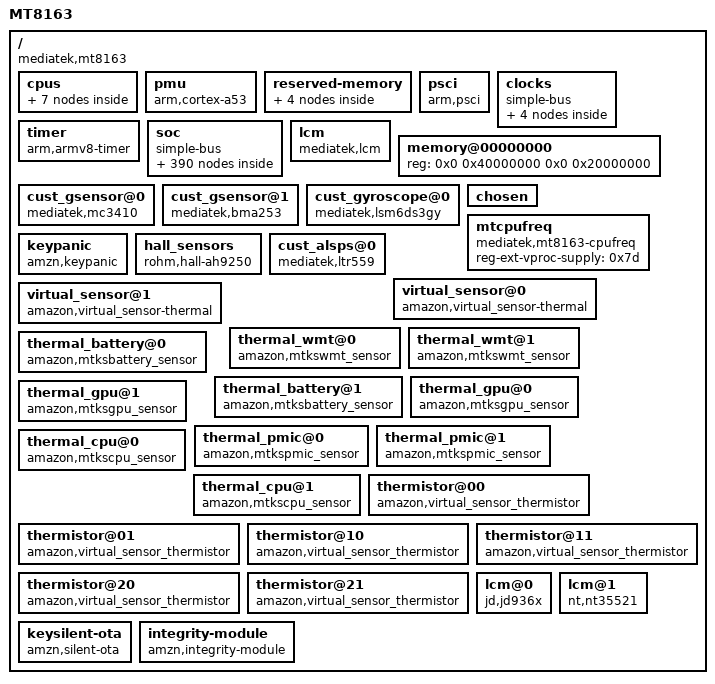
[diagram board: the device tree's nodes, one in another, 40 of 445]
/dts-v1/;

/ {
	model = "MT8163";
	compatible = "mediatek,mt8163";
	interrupt-parent = <0x1>;
	#address-cells = <0x2>;
	#size-cells = <0x2>;
	version = "evt";

	cpus {
		#address-cells = <0x1>;
		#size-cells = <0x0>;

		cpu@0 {
			device_type = "cpu";
			compatible = "arm,cortex-a53";
			reg = <0x0>;
			enable-method = "mt-boot";
			cpu-idle-states = <0x2 0x2 0x3 0x3 0x3>;
			cpu-release-addr = <0x0 0x40000200>;
			clock-frequency = "M|m";
			linux,phandle = <0x4>;
			phandle = <0x4>;
		};

		cpu@1 {
			device_type = "cpu";
			compatible = "arm,cortex-a53";
			reg = <0x1>;
			enable-method = "mt-boot";
			cpu-idle-states = <0x2 0x2 0x3 0x3 0x3>;
			cpu-release-addr = <0x0 0x40000200>;
			clock-frequency = "M|m";
			linux,phandle = <0x5>;
			phandle = <0x5>;
		};

		cpu@2 {
			device_type = "cpu";
			compatible = "arm,cortex-a53";
			reg = <0x2>;
			enable-method = "mt-boot";
			cpu-idle-states = <0x2 0x2 0x3 0x3 0x3>;
			cpu-release-addr = <0x0 0x40000200>;
			clock-frequency = "M|m";
			linux,phandle = <0x6>;
			phandle = <0x6>;
		};

		cpu@3 {
			device_type = "cpu";
			compatible = "arm,cortex-a53";
			reg = <0x3>;
			enable-method = "mt-boot";
			cpu-idle-states = <0x2 0x2 0x3 0x3 0x3>;
			cpu-release-addr = <0x0 0x40000200>;
			clock-frequency = "M|m";
			linux,phandle = <0x7>;
			phandle = <0x7>;
		};

		idle-states {
			entry-method = "arm,psci";

			cpu-sleep-0-0 {
				compatible = "arm,idle-state";
				arm,psci-suspend-param = <0x10000>;
				entry-latency-us = <0x258>;
				exit-latency-us = <0x258>;
				min-residency-us = <0x4b0>;
				linux,phandle = <0x3>;
				phandle = <0x3>;
			};

			cluster-sleep-0 {
				compatible = "arm,idle-state";
				arm,psci-suspend-param = <0x2010000>;
				entry-latency-us = <0x320>;
				exit-latency-us = <0x3e8>;
				min-residency-us = <0x7d0>;
				linux,phandle = <0x2>;
				phandle = <0x2>;
			};
		};
	};

	pmu {
		compatible = "arm,cortex-a53";
		interrupts = <0x0 0x8 0x8 0x0 0x9 0x8 0x0 0xa 0x8 0x0 0xb 0x8>;
		interrupt-affinity = <0x4 0x5 0x6 0x7>;
	};

	reserved-memory {
		#address-cells = <0x2>;
		#size-cells = <0x2>;
		ranges;

		mdump-reserved-memory@4bd00000 {
			compatible = "amazon,mdump-reserve-memory";
			reg = <0x0 0x4bd00000 0x0 0x300000>;
		};

		atf-reserved-memory@43000000 {
			compatible = "mediatek,mt8163-atf-reserved-memory";
			no-map;
			reg = <0x0 0x43000000 0x0 0x30000>;
		};

		ram_console-reserved-memory@44400000 {
			compatible = "mediatek,ram_console";
			reg = <0x0 0x44400000 0x0 0x200000>;
		};

		consys-reserve-memory {
			compatible = "mediatek,consys-reserve-memory";
			no-map;
			size = <0x0 0x200000>;
			alignment = <0x0 0x200000>;
		};
	};

	psci {
		compatible = "arm,psci";
		method = "smc";
		cpu_suspend = <0x84000001>;
		cpu_off = <0x84000002>;
		cpu_on = <0x84000003>;
		affinity_info = <0x84000004>;
	};

	clocks {
		#address-cells = <0x2>;
		#size-cells = <0x2>;
		compatible = "simple-bus";
		ranges;

		clk_null {
			compatible = "fixed-clock";
			#clock-cells = <0x0>;
			clock-frequency = <0x0>;
			linux,phandle = <0x40>;
			phandle = <0x40>;
		};

		clk26m {
			compatible = "fixed-clock";
			#clock-cells = <0x0>;
			clock-frequency = <0x18cba80>;
			linux,phandle = <0x34>;
			phandle = <0x34>;
		};

		clk32k {
			compatible = "fixed-clock";
			#clock-cells = <0x0>;
			clock-frequency = <0x7d00>;
		};

		dummy26m {
			compatible = "fixed-clock";
			clock-frequency = <0x18cba80>;
			#clock-cells = <0x0>;
		};
	};

	timer {
		compatible = "arm,armv8-timer";
		interrupt-parent = <0x8>;
		interrupts = <0x1 0xd 0xf08 0x1 0xe 0xf08 0x1 0xb 0xf08 0x1 0xa 0xf08>;
		clock-frequency = <0xc65d40>;
	};

	soc {
		#address-cells = <0x2>;
		#size-cells = <0x2>;
		compatible = "simple-bus";
		ranges;

		chipid@08000000 {
			compatible = "mediatek,mt8163-chipid";
			reg = <0x0 0x8000000 0x0 0x10>;
		};

		topckgen@10000000 {
			compatible = "mediatek,mt8163-topckgen";
			reg = <0x0 0x10000000 0x0 0x1000>;
			#clock-cells = <0x1>;
			linux,phandle = <0xa>;
			phandle = <0xa>;
		};

		infracfg@10001000 {
			compatible = "mediatek,mt8163-infracfg", "syscon";
			reg = <0x0 0x10001000 0x0 0x1000>;
			#clock-cells = <0x1>;
			#reset-cells = <0x1>;
			linux,phandle = <0x9>;
			phandle = <0x9>;
		};

		syscfg_pctl_a@10005000 {
			compatible = "mediatek,mt8163-pctl-a-syscfg", "syscon";
			reg = <0x0 0x10005000 0x0 0x1000>;
			linux,phandle = <0xb>;
			phandle = <0xb>;
		};

		toprgu@10007000 {
			compatible = "mediatek,mt8163-rgu";
			reg = <0x0 0x10007000 0x0 0x1000>;
			interrupts = <0x0 0x80 0x2>;
			#reset-cells = <0x1>;
		};

		apxgpt@10008000 {
			compatible = "mediatek,mt8163-apxgpt";
			reg = <0x0 0x10008000 0x0 0x1000>;
			interrupts = <0x0 0x98 0x8>;
			clocks = <0x9 0x6 0x9 0x46 0xa 0x60>;
			clock-names = "bus", "clk13m", "rtc_sel";
		};

		pmu {
			compatible = "arm,armv8-pmuv3";
			interrupts = <0x0 0x8 0x8 0x0 0x9 0x8 0x0 0xa 0x8 0x0 0xb 0x8>;
			interrupt-affinity = <0x4 0x5 0x6 0x7>;
		};

		pinctrl@10005000 {
			compatible = "mediatek,mt8163-pinctrl";
			reg = <0x0 0x1000b000 0x0 0x1000>;
			mediatek,pctl-regmap = <0xb>;
			pins-are-numbered;
			gpio-controller;
			#gpio-cells = <0x2>;
			interrupt-controller;
			#interrupt-cells = <0x2>;
			interrupts = <0x0 0x99 0x4 0x0 0x9a 0x4 0x0 0x9b 0x4>;
			pinctrl-names = "default";
			pinctrl-0 = <0xc>;
			linux,phandle = <0xd>;
			phandle = <0xd>;

			spi1 {
				linux,phandle = <0x2d>;
				phandle = <0x2d>;

				pins_spi {
					pinmux = <0x3501 0x3601 0x3701 0x3801>;
					bias-disable;
					drive-strength = <0x2>;
				};
			};

			uart0gpiodefault {
				linux,phandle = <0xf>;
				phandle = <0xf>;
			};

			uart0_rx_set {
				linux,phandle = <0x10>;
				phandle = <0x10>;

				pins_cmd_dat {
					pinmux = <0x4f01>;
				};
			};

			uart0_rx_clear {
				linux,phandle = <0x11>;
				phandle = <0x11>;

				pins_cmd_dat {
					pinmux = <0x4f00>;
					slew-rate = <0x1>;
					output-high;
				};
			};

			uart0_tx_set {
				linux,phandle = <0x12>;
				phandle = <0x12>;

				pins_cmd_dat {
					pinmux = <0x5001>;
				};
			};

			uart0_tx_clear {
				linux,phandle = <0x13>;
				phandle = <0x13>;

				pins_cmd_dat {
					pinmux = <0x5000>;
					slew-rate = <0x1>;
					output-high;
				};
			};

			uart1gpiodefault {
				linux,phandle = <0x14>;
				phandle = <0x14>;
			};

			uart1_rx_set {
				linux,phandle = <0x15>;
				phandle = <0x15>;

				pins_cmd_dat {
					pinmux = <0x5101>;
				};
			};

			uart1_rx_clear {
				linux,phandle = <0x16>;
				phandle = <0x16>;

				pins_cmd_dat {
					pinmux = <0x5100>;
					slew-rate = <0x1>;
					output-high;
				};
			};

			uart1_tx_set {
				linux,phandle = <0x17>;
				phandle = <0x17>;

				pins_cmd_dat {
					pinmux = <0x5201>;
				};
			};

			uart1_tx_clear {
				linux,phandle = <0x18>;
				phandle = <0x18>;

				pins_cmd_dat {
					pinmux = <0x5200>;
					slew-rate = <0x1>;
					output-high;
				};
			};

			uart2gpiodefault {
				linux,phandle = <0x19>;
				phandle = <0x19>;
			};

			uart2_rx_set {
				linux,phandle = <0x1a>;
				phandle = <0x1a>;

				pins_cmd_dat {
					pinmux = <0xe01>;
				};
			};

			uart2_rx_clear {
				linux,phandle = <0x1b>;
				phandle = <0x1b>;

				pins_cmd_dat {
					pinmux = <0xe00>;
					slew-rate = <0x1>;
					output-high;
				};
			};

			uart2_tx_set {
				linux,phandle = <0x1c>;
				phandle = <0x1c>;

				pins_cmd_dat {
					pins = <0xf01>;
				};
			};

			uart2_tx_clear {
				linux,phandle = <0x1d>;
				phandle = <0x1d>;

				pins_cmd_dat {
					pinmux = <0xf00>;
					slew-rate = <0x1>;
					output-high;
				};
			};

			uart3gpiodefault {
				linux,phandle = <0x1e>;
				phandle = <0x1e>;
			};

			uart3_rx_set {
				linux,phandle = <0x1f>;
				phandle = <0x1f>;

				pins_cmd_dat {
					pinmux = <0x1001>;
				};
			};

			uart3_rx_clear {
				linux,phandle = <0x20>;
				phandle = <0x20>;

				pins_cmd_dat {
					pinmux = <0x1000>;
					slew-rate = <0x1>;
					output-high;
				};
			};

			uart3_tx_set {
				linux,phandle = <0x21>;
				phandle = <0x21>;

				pins_cmd_dat {
					pinmux = <0x1101>;
				};
			};

			uart3_tx_clear {
				linux,phandle = <0x22>;
				phandle = <0x22>;

				pins_cmd_dat {
					pinmux = <0x1100>;
					slew-rate = <0x1>;
					output-high;
				};
			};

			pinconf_default {
				linux,phandle = <0xc>;
				phandle = <0xc>;
			};

			eint4default {
				linux,phandle = <0x6c>;
				phandle = <0x6c>;
			};

			rt551x_irq_init {
				linux,phandle = <0x24>;
				phandle = <0x24>;

				pins_cmd_dat {
					pins = <0x1c00>;
					bias-pull-down;
				};
			};

			eint4 {
				linux,phandle = <0x6d>;
				phandle = <0x6d>;

				pins_cmd_dat {
					pins = <0x1a00>;
					bias-disable;
				};
			};

			bq24297_int_pin {
				linux,phandle = <0x28>;
				phandle = <0x28>;

				pins_cmd_dat {
					pinmux = <0x2b00>;
					input-enable;
					bias-pull-up;
				};
			};

			bq24297_chg_en_pin {
				linux,phandle = <0x27>;
				phandle = <0x27>;

				pins_cmd_dat {
					pins = <0x1800>;
					slew-rate = <0x1>;
					bias-disable;
					output-low;
				};
			};

			alspspincfg {
				linux,phandle = <0x75>;
				phandle = <0x75>;

				pins_cmd_dat {
					pins = <0x2000>;
					slew-rate = <0x0>;
					bias-pull-up = <0x0>;
				};
			};

			alspsdefaultcfg {
				linux,phandle = <0x74>;
				phandle = <0x74>;
			};

			audiodefault {
			};

			audexamphigh {
				linux,phandle = <0x3b>;
				phandle = <0x3b>;

				pins_cmd0_dat {
					pins = <0x1e00>;
					slew-rate = <0x1>;
					output-high;
				};

				pins_cmd1_dat {
					pins = <0x1d00>;
					slew-rate = <0x1>;
					output-high;
				};
			};

			audexamplow {
				linux,phandle = <0x3c>;
				phandle = <0x3c>;

				pins_cmd0_dat {
					pins = <0x1e00>;
					slew-rate = <0x1>;
					output-low;
				};

				pins_cmd1_dat {
					pins = <0x1d00>;
					slew-rate = <0x1>;
					output-low;
				};
			};

			audhpamphigh {
				linux,phandle = <0x3d>;
				phandle = <0x3d>;

				pins_cmd_dat {
					pins = <0x1b00>;
					slew-rate = <0x1>;
					output-high;
				};
			};

			audhpamplow {
				linux,phandle = <0x3e>;
				phandle = <0x3e>;

				pins_cmd_dat {
					pins = <0x1b00>;
					slew-rate = <0x1>;
					output-low;
				};
			};

			audexampgain0 {
				linux,phandle = <0x36>;
				phandle = <0x36>;

				pins_cmd_dat {
					pins = <0x8e00>;
					slew-rate = <0x1>;
					output-low;
				};
			};

			audexampgain1 {
				linux,phandle = <0x3f>;
				phandle = <0x3f>;

				pins_cmd_dat {
					pins = <0x8e00>;
					slew-rate = <0x1>;
					output-high;
				};
			};

			audFSA8409off {
				linux,phandle = <0x6e>;
				phandle = <0x6e>;

				pins_cmd_dat {
					pins = <0x8e00>;
					slew-rate = <0x1>;
					output-low;
				};
			};

			audFSA8409on {
				linux,phandle = <0x6f>;
				phandle = <0x6f>;

				pins_cmd_dat {
					pins = <0x8e00>;
					slew-rate = <0x1>;
					output-high;
				};
			};

			audi2s1mode0 {
				linux,phandle = <0x39>;
				phandle = <0x39>;

				pins_cmd0_dat {
					pins = <0x2e00>;
				};

				pins_cmd1_dat {
					pins = <0x2f00>;
				};

				pins_cmd2_dat {
					pins = <0x3000>;
				};
			};

			audi2s1mode1 {
				linux,phandle = <0x3a>;
				phandle = <0x3a>;

				pins_cmd0_dat {
					pins = <0x2e02>;
				};

				pins_cmd1_dat {
					pins = <0x2f02>;
				};

				pins_cmd2_dat {
					pins = <0x3002>;
				};
			};

			pmicclkmode0 {
				linux,phandle = <0x37>;
				phandle = <0x37>;

				pins_cmd0_dat {
					pins = <0x700>;
				};

				pins_cmd1_dat {
					pins = <0x800>;
				};

				pins_cmd2_dat {
					pins = <0x900>;
				};
			};

			pmicclkmode1 {
				linux,phandle = <0x38>;
				phandle = <0x38>;

				pins_cmd0_dat {
					pins = <0x701>;
				};

				pins_cmd1_dat {
					pins = <0x801>;
				};

				pins_cmd2_dat {
					pins = <0x901>;
				};
			};

			camdefault {
				linux,phandle = <0x4e>;
				phandle = <0x4e>;
			};

			cam0@0 {
				linux,phandle = <0x4f>;
				phandle = <0x4f>;

				pins_cmd_dat {
					pins = <0x1200>;
					slew-rate = <0x1>;
					output-low;
				};
			};

			cam0@1 {
				linux,phandle = <0x50>;
				phandle = <0x50>;

				pins_cmd_dat {
					pins = <0x1200>;
					slew-rate = <0x1>;
					output-high;
				};
			};

			cam0@2 {
				linux,phandle = <0x51>;
				phandle = <0x51>;

				pins_cmd_dat {
					pins = <0x1400>;
					slew-rate = <0x1>;
					output-low;
				};
			};

			cam0@3 {
				linux,phandle = <0x52>;
				phandle = <0x52>;

				pins_cmd_dat {
					pins = <0x1400>;
					slew-rate = <0x1>;
					output-high;
				};
			};

			cam1@0 {
				linux,phandle = <0x53>;
				phandle = <0x53>;

				pins_cmd_dat {
					pins = <0x1300>;
					slew-rate = <0x1>;
					output-low;
				};
			};

			cam1@1 {
				linux,phandle = <0x54>;
				phandle = <0x54>;

				pins_cmd_dat {
					pins = <0x1300>;
					slew-rate = <0x1>;
					output-high;
				};
			};

			cam1@2 {
				linux,phandle = <0x55>;
				phandle = <0x55>;

				pins_cmd_dat {
					pins = <0x1500>;
					slew-rate = <0x1>;
					output-low;
				};
			};

			cam1@3 {
				linux,phandle = <0x56>;
				phandle = <0x56>;

				pins_cmd_dat {
					pins = <0x1500>;
					slew-rate = <0x1>;
					output-high;
				};
			};

			cam_pin_rdn0 {
				linux,phandle = <0x58>;
				phandle = <0x58>;

				pins_cmd_dat {
					pins = <0x6501>;
				};
			};

			cam_pin_rdp0 {
				linux,phandle = <0x59>;
				phandle = <0x59>;

				pins_cmd_dat {
					pins = <0x6601>;
				};
			};

			cam_pin_rcn {
				linux,phandle = <0x5a>;
				phandle = <0x5a>;

				pins_cmd_dat {
					pins = <0x6901>;
				};
			};

			cam_pin_rcp {
				linux,phandle = <0x5b>;
				phandle = <0x5b>;

				pins_cmd_dat {
					pins = <0x6a01>;
				};
			};

			cam_pin_rcn_a {
				linux,phandle = <0x5c>;
				phandle = <0x5c>;

				pins_cmd_dat {
					pins = <0x6f01>;
				};
			};

			cam_pin_rcp_a {
				linux,phandle = <0x5d>;
				phandle = <0x5d>;

				pins_cmd_dat {
					pins = <0x7001>;
				};
			};

			cam_pin_rdn0_a {
				linux,phandle = <0x5e>;
				phandle = <0x5e>;

				pins_cmd_dat {
					pins = <0x7301>;
				};
			};

			cam_pin_rdp0_a {
				linux,phandle = <0x5f>;
				phandle = <0x5f>;

				pins_cmd_dat {
					pins = <0x7401>;
				};
			};

			cam_pin_mclk {
				linux,phandle = <0x57>;
				phandle = <0x57>;

				pins_cmd_dat {
					pins = <0x7701>;
				};
			};

			default {
				linux,phandle = <0x63>;
				phandle = <0x63>;
			};

			eint0default {
				linux,phandle = <0x70>;
				phandle = <0x70>;

				pins_cmd_dat {
					pins = <0x1600>;
					slew-rate = <0x0>;
					bias-disable;
				};
			};

			eint@0 {
				linux,phandle = <0x2a>;
				phandle = <0x2a>;

				pins_cmd_dat {
					pins = <0x1600>;
					slew-rate = <0x0>;
					bias-disable;
				};
			};

			eintoutput0 {
				linux,phandle = <0x29>;
				phandle = <0x29>;

				pins_cmd_dat {
					pins = <0x1600>;
					slew-rate = <0x1>;
					output-low;
				};
			};

			eintoutput1 {
				linux,phandle = <0x71>;
				phandle = <0x71>;

				pins_cmd_dat {
					pins = <0x1600>;
					slew-rate = <0x1>;
					output-high;
				};
			};

			rstoutput0 {
				linux,phandle = <0x72>;
				phandle = <0x72>;

				pins_cmd_dat {
					pins = <0x2d00>;
					slew-rate = <0x1>;
					output-low;
				};
			};

			rstoutput1 {
				linux,phandle = <0x73>;
				phandle = <0x73>;

				pins_cmd_dat {
					pins = <0x2d00>;
					slew-rate = <0x1>;
					output-high;
				};
			};

			iddig_irq_init {
				linux,phandle = <0x30>;
				phandle = <0x30>;

				pins_cmd_dat {
					pins = <0x2600>;
					bias-pull-up;
				};
			};

			iddig_irq_low {
				linux,phandle = <0x31>;
				phandle = <0x31>;

				pins_cmd_dat {
					pins = <0x2600>;
					bias-pull-down;
				};
			};

			iddig_irq_high {
				linux,phandle = <0x32>;
				phandle = <0x32>;

				pins_cmd_dat {
					pins = <0x2600>;
					bias-pull-up;
				};
			};

			gpslna@0 {
				linux,phandle = <0x64>;
				phandle = <0x64>;

				pins_cmd_dat {
					pinmux = <0x600>;
					slew-rate = <0x0>;
					bias-disable;
					output-low;
				};
			};

			gpslna@1 {
				linux,phandle = <0x65>;
				phandle = <0x65>;

				pins_cmd_dat {
					pinmux = <0x600>;
					slew-rate = <0x1>;
					output-high;
				};
			};

			gpslna@2 {
				linux,phandle = <0x66>;
				phandle = <0x66>;

				pins_cmd_dat {
					pinmux = <0x600>;
					slew-rate = <0x1>;
					output-low;
				};
			};

			wifireset@0 {
				linux,phandle = <0x67>;
				phandle = <0x67>;

				pins_reset_dat {
					pinmux = <0x3c01 0x3f01 0x4001 0x4101>;
					input-enable;
					bias-pull-up;
				};
			};

			i2c0@0 {
				linux,phandle = <0x23>;
				phandle = <0x23>;

				pins1 {
					pinmux = <0x4b01 0x4c01>;
					bias-disable;
				};
			};

			i2c1@0 {
				linux,phandle = <0x25>;
				phandle = <0x25>;

				pins1 {
					pinmux = <0x3901 0x3a01>;
					bias-disable;
				};
			};

			i2c2@0 {
				linux,phandle = <0x26>;
				phandle = <0x26>;

				pins1 {
					pinmux = <0x4d01 0x4e01>;
					bias-disable;
				};
			};

			lcm_gpio@49_high {
				linux,phandle = <0x76>;
				phandle = <0x76>;

				pins_cmd_dat {
					pins = <0x3100>;
					slew-rate = <0x1>;
					output-high;
				};
			};

			lcm_gpio@49_low {
				linux,phandle = <0x77>;
				phandle = <0x77>;

				pins_cmd_dat {
					pins = <0x3100>;
					slew-rate = <0x1>;
					output-low;
				};
			};

			lcm_gpio@48_high {
				linux,phandle = <0x78>;
				phandle = <0x78>;

				pins_cmd_dat {
					pins = <0x3000>;
					slew-rate = <0x1>;
					output-high;
				};
			};

			lcm_gpio@48_low {
				linux,phandle = <0x79>;
				phandle = <0x79>;

				pins_cmd_dat {
					pins = <0x3000>;
					slew-rate = <0x1>;
					output-low;
				};
			};

			lcm_gpio@50_high {
				linux,phandle = <0x7a>;
				phandle = <0x7a>;

				pins_cmd_dat {
					pins = <0x3200>;
					slew-rate = <0x1>;
					output-high;
				};
			};

			lcm_gpio@50_low {
				linux,phandle = <0x7b>;
				phandle = <0x7b>;

				pins_cmd_dat {
					pins = <0x3200>;
					slew-rate = <0x1>;
					output-low;
				};
			};

			mmc0default {
				linux,phandle = <0x41>;
				phandle = <0x41>;

				pins_cmd_dat {
					pinmux = <0x8901 0x8801 0x8701 0x8601 0x8201 0x8101 0x8001 0x7f01 0x8401>;
					input-enable;
					bias-pull-up;
				};

				pins_clk {
					pinmux = <0x8501>;
					bias-pull-down;
				};

				pins_rst {
					pinmux = <0x8301>;
					bias-pull-up;
				};
			};

			mmc0@0 {
				linux,phandle = <0x42>;
				phandle = <0x42>;

				pins_cmd_dat {
					pinmux = <0x8901 0x8801 0x8701 0x8601 0x8201 0x8101 0x8001 0x7f01 0x8401>;
					input-enable;
					drive-strength = <0x6>;
					bias-pull-up = <0x65>;
				};

				pins_clk {
					pinmux = <0x8501>;
					drive-strength = <0x6>;
					bias-pull-down = <0x65>;
				};

				pins_rst {
					pinmux = <0x8301>;
					bias-pull-up;
				};
			};

			mmc1default {
				linux,phandle = <0x45>;
				phandle = <0x45>;

				pins_cmd_dat {
					pinmux = <0x7b01 0x7c01 0x7d01 0x7e01 0x7901>;
					input-enable;
					drive-strength = <0x6>;
					bias-pull-up = <0x65>;
				};

				pins_clk {
					pinmux = <0x7a01>;
					drive-strength = <0x6>;
					bias-pull-down = <0x66>;
				};

				pins_insert {
					pinmux = <0x3400>;
					bias-pull-up;
				};
			};

			mmc1@0 {
				linux,phandle = <0x46>;
				phandle = <0x46>;

				pins_cmd_dat {
					pinmux = <0x7b01 0x7c01 0x7d01 0x7e01 0x7901>;
					input-enable;
					drive-strength = <0x8>;
					bias-pull-up = <0x66>;
				};

				pins_clk {
					pinmux = <0x7a01>;
					drive-strength = <0x8>;
					bias-pull-down = <0x66>;
				};
			};
		};

		dramco@10004000 {
			compatible = "mediatek,mt8163-dramco", "mediatek,dramco";
			reg = <0x0 0x10004000 0x0 0x1000>;
		};

		scpsys@10006000 {
			compatible = "mediatek,mt8163-scpsys", "syscon";
			#power-domain-cells = <0x1>;
			reg = <0x0 0x10006000 0x0 0x1000>;
			interrupts = <0x0 0xa3 0x8 0x0 0xa4 0x8 0x0 0xa5 0x8 0x0 0xa6 0x8 0x0 0xa7 0x8 0x0 0xa8 0x8 0x0 0xa9 0x8 0x0 0xaa 0x8>;
			infracfg = <0x9>;
			clocks = <0xa 0x46 0xa 0x43>;
			clock-names = "mfg", "mm";
			linux,phandle = <0x35>;
			phandle = <0x35>;
		};

		hacc@1000a000 {
			compatible = "mediatek,hacc";
			reg = <0x0 0x1000a000 0x0 0x1000>;
			clocks = <0x9 0x5>;
			clock-names = "main";
		};

		apmixedsys@1000c000 {
			compatible = "mediatek,mt8163-apmixedsys";
			reg = <0x0 0x1000c000 0x0 0x1000>;
			#clock-cells = <0x1>;
			linux,phandle = <0x2e>;
			phandle = <0x2e>;
		};

		fhctl@1000cf00 {
			compatible = "mediatek,mt8163-fhctl";
			reg = <0x0 0x1000cf00 0x0 0x100>;
		};

		pwrap@1000d000 {
			compatible = "mediatek,mt8163-pwrap";
			reg = <0x0 0x1000d000 0x0 0x1000>;
			reg-names = "pwrap-base";
			interrupts = <0x0 0xa1 0x4>;
			clocks = <0xa 0x51 0x9 0x1>;
			clock-names = "spi", "pwrap";

			mt6323 {
				compatible = "mediatek,mt6323";

				pmicmt6323 {
					compatible = "mediatek,mt6323-pmic";
					interrupt-parent = <0xd>;
					interrupts = <0x18 0x4>;
				};

				regulators {
					compatible = "mediatek,mt6323-regulator";

					buck_vproc {
						regulator-name = "vproc";
						regulator-min-microvolt = <0xaae60>;
						regulator-max-microvolt = <0x149970>;
						regulator-ramp-delay = <0x30d4>;
						regulator-always-on;
						regulator-boot-on;
					};

					buck_vsys {
						regulator-name = "vsys";
						regulator-min-microvolt = <0x155cc0>;
						regulator-max-microvolt = <0x2d95ec>;
						regulator-ramp-delay = <0x61a8>;
						regulator-always-on;
						regulator-boot-on;
					};

					buck_vpa {
						regulator-name = "vpa";
						regulator-min-microvolt = <0x7a120>;
						regulator-max-microvolt = <0x37b1d0>;
					};

					ldo_vtcxo {
						regulator-name = "vtcxo";
						regulator-min-microvolt = <0x2ab980>;
						regulator-max-microvolt = <0x2ab980>;
						regulator-enable-ramp-delay = <0x5a>;
						regulator-always-on;
						regulator-boot-on;
					};

					ldo_vcn28 {
						regulator-name = "vcn28";
						regulator-min-microvolt = <0x2ab980>;
						regulator-max-microvolt = <0x2ab980>;
						regulator-enable-ramp-delay = <0xb9>;
						linux,phandle = <0x69>;
						phandle = <0x69>;
					};

					ldo_vcn33_bt {
						regulator-name = "vcn33_bt";
						regulator-min-microvolt = <0x325aa0>;
						regulator-max-microvolt = <0x36ee80>;
						regulator-enable-ramp-delay = <0xb9>;
						linux,phandle = <0x6a>;
						phandle = <0x6a>;
					};

					ldo_vcn33_wifi {
						regulator-name = "vcn33_wifi";
						regulator-min-microvolt = <0x325aa0>;
						regulator-max-microvolt = <0x36ee80>;
						regulator-enable-ramp-delay = <0xb9>;
						linux,phandle = <0x6b>;
						phandle = <0x6b>;
					};

					ldo_va {
						regulator-name = "va";
						regulator-min-microvolt = <0x2ab980>;
						regulator-max-microvolt = <0x2ab980>;
						regulator-enable-ramp-delay = <0xd8>;
						regulator-always-on;
						regulator-boot-on;
					};

					ldo_vcama {
						regulator-name = "vcama";
						regulator-min-microvolt = <0x16e360>;
						regulator-max-microvolt = <0x2ab980>;
						regulator-enable-ramp-delay = <0xd8>;
						linux,phandle = <0x4b>;
						phandle = <0x4b>;
					};

					ldo_vio28 {
						regulator-name = "vio28";
						regulator-min-microvolt = <0x2ab980>;
						regulator-max-microvolt = <0x2ab980>;
						regulator-enable-ramp-delay = <0xd8>;
						regulator-always-on;
						regulator-boot-on;
					};

					ldo_vusb {
						regulator-name = "vusb";
						regulator-min-microvolt = <0x325aa0>;
						regulator-max-microvolt = <0x325aa0>;
						regulator-enable-ramp-delay = <0xd8>;
						regulator-boot-on;
						linux,phandle = <0x2f>;
						phandle = <0x2f>;
					};

					ldo_vmc {
						regulator-name = "vmc";
						regulator-min-microvolt = <0x1b7740>;
						regulator-max-microvolt = <0x325aa0>;
						regulator-enable-ramp-delay = <0x24>;
						regulator-boot-on;
						linux,phandle = <0x48>;
						phandle = <0x48>;
					};

					ldo_vmch {
						regulator-name = "vmch";
						regulator-min-microvolt = <0x2dc6c0>;
						regulator-max-microvolt = <0x325aa0>;
						regulator-enable-ramp-delay = <0x24>;
						regulator-boot-on;
						linux,phandle = <0x47>;
						phandle = <0x47>;
					};

					ldo_vemc3v3 {
						regulator-name = "vemc3v3";
						regulator-min-microvolt = <0x2dc6c0>;
						regulator-max-microvolt = <0x325aa0>;
						regulator-enable-ramp-delay = <0x24>;
						regulator-boot-on;
						linux,phandle = <0x43>;
						phandle = <0x43>;
					};

					ldo_vgp1 {
						regulator-name = "vgp1";
						regulator-min-microvolt = <0x124f80>;
						regulator-max-microvolt = <0x325aa0>;
						regulator-enable-ramp-delay = <0xd8>;
						linux,phandle = <0x60>;
						phandle = <0x60>;
					};

					ldo_vgp2 {
						regulator-name = "vgp2";
						regulator-min-microvolt = <0x124f80>;
						regulator-max-microvolt = <0x2dc6c0>;
						regulator-enable-ramp-delay = <0xd8>;
						linux,phandle = <0x2b>;
						phandle = <0x2b>;
					};

					ldo_vgp3 {
						regulator-name = "vgp3";
						regulator-min-microvolt = <0x124f80>;
						regulator-max-microvolt = <0x1b7740>;
						regulator-enable-ramp-delay = <0xd8>;
						linux,phandle = <0x7c>;
						phandle = <0x7c>;
					};

					ldo_vcn18 {
						regulator-name = "vcn18";
						regulator-min-microvolt = <0x1b7740>;
						regulator-max-microvolt = <0x1b7740>;
						regulator-enable-ramp-delay = <0xd8>;
						linux,phandle = <0x68>;
						phandle = <0x68>;
					};

					ldo_vsim1 {
						regulator-name = "vsim1";
						regulator-min-microvolt = <0x1b7740>;
						regulator-max-microvolt = <0x2dc6c0>;
						regulator-enable-ramp-delay = <0xd8>;
					};

					ldo_vsim2 {
						regulator-name = "vsim2";
						regulator-min-microvolt = <0x1b7740>;
						regulator-max-microvolt = <0x2dc6c0>;
						regulator-enable-ramp-delay = <0xd8>;
					};

					ldo_vrtc {
						regulator-name = "vrtc";
						regulator-min-microvolt = <0x2ab980>;
						regulator-max-microvolt = <0x2ab980>;
						regulator-always-on;
						regulator-boot-on;
					};

					ldo_vcamaf {
						regulator-name = "vcamaf";
						regulator-min-microvolt = <0x124f80>;
						regulator-max-microvolt = <0x325aa0>;
						regulator-enable-ramp-delay = <0xd8>;
						linux,phandle = <0x2c>;
						phandle = <0x2c>;
					};

					ldo_vibr {
						regulator-name = "vibr";
						regulator-min-microvolt = <0x124f80>;
						regulator-max-microvolt = <0x325aa0>;
						regulator-enable-ramp-delay = <0x24>;
					};

					ldo_vrf18 {
						regulator-name = "vrf18";
						regulator-min-microvolt = <0x1bd8e8>;
						regulator-max-microvolt = <0x1bd8e8>;
						regulator-enable-ramp-delay = <0xbb>;
						regulator-boot-on;
					};

					ldo_vm {
						regulator-name = "vm";
						regulator-min-microvolt = <0x124f80>;
						regulator-max-microvolt = <0x1b7740>;
						regulator-enable-ramp-delay = <0xd8>;
						regulator-always-on;
						regulator-boot-on;
					};

					ldo_vio18 {
						regulator-name = "vio18";
						regulator-min-microvolt = <0x1b7740>;
						regulator-max-microvolt = <0x1b7740>;
						regulator-enable-ramp-delay = <0xd8>;
						regulator-always-on;
						regulator-boot-on;
						linux,phandle = <0x44>;
						phandle = <0x44>;
					};

					ldo_vcamd {
						regulator-name = "vcamd";
						regulator-min-microvolt = <0x124f80>;
						regulator-max-microvolt = <0x1b7740>;
						regulator-enable-ramp-delay = <0xd8>;
						linux,phandle = <0x4c>;
						phandle = <0x4c>;
					};

					ldo_vcamio {
						regulator-name = "vcamio";
						regulator-min-microvolt = <0x1b7740>;
						regulator-max-microvolt = <0x1b7740>;
						regulator-enable-ramp-delay = <0xd8>;
						linux,phandle = <0x4d>;
						phandle = <0x4d>;
					};
				};
			};
		};

		devapc_ao@1000e000 {
			compatible = "mediatek,mt8163-devapc_ao";
			reg = <0x0 0x1000e000 0x0 0x1000>;
		};

		ddrphy@1000f000 {
			compatible = "mediatek,mt8163-ddrphy", "mediatek,ddrphy";
			reg = <0x0 0x1000f000 0x0 0x1000>;
			clocks = <0x9 0x36>;
			clock-names = "dramc_f26m";
		};

		keypad@10010000 {
			compatible = "mediatek,mt8163-keypad";
			reg = <0x0 0x10010000 0x0 0x1000>;
			interrupts = <0x0 0xa2 0x2>;
			mediatek,kpd-key-debounce = <0x400>;
			mediatek,kpd-sw-pwrkey = <0x74>;
			mediatek,kpd-hw-pwrkey = <0x8>;
			mediatek,kpd-sw-rstkey = <0x73>;
			mediatek,kpd-hw-rstkey = <0x11>;
			mediatek,kpd-use-extend-type = <0x0>;
			mediatek,kpd-hw-map-num = <0x48>;
			mediatek,kpd-hw-init-map = <0x72 0x0 0x0 0x0 0x0 0x0 0x0 0x0 0x0 0x0 0x0 0x0 0x0 0x0 0x0 0x0 0x0 0x0 0x0 0x0 0x0 0x0 0x0 0x0 0x0 0x0 0x0 0x0 0x0 0x0 0x0 0x0 0x0 0x0 0x0 0x0 0x0 0x0 0x0 0x0 0x0 0x0 0x0 0x0 0x0 0x0 0x0 0x0 0x0 0x0 0x0 0x0 0x0 0x0 0x0 0x0 0x0 0x0 0x0 0x0 0x0 0x0 0x0 0x0 0x0 0x0 0x0 0x0 0x0 0x0 0x0 0x0>;
			mediatek,kpd-pwrkey-eint-gpio = <0x0>;
			mediatek,kpd-pwkey-gpio-din = <0x0>;
			mediatek,kpd-hw-dl-key0 = <0x0>;
			mediatek,kpd-hw-dl-key1 = <0x11>;
			mediatek,kpd-hw-dl-key2 = <0x8>;
			mediatek,kpd-hw-recovery-key = <0x0>;
			mediatek,kpd-hw-factory-key = <0x11>;
		};

		md32@10020000 {
			compatible = "mediatek,mt8163-md32";
			reg = <0x0 0x10020000 0x0 0x38000 0x0 0x10058000 0x0 0x400 0x0 0x10059000 0x0 0x400>;
			interrupts = <0x0 0xae 0x4>;
			clocks = <0x9 0x4>;
			clock-names = "sys";
			status = "okay";
		};

		mcucfg@10200000 {
			compatible = "mediatek,mt8173-mcucfg", "syscon";
			reg = <0x0 0x10200000 0x0 0x1000>;
		};

		cpuxgpt@10200000 {
			compatible = "mediatek,mt8163-cpuxgpt";
			interrupts = <0x0 0x40 0x4 0x0 0x41 0x4 0x0 0x42 0x4 0x0 0x43 0x4>;
		};

		lastpc@10200000 {
			compatible = "mediatek,mt8163-mcucfg";
			reg = <0x0 0x10200000 0x0 0x200>;
		};

		intpol-controller@10200620 {
			compatible = "mediatek,mt8163-sysirq", "mediatek,mt6577-sysirq";
			interrupt-controller;
			#interrupt-cells = <0x3>;
			interrupt-parent = <0x8>;
			reg = <0x0 0x10200620 0x0 0x20>;
			linux,phandle = <0x1>;
			phandle = <0x1>;
		};

		emi@10203000 {
			compatible = "mediatek,mt8163-emi", "mediatek,emi";
			reg = <0x0 0x10203000 0x0 0x1000>;
			interrupts = <0x0 0x85 0x4>;
		};

		sys_cirq@10204000 {
			compatible = "mediatek,mt8163-sys_cirq", "mediatek,mt6735-sys_cirq";
			reg = <0x0 0x10204000 0x0 0x1000>;
			interrupts = <0x0 0xf0 0x8>;
			mediatek,cirq_num = <0xa9>;
			mediatek,spi_start_offset = <0x48>;
		};

		m4u@10205000 {
			cell-index = <0x0>;
			compatible = "mediatek,mt8163-m4u";
			reg = <0x0 0x10205000 0x0 0x1000>;
			interrupts = <0x0 0x93 0x8>;
		};

		devapc@10207000 {
			compatible = "mediatek,mt8163-devapc";
			reg = <0x0 0x10207000 0x0 0x1000>;
			interrupts = <0x0 0x85 0x8>;
			clocks = <0x9 0x2b>;
			clock-names = "main";
		};

		systracker@10208000 {
			compatible = "mediatek,bus_dbg-v1";
			reg = <0x0 0x10208000 0x0 0x1000>;
			interrupts = <0x0 0x84 0x8>;
		};

		dramc_nao@1020e000 {
			compatible = "mediatek,mt8163-dramc_nao", "mediatek,dramc_nao";
			reg = <0x0 0x1020e000 0x0 0x1000>;
		};

		gcpu@10210000 {
			compatible = "mediatek,mt8163-gcpu";
			reg = <0x0 0x10210000 0x0 0x1000>;
			clocks = <0x9 0x20>;
			clock-names = "main";
		};

		gce@10212000 {
			compatible = "mediatek,mt8163-gce";
			reg = <0x0 0x10212000 0x0 0x1000>;
			interrupts = <0x0 0x8f 0x8 0x0 0x90 0x8>;
			clocks = <0x9 0x9 0xe 0x0 0xe 0x1 0xe 0x2 0xe 0x3 0xe 0x4 0xe 0x5 0xe 0x6 0xe 0x8 0xe 0x7>;
			clock-names = "MT_CG_INFRA_GCE", "MT_CG_DISP0_SMI_COMMON", "MT_CG_DISP0_SMI_LARB0", "MT_CG_DISP0_CAM_MDP", "MT_CG_DISP0_MDP_RDMA0", "MT_CG_DISP0_MDP_RSZ0", "MT_CG_DISP0_MDP_RSZ1", "MT_CG_DISP0_MDP_TDSHP0", "MT_CG_DISP0_MDP_WROT0", "MT_CG_DISP0_MDP_WDMA";
		};

		perisys_iommu@10214000 {
			cell-index = <0x1>;
			compatible = "mediatek,mt8163-perisys_iommu";
			reg = <0x0 0x10214000 0x0 0x1000>;
			interrupts = <0x0 0x91 0x8>;
		};

		interrupt-controller@10221000 {
			compatible = "arm,gic-400";
			interrupt-controller;
			#interrupt-cells = <0x3>;
			interrupt-parent = <0x8>;
			reg = <0x0 0x10221000 0x0 0x1000 0x0 0x10222000 0x0 0x1000 0x0 0x10224000 0x0 0x2000 0x0 0x10226000 0x0 0x2000>;
			interrupts = <0x1 0x9 0xf04>;
			linux,phandle = <0x8>;
			phandle = <0x8>;
		};

		btif_tx@11000700 {
			compatible = "mediatek,btif_tx";
			reg = <0x0 0x11000700 0x0 0x80>;
			interrupts = <0x0 0x6e 0x8>;
		};

		btif_rx@11000780 {
			compatible = "mediatek,btif_rx";
			reg = <0x0 0x11000780 0x0 0x80>;
			interrupts = <0x0 0x6f 0x8>;
		};

		auxadc@11001000 {
			compatible = "mediatek,mt8163-auxadc", "mediatek,mt6735-auxadc";
			reg = <0x0 0x11001000 0x0 0x1000>;
			interrupts = <0x0 0x4c 0x2>;
			clocks = <0x9 0x21>;
			clock-names = "auxadc-main";
			status = "okay";
		};

		uart0@11002000 {
			cell-index = <0x0>;
			compatible = "mediatek,mt8163-uart";
			reg = <0x0 0x11002000 0x0 0x1000 0x0 0x11000300 0x0 0x1000 0x0 0x11000380 0x0 0x80>;
			interrupts = <0x0 0x5b 0x8 0x0 0x66 0x8 0x0 0x67 0x8>;
			clock-frequency = <0x18cba80>;
			clock-div = <0x1>;
			clocks = <0x9 0x13 0x9 0x29>;
			clock-names = "uart0-main", "uart-apdma";
			pinctrl-names = "uart0_gpio_default", "uart0_rx_set", "uart0_rx_clear", "uart0_tx_set", "uart0_tx_clear";
			pinctrl-0 = <0xf>;
			pinctrl-1 = <0x10>;
			pinctrl-2 = <0x11>;
			pinctrl-3 = <0x12>;
			pinctrl-4 = <0x13>;
			rx_gpios = <0xd 0x4f 0x0>;
			tx_gpios = <0xd 0x50 0x0>;
			status = "okay";
		};

		uart1@11003000 {
			cell-index = <0x1>;
			compatible = "mediatek,mt8163-uart";
			reg = <0x0 0x11003000 0x0 0x1000 0x0 0x11000400 0x0 0x80 0x0 0x11000480 0x0 0x80>;
			interrupts = <0x0 0x5c 0x8 0x0 0x68 0x8 0x0 0x69 0x8>;
			clock-frequency = <0x18cba80>;
			clock-div = <0x1>;
			clocks = <0x9 0x14>;
			clock-names = "uart1-main";
			pinctrl-names = "uart1_gpio_default", "uart1_rx_set", "uart1_rx_clear", "uart1_tx_set", "uart1_tx_clear";
			pinctrl-0 = <0x14>;
			pinctrl-1 = <0x15>;
			pinctrl-2 = <0x16>;
			pinctrl-3 = <0x17>;
			pinctrl-4 = <0x18>;
			rx_gpios = <0xd 0x51 0x0>;
			tx_gpios = <0xd 0x52 0x0>;
			status = "disable";
		};

		uart2@11004000 {
			cell-index = <0x2>;
			compatible = "mediatek,mt8163-uart";
			reg = <0x0 0x11004000 0x0 0x1000 0x0 0x11000500 0x0 0x80 0x0 0x11000580 0x0 0x80>;
			interrupts = <0x0 0x5d 0x8 0x0 0x6a 0x8 0x0 0x6b 0x8>;
			clock-frequency = <0x18cba80>;
			clock-div = <0x1>;
			clocks = <0x9 0x15>;
			clock-names = "uart2-main";
			pinctrl-names = "uart2_gpio_default", "uart2_rx_set", "uart2_rx_clear", "uart2_tx_set", "uart2_tx_clear";
			pinctrl-0 = <0x19>;
			pinctrl-1 = <0x1a>;
			pinctrl-2 = <0x1b>;
			pinctrl-3 = <0x1c>;
			pinctrl-4 = <0x1d>;
			rx_gpios = <0xd 0xe 0x0>;
			tx_gpios = <0xd 0xf 0x0>;
			status = "disable";
		};

		uart3@11005000 {
			cell-index = <0x3>;
			compatible = "mediatek,mt8163-uart";
			reg = <0x0 0x11005000 0x0 0x1000 0x0 0x11000600 0x0 0x80 0x0 0x11000680 0x0 0x80>;
			interrupts = <0x0 0x5e 0x8 0x0 0x6c 0x8 0x0 0x6d 0x8>;
			clock-frequency = <0x18cba80>;
			clock-div = <0x1>;
			clocks = <0x9 0x16>;
			clock-names = "uart3-main";
			pinctrl-names = "uart3_gpio_default", "uart3_rx_set", "uart3_rx_clear", "uart3_tx_set", "uart3_tx_clear";
			pinctrl-0 = <0x1e>;
			pinctrl-1 = <0x1f>;
			pinctrl-2 = <0x20>;
			pinctrl-3 = <0x21>;
			pinctrl-4 = <0x22>;
			rx_gpios = <0xd 0x10 0x0>;
			tx_gpios = <0xd 0x11 0x0>;
			status = "disable";
		};

		pwm@11006000 {
			compatible = "mediatek,mt8163-pwm";
			reg = <0x0 0x11006000 0x0 0x1000>;
			interrupts = <0x0 0x4d 0x8>;
			clocks = <0x9 0xf 0x9 0x10 0x9 0x11 0x9 0x12>;
			clock-names = "PWM1-main", "PWM2-main", "PWM3-main", "PWM-main";
		};

		i2c@11007000 {
			compatible = "mediatek,mt8173-i2c";
			reg = <0x0 0x11007000 0x0 0x70 0x0 0x11000180 0x0 0x80>;
			interrupts = <0x0 0x54 0x8>;
			clock-div = <0x8>;
			clocks = <0x9 0xb 0x9 0x29>;
			clock-names = "main", "dma";
			#address-cells = <0x1>;
			#size-cells = <0x0>;
			status = "okay";
			clock-frequency = <0x61a80>;
			pinctrl-names = "default";
			pinctrl-0 = <0x23>;

			kd_camera_hw1@3c {
				compatible = "mediatek,camera_main";
				reg = <0x3c>;
			};

			kd_camera_hw2@21 {
				compatible = "mediatek,camera_sub";
				reg = <0x21>;
			};

			audio-codec@57 {
				compatible = "realtek,rt551x";
				#sound-dai-cells = <0x0>;
				reg = <0x57>;
				interrupt-parent = <0xd>;
				interrupts = <0x6 0x4>;
				rt5518-irq = <0xd 0x1c 0x0>;
				rt5518-reset = <0xd 0x33 0x0>;
				pinctrl-names = "state_eint_as_int";
				pinctrl-0 = <0x24>;
				linux,phandle = <0x33>;
				phandle = <0x33>;
			};

			lcm-bias-power@1f {
				compatible = "ti,tps65132a0yffr";
				reg = <0x1f>;
			};
		};

		i2c@11008000 {
			compatible = "mediatek,mt8173-i2c";
			reg = <0x0 0x11008000 0x0 0x70 0x0 0x11000200 0x0 0x80>;
			interrupts = <0x0 0x55 0x8>;
			clock-div = <0x8>;
			clocks = <0x9 0xc 0x9 0x29>;
			clock-names = "main", "dma";
			#address-cells = <0x1>;
			#size-cells = <0x0>;
			status = "okay";
			clock-frequency = <0x61a80>;
			pinctrl-names = "default";
			pinctrl-0 = <0x25>;

			sym827@60 {
				compatible = "silergy,sym827-regulator";
				reg = <0x60>;
				regulator-name = "vproc";
				regulator-min-microvolt = <0x927c0>;
				regulator-max-microvolt = <0x152bec>;
				regulator-enable-ramp-delay = <0x190>;
				regulator-ramp-delay = <0x208d>;
				regulator-always-on;
				vsel-gpio = <0xd 0x22 0x0>;
				linux,phandle = <0x7d>;
				phandle = <0x7d>;
			};
		};

		i2c@11009000 {
			compatible = "mediatek,mt8173-i2c";
			reg = <0x0 0x11009000 0x0 0x70 0x0 0x11000280 0x0 0x80>;
			interrupts = <0x0 0x56 0x8>;
			clock-div = <0xa>;
			clocks = <0x9 0xd 0x9 0x29>;
			clock-names = "main", "dma";
			#address-cells = <0x1>;
			#size-cells = <0x0>;
			status = "okay";
			clock-frequency = <0x61a80>;
			pinctrl-names = "default";
			pinctrl-0 = <0x26>;

			bq24296@6b {
				compatible = "ti,bq24297";
				reg = <0x6b>;
				interrupt-parent = <0xd>;
				interrupts = <0xb 0x2>;
				pinctrl-names = "bq24297_chg_en", "bq24297_interrupt_init";
				pinctrl-0 = <0x27>;
				pinctrl-1 = <0x28>;
			};

			alsps@23 {
				compatible = "mediatek,alsps";
				reg = <0x23>;
			};

			tmp103-sensor@70 {
				compatible = "ti,tmp103_temp_sensor";
				reg = <0x70>;
				tmp103-sensor,offset = <0x8fc>;
				tmp103-sensor,alpha = <0xa>;
				tmp103-sensor,weight = <0x0>;
			};

			tmp103-sensor@71 {
				compatible = "ti,tmp103_temp_sensor";
				reg = <0x71>;
				tmp103-sensor,offset = <0x2ee>;
				tmp103-sensor,alpha = <0xa>;
				tmp103-sensor,weight = <0x0>;
			};

			tmp103-sensor@72 {
				compatible = "ti,tmp103_temp_sensor";
				reg = <0x72>;
				tmp103-sensor,offset = <0x2ee>;
				tmp103-sensor,alpha = <0xa>;
				tmp103-sensor,weight = <0x0>;
			};

			g_sensor@4c {
				compatible = "mediatek,gsensor";
				reg = <0x4c>;
			};

			g_sensor@18 {
				compatible = "mediatek,bma_gsensor";
				reg = <0x18>;
			};

			gyro_sensor@6c {
				compatible = "mediatek,gyro_sensor";
				reg = <0x6c>;
			};

			goodix_ts@5d {
				compatible = "goodix,gt9xx";
				reg = <0x5d>;
				pinctrl-names = "irq_as_gpio", "irq_as_int";
				pinctrl-0 = <0x29>;
				pinctrl-1 = <0x2a>;
				vdd_ana-supply = <0x2b>;
				vcc_i2c-supply = <0x2c>;
				goodix,rst-gpio = <0xd 0x2d 0x0>;
				goodix,irq-gpio = <0xd 0x16 0x0>;
				goodix,cfg-group0 = [41 20 03 00 05 0a 35 00 01 00 1e 0a 50 28 0a 05 00 00 00 00 00 00 03 18 1b 1e 14 90 30 aa 30 32 eb 17 00 00 01 02 03 10 00 00 00 00 00 00 00 00 00 00 00 19 41 94 c5 02 07 00 00 04 9a 1b 00 8f 21 00 7e 28 00 70 31 00 65 3b 00 65 00 00 00 00 00 00 00 00 00 00 00 00 00 00 00 00 00 00 00 00 00 00 00 00 00 00 00 00 00 00 01 02 00 00 00 00 00 01 04 05 06 07 08 09 0c 0d 0e 0f 10 11 14 15 16 17 18 19 00 00 00 00 ff ff ff ff ff ff 00 02 04 06 07 08 0a 0c 0d 0e 0f 10 11 12 13 14 19 1b 1c 1e 1f 20 21 22 23 24 25 26 27 28 29 2a ff ff ff ff ff ff ff ff ff ff 19 01];
				goodix,cfg-group1 = [42 20 03 00 05 0a 35 00 01 08 1e 0f 50 32 01 05 00 00 00 00 13 14 00 17 1a 20 14 95 33 de 2a 2c 7f 1b 00 00 00 dc 03 1d 00 00 00 00 00 00 00 00 00 00 00 23 37 81 e0 01 00 0a 00 04 79 24 00 77 28 00 76 2b 00 76 30 00 76 34 00 76 00 00 00 00 00 00 00 00 00 00 00 00 00 00 00 00 00 00 00 00 00 00 00 00 00 00 00 00 00 20 00 00 00 00 00 00 18 17 14 13 10 0f 0c 0b 08 07 04 03 00 01 02 05 06 09 0a 0d 0e 11 12 15 16 19 1a ff ff ff 00 01 02 03 04 05 06 07 08 09 0a 0b 0c 0d 0e 0f 10 11 12 13 14 15 16 17 18 19 1b 1c 1d 1e 1f 20 21 22 23 25 24 26 28 27 ff ff 7a 01];
				goodix,cfg-group2 = [44 20 03 00 05 0a 35 00 01 08 1e 0f 50 32 01 05 00 00 00 00 13 13 00 18 1c 20 14 95 33 de 30 32 eb 17 00 00 00 bb 03 1c 00 00 00 00 00 00 00 00 00 00 00 23 37 81 e0 01 00 0a 00 04 92 24 00 8a 28 00 85 2b 00 7f 30 00 7d 34 00 7d 00 00 00 00 00 00 00 00 00 00 00 00 00 00 00 00 00 00 00 00 1e 00 00 00 00 00 00 00 00 00 00 00 00 00 00 00 18 17 14 13 10 0f 0c 0b 08 07 04 03 00 01 02 05 06 09 0a 0d 0e 11 12 15 16 19 1a ff ff ff 00 01 02 03 04 05 06 07 08 09 0a 0b 0c 0d 0e 0f 10 11 12 13 14 15 16 17 18 19 1b 1c 1d 1e 1f 20 21 22 23 25 24 26 28 27 ff ff d4 01];
				goodix,cfg-group3 = [42 20 03 00 05 0a 35 00 01 08 1e 0f 50 32 01 05 00 00 00 00 13 14 00 17 1a 20 14 95 33 de 2a 2c 7f 1b 00 00 00 dc 03 1d 00 00 00 00 00 00 00 00 00 00 00 23 37 81 e0 01 00 0a 00 04 79 24 00 77 28 00 76 2b 00 76 30 00 76 34 00 76 00 00 00 00 00 00 00 00 00 00 00 00 00 00 00 00 00 00 00 00 00 00 00 00 00 00 00 00 00 20 00 00 00 00 00 00 18 17 14 13 10 0f 0c 0b 08 07 04 03 00 01 02 05 06 09 0a 0d 0e 11 12 15 16 19 1a ff ff ff 00 01 02 03 04 05 06 07 08 09 0a 0b 0c 0d 0e 0f 10 11 12 13 14 15 16 17 18 19 1b 1c 1d 1e 1f 20 21 22 23 25 24 26 28 27 ff ff 7a 01];
				goodix,cfg-group5 = [46 20 03 00 05 0a 35 00 01 08 1e 0f 50 32 01 05 00 00 00 00 13 14 00 17 1a 20 14 95 33 de 2a 2c 7f 1b 00 00 00 dc 03 1c 00 00 00 00 00 00 00 00 00 00 00 23 37 81 e0 01 00 0a 00 04 83 24 00 81 28 00 80 2b 00 80 30 00 80 34 00 80 00 00 00 00 00 00 00 00 00 00 00 00 00 00 00 00 00 00 00 00 1e 00 00 00 00 00 00 00 00 20 00 00 00 00 00 00 18 17 14 13 10 0f 0c 0b 08 07 04 03 00 01 02 05 06 09 0a 0d 0e 11 12 15 16 19 1a ff ff ff 00 01 02 03 04 05 06 07 08 09 0a 0b 0c 0d 0e 0f 10 11 12 13 14 15 16 17 18 19 1b 1c 1d 1e 1f 20 21 22 23 25 24 26 28 27 ff ff 1d 01];
			};
		};

		spi@1100a000 {
			compatible = "mediatek,mt8163-spi";
			#address-cells = <0x1>;
			#size-cells = <0x0>;
			reg = <0x0 0x1100a000 0x0 0x1000>;
			interrupts = <0x0 0x76 0x8>;
			clocks = <0xa 0x29 0xa 0x49 0x9 0x1b 0x9 0x41>;
			clock-names = "parent-clk", "sel-clk", "spi-clk", "dcm-sel-clk";
			pinctrl-names = "default";
			pinctrl-0 = <0x2d>;
			status = "okay";
			mediatek,pad-select = <0x0>;

			audio-codec@0 {
				compatible = "realtek,rt551x";
				reg = <0x0>;
				spi-max-frequency = <0x112a880>;
			};
		};

		thermal@1100b000 {
			compatible = "mediatek,mt8163-thermal";
			reg = <0x0 0x1100b000 0x0 0x1000>;
			interrupts = <0x0 0x4e 0x8>;
			clocks = <0x9 0xa 0x9 0x21>;
			clock-names = "therm", "auxadc";
			apmixedsys = <0x2e>;
		};

		ptp_od@1100b000 {
			compatible = "mediatek,mt8163-ptp_od";
			reg = <0x0 0x1100b000 0x0 0x1000>;
			interrupts = <0x0 0x7d 0x8>;
			clocks = <0x9 0xa>;
			clock-names = "ptp_infra_therm";
		};

		btif@1100c000 {
			compatible = "mediatek,btif";
			reg = <0x0 0x1100c000 0x0 0x1000>;
			interrupts = <0x0 0x70 0x8>;
			clocks = <0x9 0x1a 0x9 0x29>;
			clock-names = "btifc", "apdmac";
		};

		usb@11200000 {
			compatible = "mediatek,mt8163-usb20";
			reg = <0x0 0x11200000 0x0 0x10000 0x0 0x11210000 0x0 0x10000>;
			interrupts = <0x0 0x48 0x8>;
			mode = <0x2>;
			multipoint = <0x1>;
			dyn_fifo = <0x1>;
			soft_con = <0x1>;
			dma = <0x1>;
			num_eps = <0x10>;
			dma_channels = <0x8>;
			clocks = <0x2e 0x2 0x9 0x17 0x9 0x7>;
			clock-names = "usbpll", "usbmcu", "usb";
			vusb-supply = <0x2f>;
			pinctrl-names = "iddig_irq_init", "iddig_irq_low", "iddig_irq_high";
			pinctrl-0 = <0x30>;
			pinctrl-1 = <0x31>;
			pinctrl-2 = <0x32>;
			iddig_gpio = <0xd 0x26 0x0>;
			status = "okay";
		};

		usb@11270000 {
			compatible = "mediatek,mt8163-usb11";
			cell-index = <0x1>;
			reg = <0x0 0x11270000 0x0 0x10000 0x0 0x11210000 0x0 0x10000>;
			interrupts = <0x0 0x49 0x8>;
			mode = <0x2>;
			multipoint = <0x1>;
			dyn_fifo = <0x1>;
			soft_con = <0x1>;
			dma = <0x1>;
			num_eps = <0x8>;
			dma_channels = <0x4>;
			clocks = <0x2e 0x2 0x9 0x17 0x9 0x8>;
			clock-names = "usbpll", "usbmcu", "icusb";
			status = "disabled";
		};

		audiosys@11220000 {
			compatible = "mediatek,mt8163-audiosys", "syscon";
			reg = <0x0 0x11220000 0x0 0x1000>;
			#clock-cells = <0x1>;
			channel-type = <0x0>;
			switch-mode-delay = <0x1>;
			sound-dai = <0x33>;
		};

		mt_soc_dl1_pcm@11220000 {
			compatible = "mediatek,mt8163-soc-pcm-dl1";
			reg = <0x0 0x11220000 0x0 0x1000 0x0 0x11221000 0x0 0x9000>;
			interrupts = <0x0 0x8e 0x8>;
			clocks = <0x9 0x30 0xa 0x4f 0xa 0x50 0xa 0x57 0xa 0x58 0x2e 0x8 0x2e 0x9 0x34>;
			clock-names = "aud_infra_clk", "top_mux_audio", "top_mux_audio_intbus", "aud_mux1_clk", "aud_mux2_clk", "apmixed_apll1_clk", "apmixed_apll2_clk", "top_clk26m_clk";
			audclk-gpio = <0x7 0x0>;
			audmiso-gpio = <0x8 0x0>;
			audmosi-gpio = <0x9 0x0>;
			extspkamp-gpio = <0x18 0x0>;
			i2s1clk-gpio = <0x30 0x0>;
			i2s1dat-gpio = <0x2e 0x0>;
			i2s1mclk-gpio = <0xf 0x0>;
			i2s1ws-gpio = <0x2f 0x0>;
			power-domains = <0x35 0x5>;
			pinctrl-names = "default", "audpmicclk-mode0", "audpmicclk-mode1", "audi2s1-mode0", "audi2s1-mode1", "extamp-pullhigh", "extamp-pulllow", "hpamp-pullhigh", "hpamp-pulllow", "extamp-gain0", "extamp-gain1";
			pinctrl-0 = <0x36>;
			pinctrl-1 = <0x37>;
			pinctrl-2 = <0x38>;
			pinctrl-3 = <0x39>;
			pinctrl-4 = <0x3a>;
			pinctrl-5 = <0x3b>;
			pinctrl-6 = <0x3c>;
			pinctrl-7 = <0x3d>;
			pinctrl-8 = <0x3e>;
			pinctrl-9 = <0x36>;
			pinctrl-10 = <0x3f>;
			status = "okay";
		};

		mt_soc_ul1_pcm@11220000 {
			compatible = "mediatek,mt8163-soc-pcm-capture";
		};

		mt_soc_voice_md1@11220000 {
			compatible = "mediatek,mt8163-soc-pcm-voice-md1";
		};

		mt_soc_hdmi_pcm@11220000 {
			compatible = "mediatek,mt8163-soc-pcm-hdmi";
		};

		mt_soc_uldlloopback@11220000 {
			compatible = "mediatek,mt8163-soc-pcm-uldlloopback";
		};

		mt_soc_i2s0_pcm@11220000 {
			compatible = "mediatek,mt8163-soc-pcm-dl1-i2s0";
		};

		mt_soc_mrgrx_pcm@11220000 {
			compatible = "mediatek,mt8163-soc-pcm-mrgrx";
		};

		mt_soc_mrgrx_awb_pcm@11220000 {
			compatible = "mediatek,mt8163-soc-pcm-mrgrx-awb";
		};

		mt_soc_fm_i2s_pcm@11220000 {
			compatible = "mediatek,mt8163-soc-pcm-fm-i2s";
		};

		mt_soc_fm_i2s_awb_pcm@11220000 {
			compatible = "mediatek,mt8163-soc-pcm-fm-i2s-awb";
		};

		mt_soc_i2s0dl1_pcm@11220000 {
			compatible = "mediatek,mt8163-soc-pcm-dl1-i2s0Dl1";
		};

		mt_soc_dl1_awb_pcm@11220000 {
			compatible = "mediatek,mt8163-soc-pcm-dl1-awb";
		};

		mt_soc_voice_md1_bt@11220000 {
			compatible = "mediatek,mt8163-soc-pcm-voice-md1-bt";
		};

		mt_soc_voip_bt_out@11220000 {
			compatible = "mediatek,mt8163-soc-pcm-dl1-bt";
		};

		mt_soc_voip_bt_in@11220000 {
			compatible = "mediatek,mt8163-soc-pcm-bt-dai";
		};

		mt_soc_tdmrx_pcm@11220000 {
			compatible = "mediatek,mt8163-soc-tdm-capture";
		};

		mt_soc_fm_mrgtx_pcm@11220000 {
			compatible = "mediatek,mt8163-soc-pcm-fmtx";
		};

		mt_soc_ul2_pcm@11220000 {
			compatible = "mediatek,mt8163-soc-pcm-capture2";
		};

		mt_soc_i2s0_awb_pcm@11220000 {
			compatible = "mediatek,mt8163-soc-pcm-i2s0-awb";
		};

		mt_soc_voice_md2@11220000 {
			compatible = "mediatek,mt8163-soc-pcm-voice-md2";
		};

		mt_soc_routing_pcm@11220000 {
			compatible = "mediatek,mt8163-soc-pcm-routing";
		};

		mt_soc_voice_md2_bt@11220000 {
			compatible = "mediatek,mt8163-soc-pcm-voice-md2-bt";
		};

		mt_soc_hp_impedance@11220000 {
			compatible = "mediatek,mt8163-soc-pcm-hp-impedance";
		};

		mt_soc_codec_name@11220000 {
			compatible = "mediatek,mt8163-soc-codec-63xx";
		};

		mt_soc_dummy_pcm@11220000 {
			compatible = "mediatek,mt8163-soc-pcm-dummy";
		};

		mt_soc_codec_dummy_name@11220000 {
			compatible = "mediatek,mt8163-soc-codec-dummy";
		};

		mt_soc_routing_dai_name@11220000 {
			compatible = "mediatek,mt8163-soc-dai-routing";
		};

		mt_soc_dai_name@11220000 {
			compatible = "mediatek,mt8163-soc-dai-stub";
		};

		mfg@13000000 {
			compatible = "mediatek,mt8163-mfg", "mediatek,midgard-mfg";
			reg = <0x0 0x13000000 0x0 0x1000>;
			clocks = <0xa 0x46 0xa 0x18>;
			clock-names = "topck", "pll";
		};

		gpu@13040000 {
			compatible = "arm,malit720", "arm,mali-t72x", "arm,malit7xx", "arm,mali-midgard";
			reg = <0x0 0x13040000 0x0 0x4000>;
			interrupts = <0x0 0xe3 0x8 0x0 0xe2 0x8 0x0 0xe1 0x8>;
			interrupt-names = "JOB", "MMU", "GPU";
			clock-frequency = <0x1efe9200>;
			power-domains = <0x35 0x7>;
		};

		mmc@11230000 {
			compatible = "mediatek,mt8163-mmc";
			reg = <0x0 0x11230000 0x0 0x1000>;
			interrupts = <0x0 0x4f 0x8>;
			infracfg = <0x9>;
			clocks = <0x9 0x1c 0x9 0x1f 0x40>;
			clock-names = "extra", "source", "hclk";
			status = "okay";
			pinctrl-names = "default", "state_uhs";
			pinctrl-0 = <0x41>;
			pinctrl-1 = <0x42>;
			bus-width = <0x8>;
			latch-ck = <0x1>;
			max-frequency = <0xbebc200>;
			cap-mmc-highspeed;
			mmc-hs200-1_8v;
			cap-mmc-hw-reset;
			vmmc-supply = <0x43>;
			vqmmc-supply = <0x44>;
			non-removable;
		};

		mmc@11240000 {
			compatible = "mediatek,mt8163-mmc";
			reg = <0x0 0x11240000 0x0 0x1000>;
			interrupts = <0x0 0x50 0x8>;
			clocks = <0x9 0x1d 0xa 0x4b 0x40>;
			clock-names = "sd_extra", "source", "hclk";
			status = "okay";
			pinctrl-names = "default", "state_uhs";
			pinctrl-0 = <0x45>;
			pinctrl-1 = <0x46>;
			bus-width = <0x4>;
			latch-ck = <0x1>;
			max-frequency = <0xbebc200>;
			cap-sd-highspeed;
			sd-uhs-sdr50;
			sd-uhs-sdr104;
			cd-gpios = <0xd 0x34 0x0>;
			vmmc-supply = <0x47>;
			vqmmc-supply = <0x48>;
		};

		mmsys@14000000 {
			compatible = "mediatek,mt8163-mmsys", "syscon";
			reg = <0x0 0x14000000 0x0 0x1000>;
			#clock-cells = <0x1>;
			linux,phandle = <0xe>;
			phandle = <0xe>;
		};

		mdp_rdma@14001000 {
			compatible = "mediatek,mt8163-mdp_rdma";
			reg = <0x0 0x14001000 0x0 0x1000>;
			interrupts = <0x0 0xb2 0x8>;
		};

		mdp_rsz0@14002000 {
			compatible = "mediatek,mt8163-mdp_rsz0";
			reg = <0x0 0x14002000 0x0 0x1000>;
			interrupts = <0x0 0xb3 0x8>;
		};

		mdp_rsz1@14003000 {
			compatible = "mediatek,mt8163-mdp_rsz1";
			reg = <0x0 0x14003000 0x0 0x1000>;
			interrupts = <0x0 0xb4 0x8>;
		};

		mdp_wdma@14004000 {
			compatible = "mediatek,mt8163-mdp_wdma";
			reg = <0x0 0x14004000 0x0 0x1000>;
			interrupts = <0x0 0xb6 0x8>;
		};

		mdp_wrot@14005000 {
			compatible = "mediatek,mt8163-mdp_wrot";
			reg = <0x0 0x14005000 0x0 0x1000>;
			interrupts = <0x0 0xb7 0x8>;
		};

		mdp_tdshp@14006000 {
			compatible = "mediatek,mt8163-mdp_tdshp0";
			reg = <0x0 0x14006000 0x0 0x1000>;
			interrupts = <0x0 0xb5 0x8>;
		};

		mt8163-dispsys {
			compatible = "mediatek,mt8163-dispsys";
		};

		disp_ovl0@14007000 {
			compatible = "mediatek,mt8163-disp_ovl0";
			reg = <0x0 0x14007000 0x0 0x1000>;
			interrupts = <0x0 0xb8 0x8>;
		};

		disp_ovl1@14008000 {
			compatible = "mediatek,mt8163-disp_ovl1";
			reg = <0x0 0x14008000 0x0 0x1000>;
			interrupts = <0x0 0xb9 0x8>;
		};

		disp_rdma0@14009000 {
			compatible = "mediatek,mt8163-disp_rdma0";
			reg = <0x0 0x14009000 0x0 0x1000>;
			interrupts = <0x0 0xba 0x8>;
		};

		disp_rdma1@1400a000 {
			compatible = "mediatek,mt8163-disp_rdma1";
			reg = <0x0 0x1400a000 0x0 0x1000>;
			interrupts = <0x0 0xbb 0x8>;
		};

		disp_wdma0@1400b000 {
			compatible = "mediatek,mt8163-disp_wdma0";
			reg = <0x0 0x1400b000 0x0 0x1000>;
			interrupts = <0x0 0xbc 0x8>;
		};

		disp_color@1400c000 {
			compatible = "mediatek,mt8163-disp_color";
			reg = <0x0 0x1400c000 0x0 0x1000>;
			interrupts = <0x0 0xbd 0x8>;
		};

		disp_ccorr@1400d000 {
			compatible = "mediatek,mt8163-disp_ccorr";
			reg = <0x0 0x1400d000 0x0 0x1000>;
			interrupts = <0x0 0xbe 0x8>;
		};

		disp_aal@1400e000 {
			compatible = "mediatek,mt8163-disp_aal";
			reg = <0x0 0x1400e000 0x0 0x1000>;
			interrupts = <0x0 0xbf 0x8>;
		};

		disp_gamma@1400f000 {
			compatible = "mediatek,mt8163-disp_gamma";
			reg = <0x0 0x1400f000 0x0 0x1000>;
			interrupts = <0x0 0xc0 0x8>;
		};

		disp_dither@14010000 {
			compatible = "mediatek,mt8163-disp_dither";
			reg = <0x0 0x14010000 0x0 0x1000>;
			interrupts = <0x0 0xc1 0x8>;
		};

		disp_ufoe@14011000 {
			compatible = "mediatek,mt8163-disp_ufoe";
			reg = <0x0 0x14011000 0x0 0x1000>;
		};

		disp_dsi0@14012000 {
			compatible = "mediatek,mt8163-disp_dsi0";
			reg = <0x0 0x14012000 0x0 0x1000>;
			interrupts = <0x0 0xc3 0x8>;
		};

		disp_dpi0@14013000 {
			compatible = "mediatek,mt8163-disp_dpi0";
			reg = <0x0 0x14013000 0x0 0x1000>;
			interrupts = <0x0 0xc4 0x8>;
		};

		disp_dpi1@1401c000 {
			compatible = "mediatek,mt8163-disp_dpi1";
			reg = <0x0 0x1401c000 0x0 0x1000>;
			interrupts = <0x0 0xc9 0x8>;
		};

		disp_pwm0@14014000 {
			compatible = "mediatek,mt8163-disp_pwm";
			reg = <0x0 0x14014000 0x0 0x1000>;
		};

		mm_mutex@14015000 {
			compatible = "mediatek,mt8163-disp_mutex";
			reg = <0x0 0x14015000 0x0 0x1000>;
			interrupts = <0x0 0xb1 0x8>;
		};

		disp_wdma1@14018000 {
			compatible = "mediatek,mt8163-disp_wdma1";
			reg = <0x0 0x14018000 0x0 0x1000>;
			interrupts = <0x0 0xc6 0x8>;
		};

		disp_config2@10206000 {
			compatible = "mediatek,mt8163-disp_config2";
			reg = <0x0 0x10206000 0x0 0x1000>;
		};

		disp_config3@10000000 {
			compatible = "mediatek,mt8163-disp_config3";
			reg = <0x0 0x10000000 0x0 0x1000>;
		};

		disp_mipi@10215000 {
			compatible = "mediatek,mt8163-disp_mipi";
			reg = <0x0 0x10215000 0x0 0x1000>;
		};

		disp_io_driving@10005000 {
			compatible = "mediatek,mt8163-disp_io_driving";
			reg = <0x0 0x10005000 0x0 0x1000>;
		};

		disp_tvdpll_cfg6@100000a0 {
			compatible = "mediatek,mt8163-disp_tvdpll_cfg6";
			reg = <0x0 0x100000a0 0x0 0x1000>;
		};

		disp_tvdpll_con0@1000c270 {
			compatible = "mediatek,mt8163-disp_tvdpll_con0";
			reg = <0x0 0x1000c270 0x0 0x1000>;
		};

		disp_tvdpll_con1@1000c274 {
			compatible = "mediatek,mt8163-disp_tvdpll_con1";
			reg = <0x0 0x1000c274 0x0 0x1000>;
		};

		disp_lvds_ana@10215800 {
			compatible = "mediatek,mt8163-disp_lvds_ana";
			reg = <0x0 0x10215800 0x0 0x1000>;
		};

		g3d_iommu@13005000 {
			cell-index = <0x2>;
			compatible = "mediatek,mt8163-g3d_iommu";
			reg = <0x0 0x13005000 0x0 0x1000>;
			interrupts = <0x0 0xe2 0x8>;
		};

		larb@14016000 {
			compatible = "mediatek,mt8163-smi-larb";
			reg = <0x0 0x14016000 0x0 0x1000>;
			interrupts = <0x0 0xcd 0x8>;
			mediatek,smi = <0x49>;
			mediatek,larbid = <0x0>;
			clocks = <0xe 0x1 0xe 0x1>;
			clock-names = "apb", "smi";
			power-domains = <0x35 0x0>;
		};

		smi@14017000 {
			compatible = "mediatek,mt8163-smi";
			reg = <0x0 0x14017000 0x0 0x1000 0x0 0x14000100 0x0 0x10>;
			reg-names = "", "mmsys_cg_con0_base";
			clocks = <0xe 0x0 0xe 0x0>;
			clock-names = "apb", "smi";
			power-domains = <0x35 0x0>;
			linux,phandle = <0x49>;
			phandle = <0x49>;
		};

		disp_lvds_tx@1401b200 {
			compatible = "mediatek,mt8163-disp_lvds_tx";
			reg = <0x0 0x1401b200 0x0 0x1000>;
		};

		hdmi@1401d000 {
			compatible = "mediatek,mt8163-hdmitx";
			power-domains = <0x35 0x0>;
			reg = <0x0 0x1401d000 0x0 0x390 0x0 0x1100f000 0x0 0x10 0x0 0x10013000 0x0 0xbc>;
			interrupts = <0x0 0xca 0x8>;
			clocks = <0x9 0x25 0x9 0x26 0xe 0x2a 0xe 0x2d 0xe 0x2c 0xe 0x2b>;
			clock-names = "cec_pdn", "clk_cec_26m", "mmsys_hdmi_pll", "mmsys_hdmi_pixel", "mmsys_hdmi_audio", "mmsys_hdmi_spidif";
		};

		imgsys@15000000 {
			compatible = "mediatek,mt8163-imgsys", "syscon";
			reg = <0x0 0x15000000 0x0 0x1000>;
			#clock-cells = <0x1>;
			linux,phandle = <0x4a>;
			phandle = <0x4a>;
		};

		isp_display {
			compatible = "mediatek,mt8163-isp_display";
		};

		ispsys@15000000 {
			compatible = "mediatek,mt8163-ispsys";
			reg = <0x0 0x15004000 0x0 0x9000 0x0 0x15000000 0x0 0x10000 0x0 0x10217000 0x0 0x3000>;
			interrupts = <0x0 0xda 0x8 0x0 0xdb 0x8>;
			clocks = <0x4a 0x0 0x4a 0x2 0x4a 0x3 0x4a 0x4 0x4a 0x5 0x4a 0x6 0xe 0x0>;
			clock-names = "IMG_LARB2_SMI", "IMG_CAM_SMI", "IMG_CAM_CAM", "IMG_SEN_TG", "IMG_SEN_CAM", "IMG_CAM_SV", "MM_SMI_COMMON";
		};

		larb@15001000 {
			compatible = "mediatek,mt8163-smi-larb";
			reg = <0x0 0x15001000 0x0 0x1000>;
			interrupts = <0x0 0xd9 0x8>;
			mediatek,smi = <0x49>;
			mediatek,larbid = <0x2>;
			clocks = <0x4a 0x0 0x4a 0x0>;
			clock-names = "apb", "smi";
			power-domains = <0x35 0x3>;
		};

		camera1@15008000 {
			compatible = "mediatek,mt8163-camera_hw";
			reg = <0x0 0x15008000 0x0 0x1000>;
			clocks = <0xa 0x47 0xa 0x36 0xa 0x39>;
			clock-names = "TOP_CAMTG_SEL", "TOP_UNIVPLL_D26", "TOP_UNIVPLL2_D2";
			reg-vcama-supply = <0x4b>;
			reg-vcamd-supply = <0x4c>;
			reg-vcamio-supply = <0x4d>;
			reg-vcamaf-supply = <0x2c>;
			reg-vcami2c-supply = <0x44>;
			pinctrl-names = "default", "cam0_rst0", "cam0_rst1", "cam0_pnd0", "cam0_pnd1", "cam1_rst0", "cam1_rst1", "cam1_pnd0", "cam1_pnd1", "cam_mclk", "cam0_rdn0", "cam0_rdp0", "cam0_rcn", "cam0_rcp", "cam1_rcn_a", "cam1_rcp_a", "cam1_rdn0_a", "cam1_rdp0_a";
			pinctrl-0 = <0x4e>;
			pinctrl-1 = <0x4f>;
			pinctrl-2 = <0x50>;
			pinctrl-3 = <0x51>;
			pinctrl-4 = <0x52>;
			pinctrl-5 = <0x53>;
			pinctrl-6 = <0x54>;
			pinctrl-7 = <0x55>;
			pinctrl-8 = <0x56>;
			pinctrl-9 = <0x57>;
			pinctrl-10 = <0x58>;
			pinctrl-11 = <0x59>;
			pinctrl-12 = <0x5a>;
			pinctrl-13 = <0x5b>;
			pinctrl-14 = <0x5c>;
			pinctrl-15 = <0x5d>;
			pinctrl-16 = <0x5e>;
			pinctrl-17 = <0x5f>;
			status = "okay";
		};

		camera2@15008000 {
			compatible = "mediatek,mt8163-camera_hw2";
			reg = <0x0 0x15008000 0x0 0x1000>;
			reg-vcama-supply = <0x4b>;
			reg-vcamd-supply = <0x60>;
			reg-vcamio-supply = <0x4d>;
			reg-vcamaf-supply = <0x2c>;
			reg-vcami2c-supply = <0x44>;
		};

		vdecsys@16000000 {
			compatible = "mediatek,mt8163-vdecsys", "syscon";
			reg = <0x0 0x16000000 0x0 0x1000>;
			#clock-cells = <0x1>;
			linux,phandle = <0x61>;
			phandle = <0x61>;
		};

		vdec_gcon@16000000 {
			compatible = "mediatek,mt8163-vdec_gcon";
			reg = <0x0 0x16000000 0x0 0x10000>;
		};

		larb@16010000 {
			compatible = "mediatek,mt8163-smi-larb";
			reg = <0x0 0x16010000 0x0 0x10000>;
			interrupts = <0x0 0xd5 0x8>;
			mediatek,smi = <0x49>;
			mediatek,larbid = <0x1>;
			clocks = <0x61 0x0 0x61 0x1>;
			clock-names = "apb", "smi";
			power-domains = <0x35 0x1>;
		};

		vdec@16020000 {
			compatible = "mediatek,mt8163-vdec";
			reg = <0x0 0x16020000 0x0 0x10000>;
			interrupts = <0x0 0xd4 0x8>;
		};

		vencsys@17000000 {
			compatible = "mediatek,mt8163-vencsys", "syscon";
			reg = <0x0 0x17000000 0x0 0x1000>;
			#clock-cells = <0x1>;
			linux,phandle = <0x62>;
			phandle = <0x62>;
		};

		larb@17001000 {
			compatible = "mediatek,mt8163-smi-larb";
			reg = <0x0 0x17001000 0x0 0x1000>;
			interrupts = <0x0 0xcf 0x8>;
			mediatek,smi = <0x49>;
			mediatek,larbid = <0x3>;
			clocks = <0x62 0x1 0x62 0x0>;
			clock-names = "apb", "smi";
			power-domains = <0x35 0x2>;
		};

		venc@17002000 {
			compatible = "mediatek,mt8163-venc";
			reg = <0x0 0x17002000 0x0 0x1000>;
			interrupts = <0x0 0xce 0x8>;
		};

		jpgenc@17003000 {
			compatible = "mediatek,mt8163-jpgenc", "mediatek,jpgenc";
			reg = <0x0 0x17003000 0x0 0x1000>;
			interrupts = <0x0 0xd0 0x8>;
			clocks = <0x62 0x2>;
			clock-names = "venc-jpgenc";
		};

		btcvsd@18000000 {
			compatible = "mediatek,mt8163-audio_bt_cvsd", "mediatek,audio_bt_cvsd";
			offset = <0xf00 0x800 0xfd0 0xfd4 0xfd8>;
			reg = <0x0 0x10001000 0x0 0x1000 0x0 0x18000000 0x0 0x10000 0x0 0x18080000 0x0 0x8000>;
			interrupts = <0x0 0xec 0x8>;
		};

		consys@18070000 {
			compatible = "mediatek,mt8163-consys";
			reg = <0x0 0x18070000 0x0 0x200 0x0 0x10007000 0x0 0x100 0x0 0x10001000 0x0 0x1000>;
			power-domains = <0x35 0x4>;
			interrupts = <0x0 0xed 0x8 0x0 0xec 0x8>;
			pinctrl-names = "default", "gps_lna_state_init", "gps_lna_state_oh", "gps_lna_state_ol", "wifi_reset_init";
			pinctrl-0 = <0x63>;
			pinctrl-1 = <0x64>;
			pinctrl-2 = <0x65>;
			pinctrl-3 = <0x66>;
			pinctrl-4 = <0x67>;
			vcn18-supply = <0x68>;
			vcn28-supply = <0x69>;
			vcn33_bt-supply = <0x6a>;
			vcn33_wifi-supply = <0x6b>;
			status = "okay";
		};

		wifi@180f0000 {
			compatible = "mediatek,wifi";
			reg = <0x0 0x180f0000 0x0 0x5c>;
			interrupts = <0x0 0xee 0x8>;
			clocks = <0x9 0x29>;
			clock-names = "wifi-dma";
		};

		accdet@ {
			compatible = "mediatek,mt8163-accdet";
			interrupt-parent = <0xd>;
			interrupts = <0x4 0x8>;
			eint-debounce = <0x3e800>;
			accdet-gpio = <0xd 0x1a 0x0>;
			hp-sw1-pin = <0xd 0x57 0x1>;
			mic_dangling_vol = <0x672>;
			mic_voltage_delay = <0x50>;
			switch-mode-vol = <0x226>;
			switch-mode-delay = <0x1f4>;
			accdet-mic-vol = <0x7>;
			headset-mode-setting = <0x500 0x500 0x1 0x1f0 0x800 0x800 0x4000>;
			accdet-plugout-debounce = <0x3e8>;
			accdet-mic-mode = <0x1>;
			accdet-micbias1-ind-ctl = <0x1>;
			headset-three-key-threshold = <0x0 0x64 0xdc 0x1f4>;
			headset-four-key-threshold = <0x0 0x3a 0x79 0xc0 0x1c2>;
			pinctrl-names = "default", "state_eint_as_int", "typeswitchIC-off", "typeswitchIC-on";
			pinctrl-0 = <0x6c>;
			pinctrl-1 = <0x6d>;
			pinctrl-2 = <0x6e>;
			pinctrl-3 = <0x6f>;
			status = "okay";
		};

		touch@ {
			compatible = "mediatek,mt8163-touch";
			vtouch-supply = <0x2b>;
			tpd-resolution = <0x2d0 0x500>;
			use-tpd-button = <0x0>;
			tpd-key-num = <0x4>;
			tpd-key-local = <0x8b 0xac 0x9e 0x0>;
			tpd-key-dim-local = <0x3c 0x352 0x32 0x1e 0xb4 0x352 0x32 0x1e 0x12c 0x352 0x32 0x1e 0x1a4 0x352 0x32 0x1e>;
			tpd-max-touch-num = <0x5>;
			tpd-filter-enable = <0x1>;
			tpd-filter-pixel-density = <0x7c>;
			tpd-filter-custom-prameters = <0x0 0x0 0x0 0x0 0x0 0x0 0x0 0x0 0x0 0x0 0x0 0x0>;
			tpd-filter-custom-speed = <0x0 0x0 0x0>;
			pinctrl-names = "default", "state_eint_as_int", "state_eint_output0", "state_eint_output1", "state_rst_output0", "state_rst_output1";
			pinctrl-0 = <0x70>;
			pinctrl-1 = <0x2a>;
			pinctrl-2 = <0x29>;
			pinctrl-3 = <0x71>;
			pinctrl-4 = <0x72>;
			pinctrl-5 = <0x73>;
			status = "okay";
		};

		hwmsensor@0 {
			compatible = "mediatek,hwmsensor";
		};

		gsensor@0 {
			compatible = "mediatek,gsensor";
		};

		als_ps@0 {
			compatible = "mediatek,als_ps";
			pinctrl-names = "pin_default", "pin_cfg";
			pinctrl-0 = <0x74>;
			pinctrl-1 = <0x75>;
			status = "okay";
		};

		batchsensor@0 {
			compatible = "mediatek,batchsensor";
		};

		gyroscope@0 {
			compatible = "mediatek,gyroscope";
		};

		barometer@0 {
			compatible = "mediatek,barometer";
		};

		msensor@0 {
			compatible = "mediatek,msensor";
		};

		orientation@0 {
			compatible = "mediatek,orientation";
		};

		led@0 {
			compatible = "mediatek,red";
			led_mode = <0x0>;
			data;
			pwm_config = <0x0 0x0 0x0 0x0 0x0>;
		};

		led@1 {
			compatible = "mediatek,green";
			led_mode = <0x0>;
			data;
			pwm_config = <0x0 0x0 0x0 0x0 0x0>;
		};

		led@2 {
			compatible = "mediatek,blue";
			led_mode = <0x0>;
			data;
			pwm_config = <0x0 0x0 0x0 0x0 0x0>;
		};

		led@3 {
			compatible = "mediatek,jogball-backlight";
			led_mode = <0x0>;
			data;
			pwm_config = <0x0 0x0 0x0 0x0 0x0>;
		};

		led@4 {
			compatible = "mediatek,keyboard-backlight";
			led_mode = <0x0>;
			data;
			pwm_config = <0x0 0x0 0x0 0x0 0x0>;
		};

		led@5 {
			compatible = "mediatek,button-backlight";
			led_mode = <0x0>;
			data;
			pwm_config = <0x0 0x0 0x0 0x0 0x0>;
		};

		led@6 {
			compatible = "mediatek,lcd-backlight";
			led_mode = <0x4>;
			data;
			pwm_config = <0x0 0x0 0x0 0x0 0x0>;
			gpios = <0xd 0x2b 0x0>;
		};

		mtkfb@0 {
			compatible = "mediatek,MTKFB";
			clocks = <0xe 0x9 0xe 0xa 0xe 0xb 0xe 0xc 0xe 0xd 0xe 0xe 0xe 0x17 0xe 0xf 0xe 0x10 0xe 0x11 0xe 0x12 0xe 0x13 0xe 0x14 0xe 0x20 0xe 0x21 0xe 0x22 0xe 0x23 0xe 0x24 0xe 0x25 0xe 0x26 0xe 0x27 0xe 0x28 0xe 0x29 0xe 0x2e 0xe 0x2f 0xa 0x55 0x2e 0xa 0xa 0x14 0xa 0x15 0xa 0x16 0xa 0x59 0x2e 0x6 0xa 0x2d 0xa 0x2e 0xa 0x2f 0xa 0x30 0xa 0x44>;
			clock-names = "MMSYS_CLK_FAKE_ENG", "MMSYS_CLK_DISP_OVL0", "MMSYS_CLK_DISP_OVL1", "MMSYS_CLK_DISP_RDMA0", "MMSYS_CLK_DISP_RDMA1", "MMSYS_CLK_DISP_WDMA0", "MMSYS_CLK_DISP_WDMA1", "MMSYS_CLK_DISP_COLOR", "MMSYS_CLK_DISP_CCORR", "MMSYS_CLK_DISP_AAL", "MMSYS_CLK_DISP_GAMMA", "MMSYS_CLK_DISP_DITHER", "MMSYS_CLK_DISP_UFOE", "MMSYS_CLK_DISP_PWM", "MMSYS_CLK_DISP_PWM26M", "MMSYS_CLK_DSI_ENGINE", "MMSYS_CLK_DSI_DIGITAL", "MMSYS_CLK_DPI0_PIXEL", "MMSYS_CLK_DPI0_ENGINE", "MMSYS_CLK_LVDS_PIXEL", "MMSYS_CLK_LVDS_CTS", "MMSYS_CLK_DPI1_PIXEL", "MMSYS_CLK_DPI1_ENGINE", "MMSYS_CLK_DISP_DSC_ENGINE", "MMSYS_CLK_DISP_DSC_MEM", "MMSYS_CLK_MUX_DPI0_SEL", "MMSYS_APMIXED_LVDSPLL", "MMSYS_CLK_MUX_LVDSPLL_D2", "MMSYS_CLK_MUX_LVDSPLL_D4", "MMSYS_CLK_MUX_LVDSPLL_D8", "MMSYS_CLK_MUX_DPI1_SEL", "MMSYS_APMIXED_TVDPLL", "MMSYS_CLK_MUX_TVDPLL_D2", "MMSYS_CLK_MUX_TVDPLL_D4", "MMSYS_CLK_MUX_TVDPLL_D8", "MMSYS_CLK_MUX_TVDPLL_D16", "MMSYS_CLK_PWM_SEL";
		};

		ice_debug {
			compatible = "mediatek,mt8163-ice_debug", "mediatek,mt8173-ice_debug";
			clocks = <0x9 0x2f>;
			clock-names = "ice_dbg";
		};

		bat_meter {
			compatible = "mediatek,bat_meter";
			vbat_channel_number = <0x6>;
			isense_channel_number = <0x7>;
			vbattemp_channel_number = <0x5>;
			vcharger_channel_number = <0x4>;
			swchr_power_path = <0x1>;
			external_swchr_support = <0x1>;
			r_bat_sense = <0x4>;
			r_i_sense = <0x4>;
			r_charger_1 = <0x14a>;
			r_charger_2 = <0x27>;
			temperature_t0 = <0x6e>;
			temperature_t1 = <0x0>;
			temperature_t1_5 = <0xa>;
			temperature_t2 = <0x19>;
			temperature_t3 = <0x32>;
			temperature_t = <0xff>;
			fg_meter_resistance = <0x0>;
			q_max_pos_50 = <0x11f2>;
			q_max_pos_25 = <0x11ed>;
			q_max_pos_10 = <0x121b>;
			q_max_pos_0 = <0x10e0>;
			q_max_neg_10 = <0xfd2>;
			q_max_pos_50_h_current = <0x11d2>;
			q_max_pos_25_h_current = <0x11b5>;
			q_max_pos_10_h_current = <0x11dd>;
			q_max_pos_0_h_current = <0xec1>;
			q_max_neg_10_h_current = <0xa49>;
			oam_d5 = <0x0>;
			change_tracking_point = <0x1>;
			cust_tracking_point = <0xe>;
			cust_r_sense = <0xc8>;
			cust_hw_cc = <0x0>;
			aging_tuning_value = <0x64>;
			cust_r_fg_offset = <0x0>;
			ocv_board_compesate = <0x0>;
			r_fg_board_base = <0x3e8>;
			r_fg_board_slope = <0x3e8>;
			car_tune_value = <0x64>;
			current_detect_r_fg = <0xa>;
			minerroroffset = <0x3e8>;
			fg_vbat_average_size = <0x12>;
			r_fg_value = <0xa>;
			cust_poweron_delta_capacity_tolrance = <0x2d>;
			cust_poweron_low_capacity_tolrance = <0x5>;
			cust_poweron_max_vbat_tolrance = <0x46>;
			cust_poweron_delta_vbat_tolrance = <0x2d>;
			cust_poweron_delta_hw_sw_ocv_capacity_tolrance = <0xa>;
			fixed_tbat_25 = <0x0>;
			vbat_normal_wakeup = <0xe10>;
			vbat_low_power_wakeup = <0xdac>;
			normal_wakeup_period = <0x1518>;
			low_power_wakeup_period = <0x12c>;
			close_poweroff_wakeup_period = <0x1e>;
			rbat_pull_up_r = <0xf1cc>;
			rbat_pull_down_r = <0x186a0>;
			rbat_pull_up_volt = <0x708>;
			step_of_qmax = <0x3c>;
			std_loading_current = <0x1770>;
			vbat_internal_charging = <0x7>;
			isense_internal_charging = <0x6>;
			battery_id_channel_number = <0xc>;
			id_volt_max = <0x5c8>;
			id_volt_min = <0x2bc>;
			total_battery_number = <0x3>;
			bat_id_volt_thres = <0x4b0 0x514 0xffffffff>;
			batt_temperature_table_num = <0x11>;
			batt_temperature_table = <0xffffffec 0x7a0bc 0xfffffff1 0x5ab90 0xfffffff6 0x440ac 0xfffffffb 0x33770 0x0 0x27420 0x5 0x1e398 0xa 0x1771e 0xf 0x1255c 0x14 0xe736 0x19 0xb798 0x1e 0x92d6 0x23 0x763e 0x28 0x5fdc 0x2d 0x4e34 0x32 0x402e 0x37 0x3502 0x3c 0x2c06>;
			battery_vendor = "ATL";
			q_max_pos_50_500cycle = <0x11bf>;
			q_max_pos_25_500cycle = <0x11b8>;
			q_max_pos_10_500cycle = <0x11ff>;
			q_max_pos_0_500cycle = <0x11de>;
			q_max_neg_10_500cycle = <0x106c>;
			q_max_pos_50_h_current_500cycle = <0x119e>;
			q_max_pos_25_h_current_500cycle = <0x118f>;
			q_max_pos_10_h_current_500cycle = <0x1172>;
			q_max_pos_0_h_current_500cycle = <0x1072>;
			q_max_neg_10_h_current_500cycle = <0x592>;
			battery_profile_t0_num = <0x4c>;
			battery_profile_t0 = <0x0 0x1047 0x1 0x1012 0x3 0xfef 0x4 0xfd5 0x5 0xfba 0x7 0xf9d 0x8 0xf87 0x9 0xf7c 0xb 0xf76 0xc 0xf70 0xd 0xf6c 0xf 0xf67 0x10 0xf62 0x11 0xf5e 0x13 0xf58 0x14 0xf53 0x15 0xf4d 0x17 0xf46 0x18 0xf40 0x19 0xf39 0x1b 0xf31 0x1c 0xf29 0x1d 0xf20 0x1f 0xf18 0x20 0xf0f 0x21 0xf08 0x23 0xf01 0x24 0xefa 0x25 0xef4 0x27 0xeef 0x28 0xeeb 0x29 0xee7 0x2b 0xee3 0x2c 0xedf 0x2d 0xedc 0x2f 0xed9 0x30 0xed6 0x31 0xed4 0x33 0xed2 0x34 0xed0 0x35 0xecf 0x37 0xece 0x38 0xecc 0x39 0xecb 0x3b 0xeca 0x3c 0xec9 0x3d 0xec7 0x3f 0xec6 0x40 0xec4 0x41 0xec2 0x43 0xec0 0x44 0xebf 0x45 0xebc 0x47 0xeba 0x48 0xeb8 0x49 0xeb5 0x4b 0xeb2 0x4c 0xeaf 0x4d 0xeab 0x4f 0xea8 0x50 0xea4 0x51 0xe9f 0x53 0xe9b 0x54 0xe94 0x55 0xe90 0x57 0xe8a 0x58 0xe84 0x59 0xe7f 0x5b 0xe7a 0x5c 0xe76 0x5d 0xe73 0x5f 0xe6e 0x60 0xe68 0x61 0xe5d 0x63 0xe45 0x64 0xe19>;
			battery_profile_t1_num = <0x51>;
			battery_profile_t1 = <0x0 0x1044 0x1 0x100f 0x3 0xfed 0x4 0xfd1 0x5 0xfb5 0x6 0xfa3 0x8 0xf96 0x9 0xf8c 0xa 0xf84 0xb 0xf7e 0xd 0xf79 0xe 0xf75 0xf 0xf72 0x10 0xf6f 0x12 0xf6b 0x13 0xf67 0x14 0xf62 0x15 0xf5c 0x17 0xf56 0x18 0xf50 0x19 0xf4a 0x1a 0xf44 0x1c 0xf3e 0x1d 0xf37 0x1e 0xf31 0x1f 0xf2a 0x21 0xf22 0x22 0xf19 0x23 0xf10 0x24 0xf08 0x26 0xf00 0x27 0xef9 0x28 0xef3 0x29 0xeee 0x2b 0xee9 0x2c 0xee5 0x2d 0xee2 0x2e 0xede 0x30 0xedb 0x31 0xed9 0x32 0xed6 0x33 0xed4 0x35 0xed2 0x36 0xed0 0x37 0xece 0x38 0xecd 0x3a 0xecc 0x3b 0xecb 0x3c 0xeca 0x3d 0xeca 0x3f 0xec9 0x40 0xec8 0x41 0xec7 0x42 0xec6 0x44 0xec5 0x45 0xec4 0x46 0xec2 0x47 0xec0 0x49 0xebe 0x4a 0xebc 0x4b 0xeb9 0x4c 0xeb6 0x4e 0xeb3 0x4f 0xeb0 0x50 0xeab 0x51 0xea6 0x53 0xea1 0x54 0xe9b 0x55 0xe95 0x56 0xe8e 0x58 0xe87 0x59 0xe7f 0x5a 0xe7a 0x5b 0xe77 0x5d 0xe74 0x5e 0xe71 0x5f 0xe6e 0x60 0xe67 0x62 0xe57 0x63 0xe2e 0x64 0xdef>;
			battery_profile_t1_5_num = <0x57>;
			battery_profile_t1_5 = <0x0 0x1052 0x1 0x1017 0x2 0x1008 0x3 0xffc 0x5 0xff6 0x6 0xff2 0x7 0xfec 0x8 0xfe2 0x9 0xfd0 0xa 0xfb9 0xc 0xfa7 0xd 0xf9a 0xe 0xf89 0xf 0xf83 0x10 0xf7e 0x11 0xf7b 0x13 0xf78 0x14 0xf76 0x15 0xf71 0x16 0xf6c 0x17 0xf66 0x18 0xf60 0x1a 0xf59 0x1b 0xf53 0x1c 0xf4e 0x1d 0xf48 0x1e 0xf42 0x1f 0xf3c 0x21 0xf37 0x22 0xf31 0x23 0xf2b 0x24 0xf24 0x25 0xf1d 0x26 0xf14 0x28 0xf0a 0x29 0xf00 0x2a 0xef9 0x2b 0xef2 0x2c 0xeed 0x2d 0xee9 0x2f 0xee5 0x30 0xee1 0x31 0xede 0x32 0xedb 0x33 0xed8 0x34 0xed6 0x36 0xed3 0x37 0xed1 0x38 0xecf 0x39 0xecd 0x3a 0xecb 0x3b 0xec9 0x3d 0xec8 0x3e 0xec7 0x3f 0xec7 0x40 0xec6 0x41 0xec6 0x42 0xec5 0x44 0xec4 0x45 0xec3 0x46 0xec2 0x47 0xec1 0x48 0xebf 0x49 0xebd 0x4b 0xeba 0x4c 0xeb7 0x4d 0xeb3 0x4e 0xeb0 0x4f 0xeac 0x50 0xea8 0x52 0xea2 0x53 0xe9c 0x54 0xe95 0x55 0xe8f 0x56 0xe88 0x57 0xe7f 0x59 0xe78 0x5a 0xe75 0x5b 0xe73 0x5c 0xe72 0x5d 0xe70 0x5e 0xe6d 0x60 0xe64 0x61 0xe3e 0x62 0xe03 0x63 0xdb2 0x64 0xd33>;
			battery_profile_t2_num = <0x5b>;
			battery_profile_t2 = <0x0 0x103d 0x1 0x1030 0x2 0x1025 0x3 0x101a 0x4 0x1010 0x6 0x1005 0x7 0xffc 0x8 0xff2 0x9 0xfea 0xa 0xfe1 0xb 0xfd8 0xc 0xfcf 0xd 0xfc4 0xf 0xfbb 0x10 0xfb1 0x11 0xfa8 0x12 0xfa0 0x13 0xf98 0x14 0xf91 0x15 0xf8b 0x16 0xf85 0x17 0xf7e 0x19 0xf77 0x1a 0xf71 0x1b 0xf6a 0x1c 0xf64 0x1d 0xf5d 0x1e 0xf57 0x1f 0xf51 0x20 0xf4b 0x22 0xf46 0x23 0xf40 0x24 0xf3a 0x25 0xf35 0x26 0xf2f 0x27 0xf28 0x28 0xf21 0x29 0xf17 0x2a 0xf0c 0x2c 0xf02 0x2d 0xefb 0x2e 0xef5 0x2f 0xef1 0x30 0xeec 0x31 0xee8 0x32 0xee5 0x33 0xee2 0x35 0xedf 0x36 0xedc 0x37 0xed9 0x38 0xed6 0x39 0xed4 0x3a 0xed1 0x3b 0xecf 0x3c 0xecd 0x3d 0xecb 0x3f 0xec9 0x40 0xec8 0x41 0xec7 0x42 0xec5 0x43 0xec4 0x44 0xec3 0x45 0xec2 0x46 0xec0 0x48 0xebe 0x49 0xebb 0x4a 0xeb7 0x4b 0xeb4 0x4c 0xeb0 0x4d 0xeab 0x4e 0xea7 0x4f 0xea3 0x50 0xea0 0x52 0xe9c 0x53 0xe98 0x54 0xe91 0x55 0xe8a 0x56 0xe84 0x57 0xe7e 0x58 0xe76 0x59 0xe6d 0x5b 0xe6a 0x5c 0xe68 0x5d 0xe65 0x5e 0xe62 0x5f 0xe5e 0x60 0xe53 0x61 0xe30 0x62 0xdf8 0x63 0xdad 0x64 0xd40>;
			battery_profile_t3_num = <0x5b>;
			battery_profile_t3 = <0x0 0x1038 0x1 0x102c 0x2 0x1021 0x3 0x1017 0x4 0x100c 0x6 0x1002 0x7 0xff9 0x8 0xfef 0x9 0xfe5 0xa 0xfdc 0xb 0xfd3 0xc 0xfca 0xd 0xfc1 0xf 0xfb9 0x10 0xfb0 0x11 0xfa8 0x12 0xfa0 0x13 0xf98 0x14 0xf90 0x15 0xf89 0x16 0xf81 0x17 0xf7b 0x19 0xf73 0x1a 0xf6d 0x1b 0xf66 0x1c 0xf5f 0x1d 0xf59 0x1e 0xf53 0x1f 0xf4d 0x20 0xf47 0x21 0xf42 0x23 0xf3c 0x24 0xf36 0x25 0xf31 0x26 0xf2b 0x27 0xf26 0x28 0xf1f 0x29 0xf15 0x2a 0xf09 0x2c 0xefe 0x2d 0xef7 0x2e 0xef2 0x2f 0xeee 0x30 0xeea 0x31 0xee6 0x32 0xee3 0x33 0xedf 0x34 0xedc 0x36 0xed9 0x37 0xed6 0x38 0xed3 0x39 0xed1 0x3a 0xece 0x3b 0xecc 0x3c 0xeca 0x3d 0xec8 0x3f 0xec6 0x40 0xec4 0x41 0xec2 0x42 0xec1 0x43 0xebf 0x44 0xebe 0x45 0xebc 0x46 0xeba 0x47 0xeb3 0x49 0xeab 0x4a 0xea7 0x4b 0xea3 0x4c 0xe9f 0x4d 0xe9b 0x4e 0xe96 0x4f 0xe93 0x50 0xe8f 0x52 0xe8c 0x53 0xe87 0x54 0xe81 0x55 0xe7a 0x56 0xe74 0x57 0xe6e 0x58 0xe65 0x59 0xe5f 0x5a 0xe5d 0x5c 0xe5b 0x5d 0xe59 0x5e 0xe56 0x5f 0xe50 0x60 0xe3f 0x61 0xe15 0x62 0xddb 0x63 0xd8d 0x64 0xd1a>;
			r_profile_t0_num = <0x4c>;
			r_profile_t0 = <0x7d 0x1047 0x1cf 0x1012 0x1c1 0xfef 0x1cb 0xfd5 0x1fe 0xfba 0x229 0xf9d 0x240 0xf87 0x249 0xf7c 0x251 0xf76 0x257 0xf70 0x25d 0xf6c 0x264 0xf67 0x26c 0xf62 0x272 0xf5e 0x276 0xf58 0x277 0xf53 0x278 0xf4d 0x27b 0xf46 0x27a 0xf40 0x27d 0xf39 0x279 0xf31 0x278 0xf29 0x269 0xf20 0x25c 0xf18 0x24f 0xf0f 0x23d 0xf08 0x230 0xf01 0x225 0xefa 0x21b 0xef4 0x213 0xeef 0x20a 0xeeb 0x208 0xee7 0x210 0xee3 0x216 0xedf 0x21b 0xedc 0x221 0xed9 0x223 0xed6 0x225 0xed4 0x227 0xed2 0x22d 0xed0 0x234 0xecf 0x23d 0xece 0x244 0xecc 0x24b 0xecb 0x253 0xeca 0x25a 0xec9 0x263 0xec7 0x26c 0xec6 0x274 0xec4 0x278 0xec2 0x27c 0xec0 0x281 0xebf 0x28e 0xebc 0x29a 0xeba 0x2a4 0xeb8 0x2ad 0xeb5 0x2b9 0xeb2 0x2c4 0xeaf 0x2ce 0xeab 0x2d4 0xea8 0x2dd 0xea4 0x2e8 0xe9f 0x2f9 0xe9b 0x2b9 0xe94 0x2e2 0xe90 0x2ff 0xe8a 0x317 0xe84 0x330 0xe7f 0x34d 0xe7a 0x36c 0xe76 0x392 0xe73 0x3c0 0xe6e 0x3f9 0xe68 0x447 0xe5d 0x4a0 0xe45 0x50a 0xe19>;
			r_profile_t1_num = <0x51>;
			r_profile_t1 = <0x7d 0x1044 0x172 0x100f 0x174 0xfed 0x174 0xfd1 0x167 0xfb5 0x15f 0xfa3 0x15d 0xf96 0x15b 0xf8c 0x15c 0xf84 0x15d 0xf7e 0x161 0xf79 0x164 0xf75 0x168 0xf72 0x16b 0xf6f 0x16e 0xf6b 0x170 0xf67 0x172 0xf62 0x16e 0xf5c 0x176 0xf56 0x177 0xf50 0x177 0xf4a 0x178 0xf44 0x178 0xf3e 0x178 0xf37 0x177 0xf31 0x175 0xf2a 0x172 0xf22 0x16d 0xf19 0x168 0xf10 0x162 0xf08 0x15e 0xf00 0x15b 0xef9 0x159 0xef3 0x157 0xeee 0x156 0xee9 0x156 0xee5 0x156 0xee2 0x157 0xede 0x157 0xedb 0x158 0xed9 0x159 0xed6 0x15a 0xed4 0x15b 0xed2 0x15c 0xed0 0x15e 0xece 0x161 0xecd 0x164 0xecc 0x167 0xecb 0x16a 0xeca 0x16e 0xeca 0x172 0xec9 0x177 0xec8 0x17b 0xec7 0x181 0xec6 0x186 0xec5 0x18c 0xec4 0x18d 0xec2 0x198 0xec0 0x19d 0xebe 0x17d 0xebc 0x1ac 0xeb9 0x1b4 0xeb6 0x1bc 0xeb3 0x1c5 0xeb0 0x1ce 0xeab 0x1d8 0xea6 0x1e3 0xea1 0x1ee 0xe9b 0x1fb 0xe95 0x207 0xe8e 0x214 0xe87 0x222 0xe7f 0x233 0xe7a 0x24d 0xe77 0x26e 0xe74 0x299 0xe71 0x2cf 0xe6e 0x313 0xe67 0x36c 0xe57 0x3de 0xe2e 0x478 0xdef>;
			r_profile_t1_5_num = <0x57>;
			r_profile_t1_5 = <0x7d 0x1052 0xad 0x1017 0xb0 0x1008 0xb2 0xffc 0xb7 0xff6 0xbe 0xff2 0xc4 0xfec 0xc5 0xfe2 0xc0 0xfd0 0xba 0xfb9 0xb8 0xfa7 0xb8 0xf9a 0xad 0xf89 0xaf 0xf83 0xb3 0xf7e 0xb7 0xf7b 0xbc 0xf78 0xbf 0xf76 0xc0 0xf71 0xbe 0xf6c 0xbd 0xf66 0xbd 0xf60 0xbe 0xf59 0xbf 0xf53 0xc1 0xf4e 0xc2 0xf48 0xc4 0xf42 0xc4 0xf3c 0xc5 0xf37 0xc6 0xf31 0xc6 0xf2b 0xc4 0xf24 0xc1 0xf1d 0xbc 0xf14 0xb4 0xf0a 0xad 0xf00 0xaa 0xef9 0xa7 0xef2 0xa6 0xeed 0xa6 0xee9 0xa6 0xee5 0xa6 0xee1 0xa6 0xede 0xa7 0xedb 0xa7 0xed8 0xa8 0xed6 0xa9 0xed3 0xaa 0xed1 0xaa 0xecf 0xab 0xecd 0xac 0xecb 0xad 0xec9 0xae 0xec8 0xaf 0xec7 0xb1 0xec7 0xb2 0xec6 0xb3 0xec6 0xb4 0xec5 0xb5 0xec4 0xb7 0xec3 0xb8 0xec2 0xb9 0xec1 0xba 0xebf 0xba 0xebd 0xba 0xeba 0xba 0xeb7 0xba 0xeb3 0xbb 0xeb0 0xbd 0xeac 0xbf 0xea8 0xbf 0xea2 0xbf 0xe9c 0xc1 0xe95 0xc5 0xe8f 0xc8 0xe88 0xc8 0xe7f 0xcf 0xe78 0xda 0xe75 0xe1 0xe73 0xeb 0xe72 0xf6 0xe70 0x104 0xe6d 0x110 0xe64 0xfa 0xe3e 0xe1 0xe03 0xda 0xdb2 0xc1 0xd33>;
			r_profile_t2_num = <0x5b>;
			r_profile_t2 = <0x73 0x103d 0x73 0x1030 0x74 0x1025 0x75 0x101a 0x75 0x1010 0x76 0x1005 0x76 0xffc 0x77 0xff2 0x78 0xfea 0x79 0xfe1 0x79 0xfd8 0x79 0xfcf 0x79 0xfc4 0x7a 0xfbb 0x7a 0xfb1 0x7a 0xfa8 0x7b 0xfa0 0x7c 0xf98 0x7c 0xf91 0x7d 0xf8b 0x7f 0xf85 0x80 0xf7e 0x81 0xf77 0x81 0xf71 0x82 0xf6a 0x84 0xf64 0x85 0xf5d 0x86 0xf57 0x88 0xf51 0x89 0xf4b 0x8b 0xf46 0x8c 0xf40 0x8e 0xf3a 0x8f 0xf35 0x90 0xf2f 0x91 0xf28 0x90 0xf21 0x8a 0xf17 0x82 0xf0c 0x7c 0xf02 0x79 0xefb 0x77 0xef5 0x77 0xef1 0x76 0xeec 0x76 0xee8 0x75 0xee5 0x75 0xee2 0x75 0xedf 0x76 0xedc 0x76 0xed9 0x76 0xed6 0x77 0xed4 0x77 0xed1 0x78 0xecf 0x78 0xecd 0x79 0xecb 0x79 0xec9 0x7a 0xec8 0x7a 0xec7 0x7b 0xec5 0x7b 0xec4 0x7c 0xec3 0x7c 0xec2 0x7d 0xec0 0x7b 0xebe 0x7b 0xebb 0x7a 0xeb7 0x7a 0xeb4 0x7a 0xeb0 0x79 0xeab 0x7a 0xea7 0x7a 0xea3 0x7b 0xea0 0x7d 0xe9c 0x7d 0xe98 0x7e 0xe91 0x7f 0xe8a 0x80 0xe84 0x82 0xe7e 0x83 0xe76 0x83 0xe6d 0x85 0xe6a 0x89 0xe68 0x8d 0xe65 0x95 0xe62 0x9f 0xe5e 0xad 0xe53 0xb7 0xe30 0xd8 0xdf8 0x12a 0xdad 0x236 0xd40>;
			r_profile_t3_num = <0x5b>;
			r_profile_t3 = <0x5e 0x1038 0x5e 0x102c 0x5e 0x1021 0x5e 0x1017 0x5f 0x100c 0x5e 0x1002 0x5f 0xff9 0x5f 0xfef 0x60 0xfe5 0x5f 0xfdc 0x5f 0xfd3 0x60 0xfca 0x60 0xfc1 0x60 0xfb9 0x60 0xfb0 0x60 0xfa8 0x61 0xfa0 0x61 0xf98 0x62 0xf90 0x61 0xf89 0x62 0xf81 0x63 0xf7b 0x62 0xf73 0x64 0xf6d 0x64 0xf66 0x64 0xf5f 0x65 0xf59 0x66 0xf53 0x66 0xf4d 0x67 0xf47 0x68 0xf42 0x6a 0xf3c 0x6b 0xf36 0x6d 0xf31 0x6f 0xf2b 0x71 0xf26 0x72 0xf1f 0x6f 0xf15 0x68 0xf09 0x62 0xefe 0x60 0xef7 0x60 0xef2 0x60 0xeee 0x5f 0xeea 0x5f 0xee6 0x60 0xee3 0x60 0xedf 0x60 0xedc 0x60 0xed9 0x60 0xed6 0x60 0xed3 0x61 0xed1 0x61 0xece 0x61 0xecc 0x62 0xeca 0x62 0xec8 0x62 0xec6 0x63 0xec4 0x63 0xec2 0x64 0xec1 0x65 0xebf 0x65 0xebe 0x66 0xebc 0x65 0xeba 0x60 0xeb3 0x5f 0xeab 0x60 0xea7 0x60 0xea3 0x60 0xe9f 0x61 0xe9b 0x61 0xe96 0x61 0xe93 0x62 0xe8f 0x62 0xe8c 0x62 0xe87 0x62 0xe81 0x62 0xe7a 0x62 0xe74 0x64 0xe6e 0x62 0xe65 0x63 0xe5f 0x63 0xe5d 0x65 0xe5b 0x67 0xe59 0x6a 0xe56 0x6e 0xe50 0x6e 0xe3f 0x70 0xe15 0x75 0xddb 0x7e 0xd8d 0x92 0xd1a>;
			battery_profile_t1_500cycle = <0x0 0x1067 0x1 0x1059 0x2 0x104c 0x4 0x1041 0x5 0x1036 0x6 0x102b 0x7 0x1022 0x8 0x1018 0x9 0x1010 0xb 0x100c 0xc 0x1009 0xd 0x1004 0xe 0xff9 0xf 0xfe5 0x10 0xfca 0x12 0xfb4 0x13 0xfa6 0x14 0xf9b 0x15 0xf93 0x16 0xf8c 0x18 0xf86 0x19 0xf81 0x1a 0xf7d 0x1b 0xf7b 0x1c 0xf78 0x1d 0xf74 0x1f 0xf6f 0x20 0xf68 0x21 0xf62 0x22 0xf5b 0x23 0xf54 0x25 0xf4b 0x26 0xf42 0x27 0xf37 0x28 0xf2c 0x29 0xf22 0x2a 0xf19 0x2c 0xf11 0x2d 0xf0a 0x2e 0xf04 0x2f 0xeff 0x30 0xefb 0x31 0xef7 0x33 0xef3 0x34 0xeef 0x35 0xeeb 0x36 0xee8 0x37 0xee5 0x39 0xee2 0x3a 0xedf 0x3b 0xedd 0x3c 0xeda 0x3e 0xed7 0x41 0xed5 0x43 0xed0 0x46 0xeca 0x48 0xec3 0x4a 0xeb6 0x4b 0xec7 0x4d 0xec3 0x4e 0xebe 0x4f 0xeba 0x50 0xeb6 0x51 0xeb2 0x52 0xead 0x54 0xea7 0x55 0xea0 0x56 0xe98 0x57 0xe90 0x58 0xe88 0x5a 0xe83 0x5b 0xe7f 0x5c 0xe7c 0x5d 0xe78 0x5e 0xe73 0x5f 0xe68 0x61 0xe4a 0x62 0xe11 0x63 0xdbd 0x64 0xd35>;
			battery_profile_t1_5_500cycle = <0x0 0x1066 0x1 0x105c 0x2 0x1051 0x4 0x1046 0x5 0x103c 0x6 0x1031 0x7 0x1027 0x8 0x101d 0x9 0x1014 0xb 0x100b 0xc 0x1007 0xd 0x1005 0xe 0x1000 0xf 0xff5 0x10 0xfe0 0x12 0xfc8 0x13 0xfb4 0x14 0xfa7 0x15 0xf9c 0x16 0xf94 0x17 0xf8e 0x19 0xf88 0x1a 0xf84 0x1b 0xf82 0x1c 0xf7f 0x1d 0xf7b 0x1e 0xf76 0x20 0xf70 0x21 0xf6a 0x22 0xf64 0x23 0xf5d 0x24 0xf56 0x25 0xf4f 0x27 0xf46 0x28 0xf3b 0x29 0xf30 0x2a 0xf24 0x2b 0xf1b 0x2c 0xf13 0x2e 0xf0c 0x2f 0xf06 0x30 0xf01 0x31 0xefc 0x32 0xef8 0x33 0xef4 0x35 0xef0 0x36 0xeed 0x37 0xeea 0x39 0xee4 0x3a 0xee1 0x3c 0xede 0x3d 0xedb 0x3f 0xed6 0x42 0xed3 0x44 0xed0 0x46 0xecd 0x49 0xec9 0x4a 0xec6 0x4b 0xec3 0x4c 0xebe 0x4d 0xeba 0x4e 0xeb6 0x50 0xeb2 0x51 0xeae 0x52 0xeaa 0x53 0xea4 0x54 0xe9e 0x55 0xe97 0x57 0xe8f 0x58 0xe87 0x59 0xe80 0x5a 0xe7b 0x5b 0xe78 0x5e 0xe73 0x5f 0xe6c 0x60 0xe5b 0x61 0xe32 0x62 0xdf2 0x63 0xd94 0x64 0xcf4>;
			battery_profile_t2_500cycle = <0x0 0x1051 0x1 0x1044 0x2 0x1038 0x4 0x102d 0x5 0x1023 0x6 0x1018 0x7 0x100e 0x8 0x1004 0xa 0xffa 0xb 0xff1 0xc 0xfeb 0xd 0xfe8 0xe 0xfe5 0xf 0xfda 0x11 0xfc8 0x12 0xfb2 0x13 0xfa1 0x14 0xf94 0x15 0xf8b 0x17 0xf84 0x18 0xf7e 0x19 0xf7a 0x1a 0xf78 0x1b 0xf75 0x1d 0xf6f 0x1e 0xf69 0x1f 0xf62 0x20 0xf5c 0x21 0xf55 0x22 0xf4f 0x24 0xf49 0x25 0xf42 0x26 0xf3a 0x27 0xf32 0x28 0xf27 0x2a 0xf1a 0x2b 0xf0f 0x2c 0xf06 0x2d 0xefe 0x2e 0xef8 0x30 0xef3 0x31 0xeee 0x32 0xeea 0x33 0xee5 0x34 0xee1 0x35 0xedd 0x37 0xeda 0x38 0xed7 0x39 0xed3 0x3b 0xece 0x3e 0xec8 0x40 0xec3 0x43 0xebe 0x45 0xeba 0x46 0xeb6 0x47 0xeb4 0x48 0xeb0 0x4a 0xeab 0x4b 0xea7 0x4c 0xea2 0x4d 0xe9d 0x4e 0xe99 0x50 0xe96 0x51 0xe93 0x52 0xe8f 0x53 0xe89 0x54 0xe82 0x56 0xe7c 0x57 0xe74 0x58 0xe6b 0x59 0xe64 0x5a 0xe61 0x5b 0xe60 0x5d 0xe5e 0x5e 0xe5c 0x5f 0xe57 0x60 0xe42 0x61 0xe10 0x63 0xdca 0x64 0xd65>;
			battery_profile_t3_500cycle = <0x0 0x104f 0x1 0x1043 0x2 0x1038 0x4 0x102e 0x5 0x1023 0x6 0x1019 0x7 0x100f 0x8 0x1005 0x9 0xffb 0xb 0xff1 0xc 0xfe8 0xd 0xfe0 0xe 0xfdb 0xf 0xfd3 0x11 0xfc5 0x12 0xfb7 0x13 0xfac 0x14 0xfa5 0x15 0xfa0 0x17 0xf99 0x18 0xf92 0x19 0xf8a 0x1a 0xf83 0x1b 0xf7c 0x1c 0xf74 0x1e 0xf6e 0x1f 0xf67 0x20 0xf60 0x21 0xf5a 0x22 0xf54 0x24 0xf4d 0x25 0xf46 0x26 0xf3f 0x27 0xf36 0x28 0xf2c 0x2a 0xf20 0x2b 0xf15 0x2c 0xf0c 0x2d 0xf05 0x2e 0xf00 0x2f 0xefa 0x31 0xef6 0x32 0xef1 0x33 0xeed 0x34 0xee9 0x35 0xee5 0x37 0xee2 0x38 0xede 0x39 0xedb 0x3a 0xed8 0x3b 0xed4 0x3d 0xed1 0x3f 0xecc 0x41 0xec7 0x44 0xec2 0x46 0xeba 0x48 0xeab 0x4a 0xea4 0x4b 0xe9f 0x4c 0xe9b 0x4d 0xe95 0x4e 0xe91 0x4f 0xe8e 0x51 0xe8a 0x52 0xe87 0x53 0xe82 0x54 0xe7b 0x55 0xe75 0x57 0xe6e 0x58 0xe65 0x59 0xe5e 0x5a 0xe5c 0x5b 0xe5a 0x5d 0xe59 0x5e 0xe57 0x5f 0xe52 0x60 0xe3e 0x61 0xe0e 0x62 0xdcd 0x64 0xd72>;
			r_profile_t1_500cycle = <0x124 0x1067 0x123 0x1059 0x125 0x104c 0x126 0x1041 0x128 0x1036 0x128 0x102b 0x12a 0x1022 0x128 0x1018 0x129 0x1010 0x130 0x100c 0x13e 0x1009 0x149 0x1004 0x14e 0xff9 0x14a 0xfe5 0x13d 0xfca 0x138 0xfb4 0x139 0xfa6 0x139 0xf9b 0x13d 0xf93 0x13e 0xf8c 0x141 0xf86 0x143 0xf81 0x147 0xf7d 0x14d 0xf7b 0x152 0xf78 0x155 0xf74 0x157 0xf6f 0x158 0xf68 0x15a 0xf62 0x15c 0xf5b 0x15b 0xf54 0x15b 0xf4b 0x157 0xf42 0x151 0xf37 0x14d 0xf2c 0x148 0xf22 0x143 0xf19 0x143 0xf11 0x143 0xf0a 0x140 0xf04 0x143 0xeff 0x145 0xefb 0x148 0xef7 0x148 0xef3 0x14c 0xeef 0x14d 0xeeb 0x150 0xee8 0x154 0xee5 0x158 0xee2 0x15a 0xedf 0x15d 0xedd 0x15f 0xeda 0x167 0xed7 0x16c 0xed5 0x79 0xed0 0x77 0xeca 0x77 0xec3 0x72 0xeb6 0x122 0xec7 0x182 0xec3 0x187 0xebe 0x18e 0xeba 0x194 0xeb6 0x19a 0xeb2 0x1a0 0xead 0x1a8 0xea7 0x1af 0xea0 0x1b7 0xe98 0x1bf 0xe90 0x1c8 0xe88 0x1d2 0xe83 0x1e5 0xe7f 0x1fd 0xe7c 0x21b 0xe78 0x243 0xe73 0x26f 0xe68 0x29b 0xe4a 0x2d3 0xe11 0x32a 0xdbd 0x3b9 0xd35>;
			r_profile_t1_5_500cycle = <0xc9 0x1066 0xc9 0x105c 0xca 0x1051 0xcb 0x1046 0xcb 0x103c 0xcc 0x1031 0xcc 0x1027 0xcd 0x101d 0xcb 0x1014 0xc9 0x100b 0xcc 0x1007 0xd6 0x1005 0xdf 0x1000 0xe1 0xff5 0xde 0xfe0 0xd7 0xfc8 0xd3 0xfb4 0xd3 0xfa7 0xd2 0xf9c 0xd4 0xf94 0xd4 0xf8e 0xd6 0xf88 0xd8 0xf84 0xdc 0xf82 0xe1 0xf7f 0xe4 0xf7b 0xe6 0xf76 0xe8 0xf70 0xea 0xf6a 0xec 0xf64 0xee 0xf5d 0xf1 0xf56 0xf1 0xf4f 0xf0 0xf46 0xec 0xf3b 0xe5 0xf30 0xdf 0xf24 0xda 0xf1b 0xd8 0xf13 0xd5 0xf0c 0xd5 0xf06 0xd4 0xf01 0xd5 0xefc 0xd5 0xef8 0xd6 0xef4 0xd7 0xef0 0xd8 0xeed 0xd9 0xeea 0xdc 0xee4 0xdd 0xee1 0xde 0xede 0xe0 0xedb 0xe3 0xed6 0xe5 0xed3 0xe9 0xed0 0xeb 0xecd 0xed 0xec9 0xee 0xec6 0xee 0xec3 0xef 0xebe 0xf0 0xeba 0xf1 0xeb6 0xf5 0xeb2 0xf8 0xeae 0xfd 0xeaa 0xfe 0xea4 0x103 0xe9e 0x107 0xe97 0x10c 0xe8f 0x10f 0xe87 0x114 0xe80 0x119 0xe7b 0x124 0xe78 0x145 0xe73 0x15e 0xe6c 0x17c 0xe5b 0x194 0xe32 0x1b4 0xdf2 0x1ef 0xd94 0x284 0xcf4>;
			r_profile_t2_500cycle = <0x75 0x1051 0x75 0x1044 0x77 0x1038 0x78 0x102d 0x79 0x1023 0x78 0x1018 0x78 0x100e 0x78 0x1004 0x79 0xffa 0x78 0xff1 0x77 0xfeb 0x7a 0xfe8 0x7e 0xfe5 0x7e 0xfda 0x7c 0xfc8 0x7b 0xfb2 0x7b 0xfa1 0x7a 0xf94 0x7a 0xf8b 0x7b 0xf84 0x79 0xf7e 0x7b 0xf7a 0x7e 0xf78 0x80 0xf75 0x7f 0xf6f 0x81 0xf69 0x82 0xf62 0x84 0xf5c 0x85 0xf55 0x87 0xf4f 0x8b 0xf49 0x8e 0xf42 0x8f 0xf3a 0x90 0xf32 0x8e 0xf27 0x88 0xf1a 0x84 0xf0f 0x80 0xf06 0x7e 0xefe 0x7e 0xef8 0x7d 0xef3 0x7c 0xeee 0x79 0xeea 0x79 0xee5 0x79 0xee1 0x79 0xedd 0x7a 0xeda 0x80 0xed7 0x80 0xed3 0x82 0xece 0x82 0xec8 0x83 0xec3 0x85 0xebe 0x85 0xeba 0x84 0xeb6 0x84 0xeb4 0x83 0xeb0 0x81 0xeab 0x81 0xea7 0x80 0xea2 0x80 0xe9d 0x80 0xe99 0x81 0xe96 0x82 0xe93 0x84 0xe8f 0x84 0xe89 0x83 0xe82 0x83 0xe7c 0x83 0xe74 0x82 0xe6b 0x81 0xe64 0x81 0xe61 0x83 0xe60 0x85 0xe5e 0x89 0xe5c 0x90 0xe57 0x93 0xe42 0x90 0xe10 0x92 0xdca 0x9b 0xd65>;
			r_profile_t3_500cycle = <0x65 0x104f 0x65 0x1043 0x65 0x1038 0x65 0x102e 0x65 0x1023 0x65 0x1019 0x65 0x100f 0x66 0x1005 0x65 0xffb 0x65 0xff1 0x66 0xfe8 0x67 0xfe0 0x68 0xfdb 0x68 0xfd3 0x67 0xfc5 0x67 0xfb7 0x67 0xfac 0x68 0xfa5 0x68 0xfa0 0x68 0xf99 0x68 0xf92 0x68 0xf8a 0x69 0xf83 0x6a 0xf7c 0x6b 0xf74 0x6c 0xf6e 0x6d 0xf67 0x6d 0xf60 0x6e 0xf5a 0x70 0xf54 0x70 0xf4d 0x73 0xf46 0x74 0xf3f 0x75 0xf36 0x74 0xf2c 0x70 0xf20 0x6d 0xf15 0x6b 0xf0c 0x69 0xf05 0x69 0xf00 0x68 0xefa 0x67 0xef6 0x68 0xef1 0x67 0xeed 0x67 0xee9 0x67 0xee5 0x68 0xee2 0x69 0xede 0x69 0xedb 0x69 0xed8 0x69 0xed4 0x6a 0xed1 0x6b 0xecc 0x6c 0xec7 0x6e 0xec2 0x6d 0xeba 0x67 0xeab 0x67 0xea4 0x68 0xe9f 0x68 0xe9b 0x68 0xe95 0x67 0xe91 0x69 0xe8e 0x68 0xe8a 0x69 0xe87 0x69 0xe82 0x69 0xe7b 0x69 0xe75 0x68 0xe6e 0x69 0xe65 0x67 0xe5e 0x68 0xe5c 0x68 0xe5a 0x6b 0xe59 0x6c 0xe57 0x70 0xe52 0x6d 0xe3e 0x6d 0xe0e 0x71 0xdcd 0x79 0xd72>;
			battery_vendor_1 = "SONY";
			q_max_pos_50_1 = <0x11bc>;
			q_max_pos_25_1 = <0x11ec>;
			q_max_pos_10_1 = <0x10d5>;
			q_max_pos_0_1 = <0x10d5>;
			q_max_neg_10_1 = <0x103b>;
			q_max_pos_50_h_current_1 = <0x1197>;
			q_max_pos_25_h_current_1 = <0x11c5>;
			q_max_pos_10_h_current_1 = <0x1086>;
			q_max_pos_0_h_current_1 = <0x1058>;
			q_max_neg_10_h_current_1 = <0xf76>;
			q_max_pos_50_500cycle_1 = <0x1180>;
			q_max_pos_25_500cycle_1 = <0x119e>;
			q_max_pos_10_500cycle_1 = <0x1191>;
			q_max_pos_0_500cycle_1 = <0x11c6>;
			q_max_neg_10_500cycle_1 = <0x1185>;
			q_max_pos_50_h_current_500cycle_1 = <0x1158>;
			q_max_pos_25_h_current_500cycle_1 = <0x1176>;
			q_max_pos_10_h_current_500cycle_1 = <0x115f>;
			q_max_pos_0_h_current_500cycle_1 = <0x117c>;
			q_max_neg_10_h_current_500cycle_1 = <0x10e4>;
			battery_profile_t0_num_1 = <0x50>;
			battery_profile_t0_1 = <0x0 0x1043 0x1 0x1043 0x2 0x102f 0x4 0x1018 0x5 0xff8 0x6 0xfe2 0x7 0xfd4 0x9 0xfc9 0xa 0xfbe 0xb 0xfb5 0xc 0xfac 0xe 0xfa4 0xf 0xf9c 0x10 0xf94 0x11 0xf8c 0x13 0xf85 0x14 0xf7d 0x15 0xf76 0x16 0xf6f 0x17 0xf68 0x19 0xf61 0x1a 0xf5a 0x1b 0xf54 0x1c 0xf4d 0x1e 0xf46 0x1f 0xf40 0x20 0xf39 0x21 0xf32 0x23 0xf2b 0x24 0xf24 0x25 0xf1d 0x26 0xf16 0x28 0xf0f 0x29 0xf09 0x2a 0xf03 0x2b 0xefd 0x2c 0xef8 0x2e 0xef3 0x2f 0xeee 0x30 0xeea 0x31 0xee6 0x33 0xee3 0x34 0xedf 0x35 0xedc 0x36 0xed9 0x38 0xed6 0x39 0xed4 0x3a 0xed2 0x3b 0xecf 0x3c 0xecd 0x3e 0xecc 0x3f 0xeca 0x41 0xec6 0x43 0xec5 0x45 0xec1 0x46 0xec0 0x48 0xebe 0x49 0xebb 0x4a 0xeb9 0x4b 0xeb6 0x4d 0xeb3 0x4e 0xeaf 0x4f 0xeab 0x50 0xea6 0x51 0xea0 0x53 0xe9a 0x54 0xe93 0x55 0xe8c 0x56 0xe83 0x58 0xe7a 0x59 0xe70 0x5a 0xe66 0x5b 0xe5e 0x5d 0xe57 0x5e 0xe4e 0x5f 0xe43 0x60 0xe30 0x62 0xe0a 0x63 0xdca 0x64 0xd6d>;
			battery_profile_t1_num_1 = <0x50>;
			battery_profile_t1_1 = <0x0 0x1053 0x1 0x1024 0x2 0x100a 0x4 0xffa 0x5 0xfed 0x6 0xfe2 0x7 0xfd8 0x8 0xfcd 0xa 0xfc4 0xb 0xfbb 0xc 0xfb3 0xd 0xfaa 0xe 0xfa2 0xf 0xf99 0x11 0xf91 0x12 0xf8a 0x13 0xf83 0x14 0xf7c 0x15 0xf75 0x17 0xf6f 0x18 0xf67 0x19 0xf61 0x1a 0xf5b 0x1b 0xf54 0x1d 0xf4e 0x1e 0xf48 0x1f 0xf41 0x20 0xf3a 0x21 0xf34 0x23 0xf2d 0x24 0xf26 0x25 0xf1f 0x26 0xf18 0x27 0xf11 0x28 0xf0a 0x2a 0xf03 0x2b 0xefd 0x2c 0xef7 0x2d 0xef1 0x2e 0xeed 0x30 0xee8 0x31 0xee4 0x32 0xee0 0x33 0xedc 0x34 0xed9 0x36 0xed6 0x37 0xed3 0x38 0xed1 0x39 0xece 0x3a 0xecc 0x3c 0xeca 0x3e 0xec7 0x40 0xec4 0x41 0xec2 0x44 0xec0 0x46 0xebd 0x47 0xebb 0x4a 0xeb6 0x4b 0xeb3 0x4c 0xeb0 0x4d 0xeac 0x4f 0xea8 0x50 0xea3 0x51 0xe9e 0x52 0xe98 0x53 0xe92 0x55 0xe8b 0x56 0xe83 0x57 0xe7c 0x58 0xe72 0x59 0xe67 0x5a 0xe5d 0x5c 0xe57 0x5d 0xe50 0x5e 0xe49 0x5f 0xe40 0x60 0xe2c 0x62 0xdff 0x63 0xdbf 0x64 0xd67>;
			battery_profile_t1_5_num_1 = <0x50>;
			battery_profile_t1_5_1 = <0x0 0x1053 0x1 0x1020 0x2 0x1011 0x4 0x1004 0x5 0xff9 0x6 0xfee 0x7 0xfe4 0x8 0xfda 0xa 0xfd1 0xb 0xfc8 0xc 0xfbf 0xd 0xfb6 0xe 0xfae 0xf 0xfa6 0x11 0xf9e 0x12 0xf96 0x13 0xf8f 0x14 0xf87 0x15 0xf80 0x17 0xf79 0x18 0xf72 0x19 0xf6c 0x1a 0xf65 0x1b 0xf5f 0x1d 0xf59 0x1e 0xf52 0x1f 0xf4c 0x20 0xf46 0x21 0xf40 0x23 0xf39 0x24 0xf33 0x25 0xf2c 0x26 0xf25 0x27 0xf1d 0x28 0xf16 0x2a 0xf0f 0x2b 0xf08 0x2c 0xf01 0x2d 0xefb 0x2e 0xef5 0x30 0xef0 0x31 0xeeb 0x32 0xee6 0x33 0xee3 0x34 0xedf 0x36 0xedc 0x37 0xed8 0x38 0xed6 0x39 0xed3 0x3a 0xed1 0x3c 0xece 0x3d 0xecc 0x3f 0xec8 0x41 0xec5 0x43 0xec4 0x45 0xec1 0x47 0xebe 0x4a 0xeba 0x4b 0xeb7 0x4c 0xeb3 0x4d 0xeaf 0x4f 0xeaa 0x50 0xea6 0x51 0xea2 0x52 0xe9e 0x53 0xe98 0x55 0xe92 0x56 0xe8b 0x57 0xe85 0x58 0xe7e 0x59 0xe75 0x5a 0xe6a 0x5c 0xe62 0x5d 0xe5d 0x5e 0xe57 0x5f 0xe50 0x60 0xe48 0x62 0xe33 0x63 0xe07 0x64 0xdcc>;
			battery_profile_t2_num_1 = <0x5a>;
			battery_profile_t2_1 = <0x0 0x103c 0x1 0x102c 0x2 0x101f 0x3 0x1013 0x4 0x1008 0x6 0xffd 0x7 0xff3 0x8 0xfe9 0x9 0xfe0 0xa 0xfd7 0xb 0xfce 0xc 0xfc5 0xd 0xfbd 0xf 0xfb4 0x10 0xfac 0x11 0xfa4 0x12 0xf9c 0x13 0xf95 0x14 0xf8e 0x15 0xf87 0x16 0xf7f 0x17 0xf79 0x19 0xf72 0x1a 0xf6c 0x1b 0xf65 0x1c 0xf5f 0x1d 0xf59 0x1e 0xf53 0x1f 0xf4d 0x20 0xf48 0x22 0xf42 0x23 0xf3c 0x24 0xf36 0x25 0xf30 0x26 0xf2a 0x27 0xf23 0x28 0xf1c 0x29 0xf14 0x2a 0xf0c 0x2c 0xf05 0x2d 0xefe 0x2e 0xef8 0x2f 0xef2 0x30 0xeed 0x31 0xee9 0x32 0xee4 0x33 0xee1 0x35 0xedd 0x36 0xeda 0x37 0xed7 0x38 0xed5 0x39 0xed2 0x3a 0xecf 0x3b 0xecd 0x3c 0xecb 0x3d 0xec9 0x3f 0xec8 0x40 0xec6 0x41 0xec4 0x42 0xec3 0x43 0xec2 0x44 0xec1 0x45 0xebf 0x46 0xebd 0x48 0xeba 0x49 0xeb6 0x4a 0xeb1 0x4b 0xead 0x4c 0xea8 0x4d 0xea4 0x4e 0xe9f 0x4f 0xe9c 0x51 0xe98 0x52 0xe93 0x53 0xe8e 0x54 0xe88 0x55 0xe81 0x56 0xe7b 0x57 0xe74 0x58 0xe6b 0x59 0xe61 0x5b 0xe5b 0x5c 0xe56 0x5d 0xe51 0x5e 0xe4b 0x5f 0xe42 0x60 0xe2b 0x61 0xdff 0x62 0xdc5 0x64 0xd79>;
			battery_profile_t3_num_1 = <0x5a>;
			battery_profile_t3_1 = <0x0 0x1038 0x1 0x1029 0x2 0x101c 0x3 0x1010 0x5 0x1005 0x6 0xffa 0x7 0xff0 0x8 0xfe6 0x9 0xfdd 0xa 0xfd4 0xb 0xfcb 0xc 0xfc2 0xe 0xfba 0xf 0xfb1 0x10 0xfa9 0x11 0xfa1 0x12 0xf99 0x13 0xf92 0x14 0xf8a 0x15 0xf83 0x17 0xf7c 0x18 0xf75 0x19 0xf6e 0x1a 0xf68 0x1b 0xf62 0x1c 0xf5b 0x1d 0xf55 0x1f 0xf4f 0x20 0xf4a 0x21 0xf44 0x22 0xf3e 0x23 0xf39 0x24 0xf34 0x25 0xf2e 0x26 0xf28 0x28 0xf22 0x29 0xf1b 0x2a 0xf12 0x2b 0xf09 0x2c 0xf00 0x2d 0xef9 0x2e 0xef3 0x2f 0xeed 0x31 0xee9 0x32 0xee5 0x33 0xee1 0x34 0xedd 0x35 0xeda 0x36 0xed6 0x37 0xed3 0x38 0xed1 0x3a 0xece 0x3b 0xecc 0x3c 0xec9 0x3d 0xec7 0x3e 0xec5 0x3f 0xec3 0x40 0xec1 0x42 0xebf 0x43 0xebe 0x44 0xebc 0x45 0xebb 0x46 0xeb8 0x47 0xeb2 0x48 0xeaa 0x49 0xea3 0x4b 0xe9e 0x4c 0xe9a 0x4d 0xe95 0x4e 0xe90 0x4f 0xe8c 0x50 0xe88 0x51 0xe85 0x52 0xe80 0x54 0xe7a 0x55 0xe73 0x56 0xe6d 0x57 0xe66 0x58 0xe5e 0x59 0xe55 0x5a 0xe50 0x5c 0xe4c 0x5d 0xe48 0x5e 0xe43 0x5f 0xe3a 0x60 0xe23 0x61 0xdf9 0x62 0xdc2 0x63 0xd7b 0x64 0xd17>;
			r_profile_t0_num_1 = <0x50>;
			r_profile_t0_1 = <0xf7 0x1043 0xf7 0x1043 0x103 0x102f 0x11d 0x1018 0x122 0xff8 0x11e 0xfe2 0x11f 0xfd4 0x123 0xfc9 0x127 0xfbe 0x12b 0xfb5 0x12e 0xfac 0x130 0xfa4 0x132 0xf9c 0x134 0xf94 0x135 0xf8c 0x138 0xf85 0x138 0xf7d 0x13a 0xf76 0x137 0xf6f 0x133 0xf68 0x130 0xf61 0x12b 0xf5a 0x127 0xf54 0x124 0xf4d 0x120 0xf46 0x11d 0xf40 0x11a 0xf39 0x118 0xf32 0x119 0xf2b 0x11b 0xf24 0x11c 0xf1d 0x11d 0xf16 0x11d 0xf0f 0x11c 0xf09 0x11c 0xf03 0x11d 0xefd 0x11f 0xef8 0x121 0xef3 0x123 0xeee 0x125 0xeea 0x127 0xee6 0x128 0xee3 0x12a 0xedf 0x12c 0xedc 0x12d 0xed9 0x12c 0xed6 0x12b 0xed4 0x12a 0xed2 0x12b 0xecf 0x12d 0xecd 0x12d 0xecc 0x12e 0xeca 0x12f 0xec6 0x12f 0xec5 0x12c 0xec1 0x12b 0xec0 0x12c 0xebe 0x114 0xebb 0x11b 0xeb9 0x11f 0xeb6 0x121 0xeb3 0x122 0xeaf 0x123 0xeab 0x123 0xea6 0x122 0xea0 0x122 0xe9a 0x123 0xe93 0x126 0xe8c 0x12a 0xe83 0x12f 0xe7a 0x135 0xe70 0x13f 0xe66 0x14e 0xe5e 0x161 0xe57 0x178 0xe4e 0x199 0xe43 0x1c6 0xe30 0x203 0xe0a 0x25f 0xdca 0x319 0xd6d>;
			r_profile_t1_num_1 = <0x50>;
			r_profile_t1_1 = <0xc7 0x1053 0xc7 0x1024 0xbd 0x100a 0xbb 0xffa 0xbb 0xfed 0xbc 0xfe2 0xbd 0xfd8 0xbd 0xfcd 0xbf 0xfc4 0xc0 0xfbb 0xc1 0xfb3 0xc2 0xfaa 0xc3 0xfa2 0xc3 0xf99 0xc4 0xf91 0xc5 0xf8a 0xc4 0xf83 0xc7 0xf7c 0xc8 0xf75 0xc9 0xf6f 0xc9 0xf67 0xca 0xf61 0xca 0xf5b 0xca 0xf54 0xcb 0xf4e 0xcb 0xf48 0xca 0xf41 0xc9 0xf3a 0xc9 0xf34 0xc8 0xf2d 0xc7 0xf26 0xc5 0xf1f 0xc4 0xf18 0xc2 0xf11 0xbf 0xf0a 0xbd 0xf03 0xbc 0xefd 0xbb 0xef7 0xba 0xef1 0xb9 0xeed 0xba 0xee8 0xb9 0xee4 0xba 0xee0 0xb9 0xedc 0xba 0xed9 0xbb 0xed6 0xbc 0xed3 0xbc 0xed1 0xbc 0xece 0xbc 0xecc 0xbc 0xeca 0xbd 0xec7 0xbe 0xec4 0xbc 0xec2 0xc0 0xec0 0xc1 0xebd 0xc1 0xebb 0xc2 0xeb6 0xc3 0xeb3 0xc3 0xeb0 0xc4 0xeac 0xc4 0xea8 0xc4 0xea3 0xc6 0xe9e 0xc7 0xe98 0xc9 0xe92 0xcb 0xe8b 0xcd 0xe83 0xd1 0xe7c 0xd2 0xe72 0xd2 0xe67 0xd4 0xe5d 0xde 0xe57 0xea 0xe50 0xfa 0xe49 0x112 0xe40 0x139 0xe2c 0x166 0xdff 0x1a5 0xdbf 0x216 0xd67>;
			r_profile_t1_5_num_1 = <0x50>;
			r_profile_t1_5_1 = <0x94 0x1053 0x94 0x1020 0x92 0x1011 0x90 0x1004 0x91 0xff9 0x91 0xfee 0x92 0xfe4 0x92 0xfda 0x93 0xfd1 0x93 0xfc8 0x94 0xfbf 0x95 0xfb6 0x96 0xfae 0x96 0xfa6 0xa4 0xf9e 0xa5 0xf96 0xa5 0xf8f 0xa5 0xf87 0xa5 0xf80 0xa6 0xf79 0xa6 0xf72 0xa7 0xf6c 0xa7 0xf65 0xa7 0xf5f 0xa7 0xf59 0xa7 0xf52 0xa7 0xf4c 0xa7 0xf46 0xa7 0xf40 0xa6 0xf39 0xa6 0xf33 0xa5 0xf2c 0xa3 0xf25 0xa1 0xf1d 0x9f 0xf16 0x9c 0xf0f 0x99 0xf08 0x97 0xf01 0x95 0xefb 0x93 0xef5 0x91 0xef0 0x90 0xeeb 0x8f 0xee6 0x8f 0xee3 0x8e 0xedf 0x8e 0xedc 0x8e 0xed8 0x8f 0xed6 0x8e 0xed3 0x8e 0xed1 0x8f 0xece 0x8f 0xecc 0x8f 0xec8 0x8f 0xec5 0x8e 0xec4 0x90 0xec1 0x91 0xebe 0x93 0xeba 0x94 0xeb7 0x95 0xeb3 0x94 0xeaf 0x94 0xeaa 0x95 0xea6 0x97 0xea2 0x9a 0xe9e 0x9c 0xe98 0x9e 0xe92 0xa0 0xe8b 0xa3 0xe85 0xa8 0xe7e 0xa7 0xe75 0xa2 0xe6a 0xa3 0xe62 0xab 0xe5d 0xb7 0xe57 0xcd 0xe50 0x103 0xe48 0x148 0xe33 0x189 0xe07 0x1f4 0xdcc>;
			r_profile_t2_num_1 = <0x5a>;
			r_profile_t2_1 = <0x66 0x103c 0x66 0x102c 0x66 0x101f 0x66 0x1013 0x67 0x1008 0x67 0xffd 0x68 0xff3 0x68 0xfe9 0x68 0xfe0 0x69 0xfd7 0x6a 0xfce 0x6a 0xfc5 0x6b 0xfbd 0x6b 0xfb4 0x6c 0xfac 0x6d 0xfa4 0x6e 0xf9c 0x6e 0xf95 0x6f 0xf8e 0x70 0xf87 0x71 0xf7f 0x71 0xf79 0x72 0xf72 0x72 0xf6c 0x73 0xf65 0x74 0xf5f 0x75 0xf59 0x75 0xf53 0x77 0xf4d 0x78 0xf48 0x78 0xf42 0x79 0xf3c 0x79 0xf36 0x79 0xf30 0x79 0xf2a 0x78 0xf23 0x76 0xf1c 0x73 0xf14 0x71 0xf0c 0x6f 0xf05 0x6d 0xefe 0x6c 0xef8 0x6b 0xef2 0x6b 0xeed 0x6a 0xee9 0x6a 0xee4 0x6a 0xee1 0x6a 0xedd 0x6a 0xeda 0x6b 0xed7 0x6b 0xed5 0x6b 0xed2 0x6c 0xecf 0x6c 0xecd 0x6c 0xecb 0x6d 0xec9 0x6e 0xec8 0x6e 0xec6 0x6f 0xec4 0x6f 0xec3 0x70 0xec2 0x70 0xec1 0x71 0xebf 0x70 0xebd 0x6f 0xeba 0x6d 0xeb6 0x6c 0xeb1 0x6c 0xead 0x6b 0xea8 0x6b 0xea4 0x6b 0xe9f 0x6c 0xe9c 0x6c 0xe98 0x6c 0xe93 0x6c 0xe8e 0x6c 0xe88 0x6c 0xe81 0x6d 0xe7b 0x6d 0xe74 0x6d 0xe6b 0x6e 0xe61 0x6e 0xe5b 0x70 0xe56 0x72 0xe51 0x74 0xe4b 0x77 0xe42 0x75 0xe2b 0x75 0xdff 0x79 0xdc5 0x7d 0xd79>;
			r_profile_t3_num_1 = <0x5a>;
			r_profile_t3_1 = <0x5d 0x1038 0x5d 0x1029 0x5d 0x101c 0x5d 0x1010 0x5d 0x1005 0x5d 0xffa 0x5d 0xff0 0x5e 0xfe6 0x5e 0xfdd 0x5e 0xfd4 0x5e 0xfcb 0x5f 0xfc2 0x5f 0xfba 0x5f 0xfb1 0x60 0xfa9 0x60 0xfa1 0x61 0xf99 0x61 0xf92 0x61 0xf8a 0x61 0xf83 0x62 0xf7c 0x63 0xf75 0x63 0xf6e 0x64 0xf68 0x64 0xf62 0x64 0xf5b 0x66 0xf55 0x66 0xf4f 0x67 0xf4a 0x68 0xf44 0x69 0xf3e 0x6a 0xf39 0x6b 0xf34 0x6b 0xf2e 0x6c 0xf28 0x6b 0xf22 0x6b 0xf1b 0x69 0xf12 0x65 0xf09 0x63 0xf00 0x62 0xef9 0x61 0xef3 0x61 0xeed 0x62 0xee9 0x62 0xee5 0x62 0xee1 0x61 0xedd 0x62 0xeda 0x62 0xed6 0x62 0xed3 0x62 0xed1 0x63 0xece 0x63 0xecc 0x63 0xec9 0x63 0xec7 0x64 0xec5 0x64 0xec3 0x65 0xec1 0x65 0xebf 0x66 0xebe 0x67 0xebc 0x68 0xebb 0x68 0xeb8 0x64 0xeb2 0x61 0xeaa 0x62 0xea3 0x63 0xe9e 0x63 0xe9a 0x63 0xe95 0x63 0xe90 0x63 0xe8c 0x63 0xe88 0x64 0xe85 0x64 0xe80 0x64 0xe7a 0x64 0xe73 0x64 0xe6d 0x65 0xe66 0x65 0xe5e 0x65 0xe55 0x65 0xe50 0x66 0xe4c 0x68 0xe48 0x69 0xe43 0x6a 0xe3a 0x69 0xe23 0x69 0xdf9 0x6c 0xdc2 0x6f 0xd7b 0x76 0xd17>;
			battery_profile_t1_500cycle_1 = <0x0 0x1060 0x1 0x105b 0x2 0x104d 0x4 0x1041 0x5 0x1036 0x6 0x102b 0x7 0x1020 0x8 0x1016 0x9 0x100b 0xb 0x1002 0xc 0xff8 0xd 0xfee 0xe 0xfe5 0xf 0xfdc 0x11 0xfd3 0x12 0xfca 0x13 0xfc1 0x14 0xfb9 0x15 0xfb0 0x17 0xfa9 0x18 0xfa0 0x19 0xf99 0x1a 0xf91 0x1b 0xf8a 0x1c 0xf83 0x1e 0xf7c 0x1f 0xf75 0x20 0xf6e 0x21 0xf67 0x22 0xf5f 0x24 0xf58 0x25 0xf51 0x26 0xf49 0x27 0xf40 0x28 0xf38 0x29 0xf2f 0x2b 0xf26 0x2c 0xf1e 0x2d 0xf17 0x2e 0xf10 0x2f 0xf09 0x31 0xf03 0x32 0xefe 0x33 0xef9 0x34 0xef5 0x35 0xef0 0x36 0xeed 0x38 0xee9 0x39 0xee6 0x3a 0xee2 0x3b 0xedf 0x3e 0xed9 0x40 0xed5 0x41 0xed2 0x44 0xece 0x46 0xeca 0x47 0xec8 0x49 0xec3 0x4b 0xec0 0x4c 0xebb 0x4d 0xeb6 0x4e 0xeb1 0x4f 0xead 0x51 0xea9 0x52 0xea4 0x53 0xe9e 0x54 0xe98 0x55 0xe91 0x56 0xe8a 0x58 0xe82 0x59 0xe78 0x5a 0xe71 0x5b 0xe6b 0x5c 0xe66 0x5e 0xe5f 0x5f 0xe54 0x60 0xe40 0x61 0xe13 0x62 0xdd3 0x64 0xd7d>;
			battery_profile_t1_5_500cycle_1 = <0x0 0x105c 0x1 0x104e 0x2 0x1042 0x4 0x1037 0x5 0x102b 0x6 0x1021 0x7 0x1016 0x8 0x100c 0xa 0x1002 0xb 0xff9 0xc 0xfef 0xd 0xfe5 0xe 0xfdc 0x10 0xfd3 0x11 0xfca 0x12 0xfc2 0x13 0xfba 0x14 0xfb1 0x16 0xfa9 0x17 0xfa1 0x18 0xf9a 0x19 0xf93 0x1a 0xf8b 0x1c 0xf84 0x1d 0xf7d 0x1e 0xf76 0x1f 0xf70 0x20 0xf69 0x22 0xf62 0x23 0xf5c 0x24 0xf55 0x25 0xf4e 0x26 0xf46 0x28 0xf3d 0x29 0xf33 0x2a 0xf2a 0x2b 0xf20 0x2c 0xf18 0x2e 0xf11 0x2f 0xf0b 0x30 0xf05 0x31 0xf00 0x32 0xefb 0x34 0xef6 0x35 0xef2 0x36 0xeee 0x37 0xeeb 0x38 0xee7 0x3a 0xee4 0x3b 0xee1 0x3c 0xede 0x3d 0xedb 0x40 0xed6 0x42 0xed1 0x43 0xecf 0x46 0xecb 0x48 0xec6 0x49 0xec2 0x4a 0xebd 0x4c 0xeb7 0x4d 0xeb1 0x4e 0xead 0x4f 0xea9 0x50 0xea5 0x52 0xea1 0x53 0xe9c 0x54 0xe96 0x55 0xe8f 0x56 0xe89 0x57 0xe80 0x59 0xe77 0x5a 0xe70 0x5b 0xe6c 0x5c 0xe67 0x5d 0xe61 0x5f 0xe58 0x60 0xe42 0x61 0xe14 0x62 0xdd5 0x64 0xd80>;
			battery_profile_t2_500cycle_1 = <0x0 0x1054 0x1 0x1044 0x2 0x1036 0x4 0x1029 0x5 0x101d 0x6 0x1012 0x7 0x1007 0x8 0xffc 0xa 0xff2 0xb 0xfe8 0xc 0xfdf 0xd 0xfd5 0xe 0xfcc 0x10 0xfc3 0x11 0xfbb 0x12 0xfb1 0x13 0xfa9 0x14 0xfa0 0x16 0xf99 0x17 0xf90 0x18 0xf89 0x19 0xf82 0x1a 0xf7b 0x1c 0xf74 0x1d 0xf6c 0x1e 0xf66 0x1f 0xf5e 0x20 0xf58 0x22 0xf51 0x23 0xf4b 0x24 0xf44 0x25 0xf3e 0x26 0xf37 0x28 0xf30 0x29 0xf28 0x2a 0xf1f 0x2b 0xf15 0x2c 0xf0c 0x2d 0xf04 0x2f 0xeff 0x30 0xef8 0x31 0xef3 0x32 0xeed 0x33 0xee8 0x35 0xee4 0x36 0xee0 0x37 0xedc 0x39 0xed5 0x3b 0xed1 0x3d 0xecb 0x3f 0xec6 0x42 0xec1 0x43 0xebe 0x44 0xebc 0x45 0xeba 0x47 0xeb6 0x48 0xeb2 0x49 0xead 0x4a 0xea6 0x4b 0xea0 0x4d 0xe9b 0x4e 0xe96 0x4f 0xe92 0x50 0xe8e 0x51 0xe8a 0x53 0xe85 0x54 0xe80 0x55 0xe7a 0x56 0xe73 0x57 0xe6c 0x59 0xe62 0x5a 0xe5c 0x5b 0xe58 0x5c 0xe53 0x5d 0xe4e 0x5f 0xe45 0x60 0xe33 0x61 0xe09 0x62 0xdcf 0x64 0xd82>;
			battery_profile_t3_500cycle_1 = <0x0 0x1057 0x1 0x104a 0x2 0x103d 0x4 0x1032 0x5 0x1027 0x6 0x101c 0x7 0x1012 0x8 0x1007 0xa 0xffe 0xb 0xff4 0xc 0xfea 0xd 0xfe1 0xe 0xfd8 0x10 0xfcf 0x11 0xfc6 0x12 0xfbe 0x13 0xfb5 0x14 0xfad 0x16 0xfa5 0x17 0xf9d 0x18 0xf95 0x19 0xf8e 0x1a 0xf86 0x1c 0xf7f 0x1d 0xf78 0x1e 0xf71 0x1f 0xf6b 0x20 0xf64 0x22 0xf5e 0x23 0xf57 0x24 0xf51 0x25 0xf4a 0x27 0xf43 0x28 0xf3b 0x29 0xf31 0x2a 0xf26 0x2b 0xf1d 0x2d 0xf15 0x2e 0xf0e 0x2f 0xf08 0x30 0xf02 0x31 0xefd 0x33 0xef8 0x34 0xef4 0x35 0xef0 0x36 0xeec 0x39 0xee5 0x3b 0xedd 0x3d 0xed8 0x40 0xed2 0x41 0xed0 0x42 0xecd 0x43 0xeca 0x45 0xec7 0x46 0xec3 0x47 0xebc 0x48 0xeb3 0x49 0xeab 0x4b 0xea5 0x4c 0xe9f 0x4d 0xe99 0x4e 0xe95 0x4f 0xe90 0x51 0xe8d 0x52 0xe89 0x53 0xe84 0x54 0xe7e 0x55 0xe77 0x57 0xe71 0x58 0xe68 0x59 0xe60 0x5a 0xe5c 0x5b 0xe58 0x5d 0xe54 0x5e 0xe4e 0x5f 0xe42 0x60 0xe20 0x61 0xdee 0x63 0xdad 0x64 0xd56>;
			r_profile_t1_500cycle_1 = <0xb1 0x1060 0xaf 0x105b 0xb0 0x104d 0xb1 0x1041 0xb2 0x1036 0xb3 0x102b 0xb4 0x1020 0xb5 0x1016 0xb6 0x100b 0xb7 0x1002 0xb9 0xff8 0xba 0xfee 0xbb 0xfe5 0xbc 0xfdc 0xbd 0xfd3 0xbe 0xfca 0xbf 0xfc1 0xc0 0xfb9 0xc1 0xfb0 0xc3 0xfa9 0xc4 0xfa0 0xc4 0xf99 0xc6 0xf91 0xc7 0xf8a 0xc8 0xf83 0xc8 0xf7c 0xc9 0xf75 0xca 0xf6e 0xca 0xf67 0xca 0xf5f 0xca 0xf58 0xc9 0xf51 0xc8 0xf49 0xc6 0xf40 0xc4 0xf38 0xc1 0xf2f 0xbf 0xf26 0xbd 0xf1e 0xbb 0xf17 0xbb 0xf10 0xba 0xf09 0xba 0xf03 0xba 0xefe 0xb9 0xef9 0xba 0xef5 0xba 0xef0 0xbb 0xeed 0xbb 0xee9 0xbc 0xee6 0xbd 0xee2 0xbd 0xedf 0xbf 0xed9 0xc0 0xed5 0xc1 0xed2 0xc1 0xece 0xc2 0xeca 0xc2 0xec8 0xc2 0xec3 0xc1 0xec0 0xc0 0xebb 0xbe 0xeb6 0xbf 0xeb1 0xbf 0xead 0xc0 0xea9 0xc0 0xea4 0xc1 0xe9e 0xc1 0xe98 0xc2 0xe91 0xc3 0xe8a 0xc3 0xe82 0xc2 0xe78 0xc2 0xe71 0xc5 0xe6b 0xca 0xe66 0xd0 0xe5f 0xd9 0xe54 0xde 0xe40 0xdb 0xe13 0xe0 0xdd3 0xed 0xd7d>;
			r_profile_t1_5_500cycle_1 = <0x7b 0x105c 0x86 0x104e 0x87 0x1042 0x87 0x1037 0x88 0x102b 0x89 0x1021 0x89 0x1016 0x8b 0x100c 0x8b 0x1002 0x8d 0xff9 0x8d 0xfef 0x8e 0xfe5 0x8e 0xfdc 0x90 0xfd3 0x90 0xfca 0x91 0xfc2 0x93 0xfba 0x93 0xfb1 0x95 0xfa9 0x95 0xfa1 0x96 0xf9a 0x97 0xf93 0x98 0xf8b 0x99 0xf84 0x9a 0xf7d 0x9a 0xf76 0x9c 0xf70 0x9c 0xf69 0x9d 0xf62 0x9e 0xf5c 0x9e 0xf55 0x9e 0xf4e 0x9d 0xf46 0x9b 0xf3d 0x97 0xf33 0x94 0xf2a 0x91 0xf20 0x90 0xf18 0x90 0xf11 0x8f 0xf0b 0x8f 0xf05 0x8f 0xf00 0x8f 0xefb 0x8f 0xef6 0x8f 0xef2 0x8f 0xeee 0x90 0xeeb 0x90 0xee7 0x91 0xee4 0x92 0xee1 0x92 0xede 0x93 0xedb 0x94 0xed6 0x95 0xed1 0x96 0xecf 0x96 0xecb 0x95 0xec6 0x93 0xec2 0x92 0xebd 0x90 0xeb7 0x8f 0xeb1 0x8f 0xead 0x91 0xea9 0x91 0xea5 0x92 0xea1 0x92 0xe9c 0x92 0xe96 0x92 0xe8f 0x93 0xe89 0x94 0xe80 0x92 0xe77 0x93 0xe70 0x94 0xe6c 0x96 0xe67 0x9b 0xe61 0xa0 0xe58 0xa0 0xe42 0x9c 0xe14 0x9f 0xdd5 0xa5 0xd80>;
			r_profile_t2_500cycle_1 = <0x6d 0x1054 0x6d 0x1044 0x6d 0x1036 0x6d 0x1029 0x6e 0x101d 0x6f 0x1012 0x6f 0x1007 0x6e 0xffc 0x70 0xff2 0x70 0xfe8 0x71 0xfdf 0x70 0xfd5 0x72 0xfcc 0x71 0xfc3 0x73 0xfbb 0x72 0xfb1 0x74 0xfa9 0x74 0xfa0 0x75 0xf99 0x75 0xf90 0x77 0xf89 0x78 0xf82 0x79 0xf7b 0x7a 0xf74 0x7a 0xf6c 0x7b 0xf66 0x7b 0xf5e 0x7d 0xf58 0x7d 0xf51 0x7d 0xf4b 0x7e 0xf44 0x7e 0xf3e 0x7e 0xf37 0x7e 0xf30 0x7d 0xf28 0x79 0xf1f 0x77 0xf15 0x75 0xf0c 0x73 0xf04 0x75 0xeff 0x74 0xef8 0x73 0xef3 0x73 0xeed 0x72 0xee8 0x73 0xee4 0x72 0xee0 0x73 0xedc 0x73 0xed5 0x74 0xed1 0x75 0xecb 0x75 0xec6 0x77 0xec1 0x77 0xebe 0x79 0xebc 0x79 0xeba 0x78 0xeb6 0x76 0xeb2 0x74 0xead 0x72 0xea6 0x72 0xea0 0x71 0xe9b 0x72 0xe96 0x72 0xe92 0x72 0xe8e 0x73 0xe8a 0x74 0xe85 0x73 0xe80 0x74 0xe7a 0x74 0xe73 0x74 0xe6c 0x73 0xe62 0x74 0xe5c 0x76 0xe58 0x76 0xe53 0x78 0xe4e 0x7c 0xe45 0x7f 0xe33 0x78 0xe09 0x7b 0xdcf 0x80 0xd82>;
			r_profile_t3_500cycle_1 = <0x61 0x1057 0x61 0x104a 0x61 0x103d 0x61 0x1032 0x61 0x1027 0x62 0x101c 0x62 0x1012 0x62 0x1007 0x62 0xffe 0x63 0xff4 0x63 0xfea 0x63 0xfe1 0x63 0xfd8 0x64 0xfcf 0x64 0xfc6 0x65 0xfbe 0x65 0xfb5 0x66 0xfad 0x66 0xfa5 0x66 0xf9d 0x67 0xf95 0x67 0xf8e 0x68 0xf86 0x6a 0xf7f 0x69 0xf78 0x6a 0xf71 0x6c 0xf6b 0x6c 0xf64 0x6c 0xf5e 0x6d 0xf57 0x6e 0xf51 0x6f 0xf4a 0x6f 0xf43 0x6e 0xf3b 0x6b 0xf31 0x68 0xf26 0x67 0xf1d 0x67 0xf15 0x67 0xf0e 0x66 0xf08 0x66 0xf02 0x67 0xefd 0x67 0xef8 0x67 0xef4 0x67 0xef0 0x67 0xeec 0x68 0xee5 0x68 0xedd 0x6a 0xed8 0x6b 0xed2 0x6c 0xed0 0x6d 0xecd 0x6c 0xeca 0x6d 0xec7 0x6c 0xec3 0x69 0xebc 0x67 0xeb3 0x67 0xeab 0x68 0xea5 0x67 0xe9f 0x67 0xe99 0x68 0xe95 0x68 0xe90 0x68 0xe8d 0x68 0xe89 0x69 0xe84 0x69 0xe7e 0x69 0xe77 0x69 0xe71 0x69 0xe68 0x69 0xe60 0x69 0xe5c 0x6a 0xe58 0x6b 0xe54 0x6d 0xe4e 0x6f 0xe42 0x6c 0xe20 0x6d 0xdee 0x71 0xdad 0x76 0xd56>;
			battery_vendor_2 = "COSLIGHT";
			q_max_pos_50_2 = <0x11f4>;
			q_max_pos_25_2 = <0x121e>;
			q_max_pos_10_2 = <0x11c7>;
			q_max_pos_0_2 = <0x13e3>;
			q_max_neg_10_2 = <0x105e>;
			q_max_pos_50_h_current_2 = <0x11b4>;
			q_max_pos_25_h_current_2 = <0x11c7>;
			q_max_pos_10_h_current_2 = <0x10f5>;
			q_max_pos_0_h_current_2 = <0x10c8>;
			q_max_neg_10_h_current_2 = <0x75a>;
			q_max_pos_50_500cycle_2 = <0x11b2>;
			q_max_pos_25_500cycle_2 = <0x1250>;
			q_max_pos_10_500cycle_2 = <0x1212>;
			q_max_pos_0_500cycle_2 = <0x120b>;
			q_max_neg_10_500cycle_2 = <0x11b8>;
			q_max_pos_50_h_current_500cycle_2 = <0x1167>;
			q_max_pos_25_h_current_500cycle_2 = <0x11f0>;
			q_max_pos_10_h_current_500cycle_2 = <0x113e>;
			q_max_pos_0_h_current_500cycle_2 = <0xf23>;
			q_max_neg_10_h_current_500cycle_2 = <0x789>;
			battery_profile_t0_num_2 = <0x53>;
			battery_profile_t0_2 = <0x0 0x1043 0x1 0x1026 0x2 0x1013 0x4 0x1004 0x5 0xff6 0x6 0xfeb 0x7 0xfdf 0x9 0xfd3 0xa 0xfc6 0xb 0xfb8 0xc 0xfa9 0xd 0xf9b 0xf 0xf8f 0x10 0xf84 0x11 0xf7a 0x12 0xf71 0x14 0xf68 0x15 0xf60 0x16 0xf58 0x17 0xf50 0x18 0xf49 0x1a 0xf41 0x1b 0xf39 0x1c 0xf31 0x1d 0xf2a 0x1f 0xf21 0x20 0xf1a 0x21 0xf11 0x22 0xf09 0x24 0xf01 0x25 0xef9 0x26 0xef1 0x27 0xee9 0x28 0xee1 0x2a 0xedb 0x2b 0xed4 0x2c 0xece 0x2d 0xec9 0x2f 0xec4 0x30 0xebf 0x31 0xeba 0x32 0xeb6 0x33 0xeb1 0x35 0xead 0x36 0xeaa 0x37 0xea5 0x38 0xea2 0x3a 0xe9e 0x3b 0xe9a 0x3c 0xe96 0x3d 0xe92 0x3e 0xe8e 0x40 0xe89 0x41 0xe85 0x42 0xe80 0x43 0xe7c 0x45 0xe77 0x46 0xe71 0x47 0xe6c 0x48 0xe67 0x49 0xe61 0x4b 0xe5b 0x4c 0xe55 0x4d 0xe4e 0x4e 0xe48 0x50 0xe41 0x51 0xe3a 0x52 0xe33 0x53 0xe2b 0x54 0xe23 0x56 0xe1b 0x57 0xe12 0x58 0xe09 0x59 0xe00 0x5b 0xdf6 0x5c 0xdec 0x5d 0xde2 0x5e 0xdd9 0x5f 0xdd0 0x61 0xdc7 0x62 0xdbe 0x63 0xdb5 0x64 0xdae>;
			battery_profile_t1_num_2 = <0x5b>;
			battery_profile_t1_2 = <0x0 0x1057 0x1 0x1041 0x2 0x1031 0x3 0x1023 0x4 0x1017 0x6 0x100b 0x7 0x1001 0x8 0xff8 0x9 0xff0 0xa 0xfe8 0xb 0xfde 0xc 0xfd0 0xd 0xfc1 0xe 0xfb1 0x10 0xfa4 0x11 0xf99 0x12 0xf8f 0x13 0xf87 0x14 0xf80 0x15 0xf7a 0x16 0xf75 0x17 0xf70 0x18 0xf6a 0x1a 0xf64 0x1b 0xf5e 0x1c 0xf57 0x1d 0xf51 0x1e 0xf4a 0x1f 0xf43 0x20 0xf3d 0x21 0xf36 0x23 0xf2f 0x24 0xf28 0x25 0xf20 0x26 0xf18 0x27 0xf0f 0x28 0xf06 0x29 0xefe 0x2a 0xef6 0x2b 0xeef 0x2d 0xee9 0x2e 0xee3 0x2f 0xede 0x30 0xed9 0x31 0xed5 0x32 0xed2 0x33 0xecf 0x34 0xecb 0x35 0xec9 0x37 0xec6 0x38 0xec5 0x39 0xec3 0x3a 0xec2 0x3b 0xec0 0x3c 0xebf 0x3d 0xebe 0x3e 0xebc 0x3f 0xebb 0x41 0xeb9 0x42 0xeb7 0x43 0xeb5 0x44 0xeb3 0x45 0xeb0 0x46 0xead 0x47 0xea9 0x48 0xea5 0x49 0xea0 0x4b 0xe9b 0x4c 0xe95 0x4d 0xe8e 0x4e 0xe91 0x4f 0xe83 0x50 0xe78 0x51 0xe6c 0x52 0xe60 0x54 0xe53 0x55 0xe44 0x56 0xe36 0x57 0xe27 0x58 0xe19 0x59 0xe09 0x5a 0xdf9 0x5b 0xddc 0x5c 0xdd5 0x5e 0xdcc 0x5f 0xdc3 0x60 0xdba 0x61 0xdaf 0x62 0xd9d 0x63 0xd77 0x64 0xd3d>;
			battery_profile_t1_5_num_2 = <0x5a>;
			battery_profile_t1_5_2 = <0x0 0x105d 0x1 0x104d 0x2 0x1040 0x3 0x1034 0x5 0x1028 0x6 0x101c 0x7 0x1010 0x8 0x1005 0x9 0xffb 0xa 0xff2 0xb 0xfea 0xc 0xfe2 0xe 0xfd8 0xf 0xfcb 0x10 0xfbc 0x11 0xfae 0x12 0xfa2 0x13 0xf97 0x14 0xf8f 0x15 0xf88 0x17 0xf82 0x18 0xf7d 0x19 0xf77 0x1a 0xf71 0x1b 0xf6a 0x1c 0xf63 0x1d 0xf5b 0x1e 0xf54 0x20 0xf4e 0x21 0xf47 0x22 0xf40 0x23 0xf39 0x24 0xf32 0x25 0xf2b 0x26 0xf24 0x27 0xf1c 0x29 0xf13 0x2a 0xf09 0x2b 0xf00 0x2c 0xef7 0x2d 0xeef 0x2e 0xee8 0x2f 0xee2 0x30 0xedd 0x32 0xed9 0x33 0xed5 0x34 0xed1 0x35 0xece 0x36 0xecb 0x37 0xec9 0x38 0xec8 0x39 0xec6 0x3b 0xec5 0x3c 0xec5 0x3d 0xec4 0x3e 0xec3 0x3f 0xec2 0x40 0xec1 0x41 0xec0 0x42 0xebf 0x44 0xebe 0x45 0xebd 0x46 0xebb 0x47 0xeb9 0x48 0xeb7 0x49 0xeb4 0x4a 0xeb1 0x4c 0xead 0x4d 0xea8 0x4e 0xea2 0x4f 0xe9c 0x50 0xe94 0x51 0xe8c 0x52 0xe83 0x53 0xe79 0x55 0xe6c 0x56 0xe5d 0x57 0xe4c 0x58 0xe3a 0x59 0xe27 0x5a 0xe13 0x5b 0xe00 0x5c 0xdf2 0x5e 0xde5 0x5f 0xdda 0x60 0xdcf 0x61 0xdc2 0x62 0xdab 0x63 0xd7a 0x64 0xd36>;
			battery_profile_t2_num_2 = <0x5b>;
			battery_profile_t2_2 = <0x0 0x1060 0x1 0x1052 0x2 0x1041 0x3 0x1034 0x4 0x1027 0x6 0x101c 0x7 0x101a 0x8 0x1005 0x9 0xffa 0xa 0xff0 0xb 0xfe7 0xc 0xfdf 0xd 0xfd6 0xe 0xfca 0x10 0xfbc 0x11 0xfaf 0x12 0xfa4 0x13 0xf9b 0x14 0xf95 0x15 0xf8f 0x16 0xf87 0x17 0xf80 0x18 0xf79 0x1a 0xf71 0x1b 0xf6a 0x1c 0xf62 0x1d 0xf5b 0x1e 0xf54 0x1f 0xf4d 0x20 0xf46 0x21 0xf40 0x22 0xf3a 0x24 0xf34 0x25 0xf2d 0x26 0xf28 0x27 0xf21 0x28 0xf1c 0x29 0xf15 0x2a 0xf0e 0x2b 0xf05 0x2c 0xefb 0x2d 0xef1 0x2f 0xee8 0x30 0xee2 0x31 0xedd 0x32 0xed8 0x33 0xed4 0x34 0xed1 0x35 0xece 0x36 0xecb 0x37 0xec9 0x39 0xec7 0x3a 0xec5 0x3b 0xec3 0x3c 0xec2 0x3d 0xec2 0x3e 0xec1 0x3f 0xec0 0x40 0xec0 0x41 0xec0 0x43 0xebf 0x44 0xebf 0x45 0xebe 0x46 0xebd 0x47 0xebc 0x48 0xeba 0x49 0xeb8 0x4a 0xeb4 0x4b 0xeb0 0x4d 0xeac 0x4e 0xea7 0x4f 0xea3 0x50 0xe9d 0x51 0xe98 0x52 0xe92 0x53 0xe8b 0x54 0xe81 0x55 0xe73 0x57 0xe63 0x58 0xe50 0x59 0xe3b 0x5a 0xe23 0x5b 0xe0b 0x5c 0xdf7 0x5d 0xde8 0x5e 0xddc 0x5f 0xdd0 0x61 0xdc3 0x62 0xdb2 0x63 0xd8a 0x64 0xd4e>;
			battery_profile_t3_num_2 = <0x5b>;
			battery_profile_t3_2 = <0x0 0x1064 0x1 0x1053 0x2 0x1045 0x3 0x1037 0x4 0x102b 0x6 0x101e 0x7 0x1013 0x8 0x1008 0x9 0xffd 0xa 0xff2 0xb 0xfe8 0xc 0xfdd 0xd 0xfd4 0xf 0xfca 0x10 0xfc0 0x11 0xfb6 0x12 0xfac 0x13 0xfa3 0x14 0xf9b 0x15 0xf92 0x16 0xf8a 0x17 0xf82 0x19 0xf7a 0x1a 0xf72 0x1b 0xf6a 0x1c 0xf62 0x1d 0xf5b 0x1e 0xf54 0x1f 0xf4d 0x20 0xf46 0x21 0xf40 0x23 0xf39 0x24 0xf33 0x25 0xf2d 0x26 0xf27 0x27 0xf21 0x28 0xf1b 0x29 0xf15 0x2a 0xf0e 0x2c 0xf06 0x2d 0xefb 0x2e 0xef0 0x2f 0xee8 0x30 0xee2 0x31 0xedd 0x32 0xed8 0x33 0xed5 0x34 0xed1 0x36 0xece 0x37 0xecb 0x38 0xec8 0x39 0xec6 0x3a 0xec4 0x3b 0xec2 0x3c 0xec0 0x3d 0xebe 0x3f 0xebd 0x40 0xebc 0x41 0xebb 0x42 0xebb 0x43 0xebb 0x44 0xeba 0x45 0xeba 0x46 0xeb9 0x47 0xeb8 0x49 0xeb5 0x4a 0xeaf 0x4b 0xea8 0x4c 0xea4 0x4d 0xea0 0x4e 0xe9d 0x4f 0xe98 0x50 0xe94 0x51 0xe90 0x53 0xe8c 0x54 0xe87 0x55 0xe7f 0x56 0xe74 0x57 0xe65 0x58 0xe52 0x59 0xe3b 0x5a 0xe22 0x5c 0xe0b 0x5d 0xdf9 0x5e 0xdea 0x5f 0xdde 0x60 0xdd1 0x61 0xdc2 0x62 0xda4 0x63 0xd70 0x64 0xd2c>;
			r_profile_t0_num_2 = <0x53>;
			r_profile_t0_2 = <0x26c 0x1043 0x26c 0x1026 0x276 0x1013 0x27d 0x1004 0x280 0xff6 0x285 0xfeb 0x287 0xfdf 0x287 0xfd3 0x285 0xfc6 0x286 0xfb8 0x283 0xfa9 0x284 0xf9b 0x286 0xf8f 0x288 0xf84 0x28a 0xf7a 0x28c 0xf71 0x28d 0xf68 0x28e 0xf60 0x28d 0xf58 0x290 0xf50 0x28f 0xf49 0x28f 0xf41 0x290 0xf39 0x28f 0xf31 0x28e 0xf2a 0x28e 0xf21 0x28c 0xf1a 0x28b 0xf11 0x28b 0xf09 0x288 0xf01 0x287 0xef9 0x284 0xef1 0x284 0xee9 0x283 0xee1 0x284 0xedb 0x283 0xed4 0x284 0xece 0x283 0xec9 0x284 0xec4 0x286 0xebf 0x286 0xeba 0x286 0xeb6 0x287 0xeb1 0x289 0xead 0x28a 0xeaa 0x28c 0xea5 0x28f 0xea2 0x28e 0xe9e 0x290 0xe9a 0x292 0xe96 0x294 0xe92 0x297 0xe8e 0x299 0xe89 0x29b 0xe85 0x29e 0xe80 0x2a0 0xe7c 0x2a1 0xe77 0x2a4 0xe71 0x2a5 0xe6c 0x2a8 0xe67 0x2aa 0xe61 0x2ad 0xe5b 0x2b1 0xe55 0x2b4 0xe4e 0x2b8 0xe48 0x2bc 0xe41 0x2bf 0xe3a 0x2c3 0xe33 0x2c9 0xe2b 0x2d0 0xe23 0x2d6 0xe1b 0x2dd 0xe12 0x2e8 0xe09 0x2f3 0xe00 0x300 0xdf6 0x311 0xdec 0x328 0xde2 0x344 0xdd9 0x366 0xdd0 0x394 0xdc7 0x3d5 0xdbe 0x436 0xdb5 0x43f 0xdae>;
			r_profile_t1_num_2 = <0x5b>;
			r_profile_t1_2 = <0x120 0x1057 0x120 0x1041 0x127 0x1031 0x12c 0x1023 0x12e 0x1017 0x131 0x100b 0x134 0x1001 0x138 0xff8 0x13c 0xff0 0x13d 0xfe8 0x13c 0xfde 0x138 0xfd0 0x136 0xfc1 0x135 0xfb1 0x138 0xfa4 0x13a 0xf99 0x13d 0xf8f 0x141 0xf87 0x144 0xf80 0x147 0xf7a 0x149 0xf75 0x14b 0xf70 0x14c 0xf6a 0x14d 0xf64 0x14d 0xf5e 0x14e 0xf57 0x14f 0xf51 0x150 0xf4a 0x152 0xf43 0x152 0xf3d 0x154 0xf36 0x155 0xf2f 0x155 0xf28 0x154 0xf20 0x153 0xf18 0x151 0xf0f 0x150 0xf06 0x14f 0xefe 0x14e 0xef6 0x14f 0xeef 0x14f 0xee9 0x14f 0xee3 0x150 0xede 0x151 0xed9 0x153 0xed5 0x154 0xed2 0x15a 0xecf 0x151 0xecb 0x158 0xec9 0x15d 0xec6 0x15f 0xec5 0x16d 0xec3 0x161 0xec2 0x168 0xec0 0x16d 0xebf 0x16e 0xebe 0x175 0xebc 0x16c 0xebb 0x17b 0xeb9 0x17b 0xeb7 0x17e 0xeb5 0x180 0xeb3 0x17c 0xeb0 0x18d 0xead 0x188 0xea9 0x18d 0xea5 0x18f 0xea0 0x190 0xe9b 0x19b 0xe95 0x192 0xe8e 0x1a2 0xe91 0x19b 0xe83 0x194 0xe78 0x1a3 0xe6c 0x1a2 0xe60 0x1ab 0xe53 0x1a9 0xe44 0x1a3 0xe36 0x1b8 0xe27 0x1b1 0xe19 0x1ba 0xe09 0x1c1 0xdf9 0x1b9 0xddc 0x1e5 0xdd5 0x200 0xdcc 0x223 0xdc3 0x267 0xdba 0x2d7 0xdaf 0x39f 0xd9d 0x3e3 0xd77 0x382 0xd3d>;
			r_profile_t1_5_num_2 = <0x5a>;
			r_profile_t1_5_2 = <0xc9 0x105d 0xc9 0x104d 0xcc 0x1040 0xcc 0x1034 0xcd 0x1028 0xcd 0x101c 0xce 0x1010 0xce 0x1005 0xcf 0xffb 0xd0 0xff2 0xd3 0xfea 0xd6 0xfe2 0xd4 0xfd8 0xd1 0xfcb 0xd0 0xfbc 0xd0 0xfae 0xd1 0xfa2 0xd3 0xf97 0xd5 0xf8f 0xd8 0xf88 0xdb 0xf82 0xde 0xf7d 0xde 0xf77 0xde 0xf71 0xdf 0xf6a 0xdf 0xf63 0xe0 0xf5b 0xe2 0xf54 0xe3 0xf4e 0xe5 0xf47 0xe6 0xf40 0xe7 0xf39 0xe8 0xf32 0xe7 0xf2b 0xe7 0xf24 0xe6 0xf1c 0xe2 0xf13 0xde 0xf09 0xda 0xf00 0xd6 0xef7 0xd3 0xeef 0xd1 0xee8 0xd1 0xee2 0xd1 0xedd 0xd1 0xed9 0xd1 0xed5 0xd2 0xed1 0xd3 0xece 0xd4 0xecb 0xd5 0xec9 0xd6 0xec8 0xd8 0xec6 0xda 0xec5 0xdb 0xec5 0xdc 0xec4 0xdd 0xec3 0xdf 0xec2 0xe1 0xec1 0xe2 0xec0 0xe4 0xebf 0xe6 0xebe 0xe7 0xebd 0xe8 0xebb 0xe9 0xeb9 0xea 0xeb7 0xec 0xeb4 0xee 0xeb1 0xed 0xead 0xee 0xea8 0xee 0xea2 0xef 0xe9c 0xef 0xe94 0xef 0xe8c 0xf0 0xe83 0xf0 0xe79 0xef 0xe6c 0xed 0xe5d 0xea 0xe4c 0xe8 0xe3a 0xe5 0xe27 0xe2 0xe13 0xe0 0xe00 0xe0 0xdf2 0xe2 0xde5 0xe5 0xdda 0xeb 0xdcf 0xf3 0xdc2 0xfb 0xdab 0xfb 0xd7a 0x10a 0xd36>;
			r_profile_t2_num_2 = <0x5b>;
			r_profile_t2_2 = <0x83 0x1060 0x83 0x1052 0x7f 0x1041 0x80 0x1034 0x7f 0x1027 0x80 0x101c 0x80 0x101a 0x81 0x1005 0x81 0xffa 0x80 0xff0 0x82 0xfe7 0x85 0xfdf 0x84 0xfd6 0x82 0xfca 0x7f 0xfbc 0x81 0xfaf 0x81 0xfa4 0x84 0xf9b 0x85 0xf95 0x85 0xf8f 0x84 0xf87 0x85 0xf80 0x87 0xf79 0x86 0xf71 0x88 0xf6a 0x89 0xf62 0x89 0xf5b 0x8b 0xf54 0x8a 0xf4d 0x8b 0xf46 0x8e 0xf40 0x8f 0xf3a 0x90 0xf34 0x92 0xf2d 0x94 0xf28 0x95 0xf21 0x95 0xf1c 0x98 0xf15 0x97 0xf0e 0x93 0xf05 0x8f 0xefb 0x8a 0xef1 0x88 0xee8 0x85 0xee2 0x85 0xedd 0x86 0xed8 0x84 0xed4 0x86 0xed1 0x85 0xece 0x86 0xecb 0x87 0xec9 0x86 0xec7 0x88 0xec5 0x89 0xec3 0x8b 0xec2 0x8b 0xec2 0x8c 0xec1 0x8e 0xec0 0x8e 0xec0 0x90 0xec0 0x91 0xebf 0x92 0xebf 0x94 0xebe 0x95 0xebd 0x97 0xebc 0x96 0xeba 0x95 0xeb8 0x96 0xeb4 0x94 0xeb0 0x96 0xeac 0x95 0xea7 0x95 0xea3 0x96 0xe9d 0x98 0xe98 0x99 0xe92 0x99 0xe8b 0x99 0xe81 0x9a 0xe73 0x97 0xe63 0x96 0xe50 0x91 0xe3b 0x8e 0xe23 0x8b 0xe0b 0x8a 0xdf7 0x8a 0xde8 0x8b 0xddc 0x8f 0xdd0 0x92 0xdc3 0x94 0xdb2 0x93 0xd8a 0x97 0xd4e>;
			r_profile_t3_num_2 = <0x5b>;
			r_profile_t3_2 = <0x71 0x1064 0x71 0x1053 0x71 0x1045 0x71 0x1037 0x71 0x102b 0x71 0x101e 0x72 0x1013 0x71 0x1008 0x71 0xffd 0x72 0xff2 0x72 0xfe8 0x72 0xfdd 0x73 0xfd4 0x73 0xfca 0x73 0xfc0 0x73 0xfb6 0x73 0xfac 0x73 0xfa3 0x73 0xf9b 0x73 0xf92 0x74 0xf8a 0x74 0xf82 0x75 0xf7a 0x75 0xf72 0x75 0xf6a 0x75 0xf62 0x76 0xf5b 0x77 0xf54 0x77 0xf4d 0x78 0xf46 0x78 0xf40 0x79 0xf39 0x7a 0xf33 0x7b 0xf2d 0x7d 0xf27 0x7e 0xf21 0x80 0xf1b 0x81 0xf15 0x82 0xf0e 0x80 0xf06 0x7b 0xefb 0x77 0xef0 0x75 0xee8 0x75 0xee2 0x74 0xedd 0x74 0xed8 0x74 0xed5 0x74 0xed1 0x75 0xece 0x75 0xecb 0x75 0xec8 0x75 0xec6 0x75 0xec4 0x76 0xec2 0x76 0xec0 0x77 0xebe 0x77 0xebd 0x77 0xebc 0x78 0xebb 0x79 0xebb 0x7a 0xebb 0x7b 0xeba 0x7c 0xeba 0x7e 0xeb9 0x7e 0xeb8 0x7e 0xeb5 0x79 0xeaf 0x78 0xea8 0x79 0xea4 0x7b 0xea0 0x7b 0xe9d 0x7b 0xe98 0x7b 0xe94 0x7c 0xe90 0x7d 0xe8c 0x7f 0xe87 0x7e 0xe7f 0x7f 0xe74 0x7e 0xe65 0x7f 0xe52 0x7d 0xe3b 0x7b 0xe22 0x7a 0xe0b 0x79 0xdf9 0x79 0xdea 0x7a 0xdde 0x7c 0xdd1 0x7d 0xdc2 0x7b 0xda4 0x7b 0xd70 0x7e 0xd2c>;
			battery_profile_t1_500cycle_2 = <0x0 0x105b 0x1 0x104b 0x2 0x103d 0x4 0x1031 0x5 0x1024 0x6 0x1019 0x7 0x100e 0x8 0x1003 0x9 0xff9 0xb 0xff0 0xc 0xfe8 0xd 0xfdf 0xe 0xfd3 0xf 0xfc6 0x10 0xfb7 0x12 0xfaa 0x13 0xf9d 0x14 0xf93 0x15 0xf8a 0x16 0xf82 0x17 0xf7b 0x19 0xf75 0x1a 0xf6f 0x1b 0xf6a 0x1c 0xf63 0x1d 0xf5d 0x1e 0xf56 0x20 0xf4f 0x21 0xf48 0x22 0xf41 0x23 0xf3a 0x24 0xf32 0x25 0xf28 0x27 0xf1e 0x28 0xf12 0x29 0xf06 0x2a 0xefc 0x2b 0xef3 0x2c 0xeec 0x2e 0xee5 0x2f 0xee0 0x30 0xedb 0x31 0xed6 0x32 0xed2 0x33 0xece 0x35 0xecb 0x36 0xec8 0x37 0xec5 0x38 0xec2 0x39 0xec0 0x3a 0xebe 0x3c 0xebc 0x3d 0xeb9 0x3e 0xeb8 0x3f 0xeb6 0x40 0xeb3 0x41 0xeb2 0x43 0xeaf 0x44 0xead 0x45 0xeab 0x46 0xea8 0x47 0xea5 0x48 0xea1 0x4a 0xe9d 0x4b 0xe98 0x4c 0xe93 0x4d 0xe8c 0x4e 0xe85 0x50 0xe7e 0x51 0xe76 0x52 0xe6e 0x53 0xe64 0x54 0xe5a 0x55 0xe4e 0x57 0xe42 0x58 0xe34 0x59 0xe26 0x5a 0xe17 0x5b 0xe0a 0x5c 0xdff 0x5e 0xdf4 0x5f 0xde9 0x60 0xddc 0x61 0xdcb 0x62 0xdaa 0x63 0xd71 0x64 0xd23 0x64 0xd23 0x64 0xd23 0x64 0xd23 0x64 0xd23>;
			battery_profile_t1_5_500cycle_2 = <0x0 0x105d 0x1 0x104f 0x2 0x1042 0x4 0x1036 0x5 0x102a 0x6 0x101f 0x7 0x1014 0x8 0x1009 0x9 0xffe 0xb 0xff4 0xc 0xfec 0xd 0xfe4 0xe 0xfdb 0xf 0xfcf 0x10 0xfc1 0x12 0xfb3 0x13 0xfa6 0x14 0xf9b 0x15 0xf91 0x16 0xf89 0x17 0xf83 0x19 0xf7e 0x1a 0xf78 0x1b 0xf72 0x1c 0xf6c 0x1d 0xf65 0x1e 0xf5e 0x20 0xf57 0x21 0xf50 0x22 0xf49 0x23 0xf42 0x24 0xf3b 0x25 0xf33 0x27 0xf2a 0x28 0xf1f 0x29 0xf13 0x2a 0xf07 0x2b 0xefd 0x2c 0xef5 0x2e 0xeef 0x2f 0xee9 0x30 0xee4 0x31 0xedf 0x32 0xedb 0x33 0xed7 0x35 0xed3 0x36 0xed0 0x37 0xecd 0x38 0xecc 0x39 0xec9 0x3a 0xec6 0x3c 0xec5 0x3d 0xec4 0x3e 0xec2 0x3f 0xec1 0x40 0xec0 0x41 0xebf 0x43 0xebe 0x44 0xebd 0x45 0xebc 0x46 0xebb 0x47 0xeb9 0x48 0xeb6 0x4a 0xeb3 0x4b 0xeaf 0x4c 0xeaa 0x4d 0xea4 0x4e 0xe9f 0x4f 0xe99 0x51 0xe93 0x52 0xe8d 0x53 0xe85 0x54 0xe7c 0x55 0xe72 0x56 0xe66 0x58 0xe59 0x59 0xe4a 0x5a 0xe3a 0x5b 0xe2a 0x5c 0xe1b 0x5d 0xe0b 0x5f 0xdfb 0x60 0xdeb 0x61 0xdd6 0x62 0xdb5 0x63 0xd7b 0x64 0xd2e>;
			battery_profile_t2_500cycle_2 = <0x0 0x105f 0x1 0x1051 0x2 0x1044 0x3 0x1038 0x5 0x102c 0x6 0x1021 0x7 0x1016 0x8 0x100b 0x9 0x1000 0xa 0xff5 0xc 0xfec 0xd 0xfe4 0xe 0xfdc 0xf 0xfd0 0x10 0xfc3 0x11 0xfb5 0x12 0xfa9 0x14 0xf9f 0x15 0xf98 0x16 0xf92 0x17 0xf8b 0x18 0xf84 0x19 0xf7d 0x1a 0xf76 0x1c 0xf6e 0x1d 0xf67 0x1e 0xf60 0x1f 0xf59 0x20 0xf52 0x21 0xf4b 0x23 0xf44 0x24 0xf3e 0x25 0xf37 0x26 0xf30 0x27 0xf29 0x28 0xf20 0x29 0xf14 0x2b 0xf08 0x2c 0xefe 0x2d 0xef6 0x2e 0xeef 0x2f 0xeea 0x30 0xee5 0x32 0xee0 0x33 0xedc 0x34 0xed8 0x35 0xed5 0x36 0xed2 0x37 0xece 0x38 0xecc 0x3a 0xec9 0x3b 0xec7 0x3c 0xec5 0x3d 0xec4 0x3e 0xec3 0x3f 0xec2 0x41 0xec1 0x42 0xec1 0x43 0xec0 0x44 0xec0 0x45 0xebf 0x46 0xebe 0x47 0xebc 0x49 0xeb8 0x4a 0xeb4 0x4b 0xeb0 0x4c 0xeab 0x4d 0xea7 0x4e 0xea2 0x4f 0xe9e 0x51 0xe99 0x52 0xe95 0x53 0xe90 0x54 0xe89 0x55 0xe80 0x56 0xe76 0x58 0xe6a 0x59 0xe5c 0x5a 0xe4c 0x5b 0xe3a 0x5c 0xe25 0x5d 0xe0e 0x5e 0xdf9 0x60 0xde6 0x61 0xdd2 0x62 0xdb6 0x63 0xd83 0x64 0xd3b 0x64 0xd3b 0x64 0xd3b 0x64 0xd3b>;
			battery_profile_t3_500cycle_2 = <0x0 0x1062 0x1 0x1054 0x2 0x1046 0x4 0x103a 0x5 0x102e 0x6 0x1022 0x7 0x1016 0x8 0x100b 0xa 0x1000 0xb 0xff5 0xc 0xfea 0xd 0xfdf 0xe 0xfd5 0xf 0xfcb 0x11 0xfc1 0x12 0xfb7 0x13 0xfad 0x14 0xfa3 0x15 0xf9b 0x17 0xf92 0x18 0xf89 0x19 0xf80 0x1a 0xf78 0x1b 0xf70 0x1d 0xf68 0x1e 0xf60 0x1f 0xf59 0x20 0xf51 0x21 0xf4a 0x23 0xf43 0x24 0xf3b 0x25 0xf34 0x26 0xf2d 0x27 0xf25 0x29 0xf1c 0x2a 0xf12 0x2b 0xf08 0x2c 0xefe 0x2d 0xef5 0x2e 0xeee 0x30 0xee8 0x31 0xee3 0x32 0xede 0x33 0xed9 0x34 0xed4 0x36 0xed2 0x37 0xece 0x38 0xecb 0x39 0xec8 0x3a 0xec5 0x3c 0xec2 0x3d 0xec0 0x3e 0xebe 0x3f 0xebc 0x40 0xeba 0x42 0xeba 0x43 0xeb8 0x44 0xeb7 0x45 0xeb5 0x46 0xeb4 0x48 0xeb0 0x49 0xeaa 0x4a 0xea3 0x4b 0xe9e 0x4c 0xe9a 0x4d 0xe95 0x4f 0xe90 0x50 0xe8c 0x51 0xe89 0x52 0xe85 0x53 0xe80 0x55 0xe7a 0x56 0xe72 0x57 0xe69 0x58 0xe5e 0x59 0xe55 0x5b 0xe4b 0x5c 0xe39 0x5d 0xe20 0x5e 0xe07 0x5f 0xdef 0x61 0xdd6 0x62 0xdb8 0x63 0xd87 0x64 0xd3f 0x64 0xd3f 0x64 0xd3f 0x64 0xd3f 0x64 0xd3f 0x64 0xd3f 0x64 0xd3f>;
			r_profile_t1_500cycle_2 = <0x18b 0x105b 0x18b 0x104b 0x18b 0x103d 0x18d 0x1031 0x18b 0x1024 0x18b 0x1019 0x18b 0x100e 0x189 0x1003 0x189 0xff9 0x189 0xff0 0x18b 0xfe8 0x18b 0xfdf 0x188 0xfd3 0x183 0xfc6 0x17f 0xfb7 0x17e 0xfaa 0x17e 0xf9d 0x181 0xf93 0x183 0xf8a 0x184 0xf82 0x188 0xf7b 0x18b 0xf75 0x18d 0xf6f 0x190 0xf6a 0x190 0xf63 0x193 0xf5d 0x195 0xf56 0x197 0xf4f 0x198 0xf48 0x19a 0xf41 0x19c 0xf3a 0x19d 0xf32 0x19a 0xf28 0x198 0xf1e 0x192 0xf12 0x18b 0xf06 0x188 0xefc 0x184 0xef3 0x183 0xeec 0x181 0xee5 0x183 0xee0 0x186 0xedb 0x188 0xed6 0x189 0xed2 0x189 0xece 0x18d 0xecb 0x190 0xec8 0x192 0xec5 0x193 0xec2 0x197 0xec0 0x198 0xebe 0x19d 0xebc 0x19d 0xeb9 0x1a2 0xeb8 0x1a4 0xeb6 0x1a6 0xeb3 0x1ab 0xeb2 0x1ac 0xeaf 0x1b0 0xead 0x1b3 0xeab 0x1b5 0xea8 0x1b8 0xea5 0x1ba 0xea1 0x1bb 0xe9d 0x1bd 0xe98 0x1c0 0xe93 0x1c0 0xe8c 0x1c2 0xe85 0x1c5 0xe7e 0x1c7 0xe76 0x1ca 0xe6e 0x1ca 0xe64 0x1ce 0xe5a 0x1cf 0xe4e 0x1d3 0xe42 0x1d3 0xe34 0x1d6 0xe26 0x1d6 0xe17 0x1db 0xe0a 0x1e2 0xdff 0x1e8 0xdf4 0x1f2 0xde9 0x1fc 0xddc 0x20d 0xdcb 0x21c 0xdaa 0x233 0xd71 0x260 0xd23 0x2aa 0xcb1 0x2aa 0xcb1 0x2aa 0xcb1 0x2aa 0xcb1>;
			r_profile_t1_5_500cycle_2 = <0xeb 0x105d 0xeb 0x104f 0xeb 0x1042 0xe9 0x1036 0xe9 0x102a 0xe9 0x101f 0xe9 0x1014 0xe8 0x1009 0xe8 0xffe 0xe8 0xff4 0xe9 0xfec 0xe9 0xfe4 0xe9 0xfdb 0xe6 0xfcf 0xe3 0xfc1 0xe1 0xfb3 0xe1 0xfa6 0xe3 0xf9b 0xe3 0xf91 0xe4 0xf89 0xe8 0xf83 0xeb 0xf7e 0xeb 0xf78 0xeb 0xf72 0xed 0xf6c 0xee 0xf65 0xf0 0xf5e 0xf2 0xf57 0xf3 0xf50 0xf7 0xf49 0xf8 0xf42 0xfc 0xf3b 0xfc 0xf33 0xfc 0xf2a 0xf8 0xf1f 0xf3 0xf13 0xee 0xf07 0xe9 0xefd 0xe8 0xef5 0xe8 0xeef 0xe8 0xee9 0xe8 0xee4 0xe8 0xedf 0xe8 0xedb 0xe9 0xed7 0xe9 0xed3 0xeb 0xed0 0xeb 0xecd 0xee 0xecc 0xe6 0xec9 0xee 0xec6 0xf2 0xec5 0xf3 0xec4 0xf3 0xec2 0xf5 0xec1 0xf8 0xec0 0xfa 0xebf 0xfc 0xebe 0xfd 0xebd 0xff 0xebc 0x102 0xebb 0x104 0xeb9 0x104 0xeb6 0x106 0xeb3 0x106 0xeaf 0x106 0xeaa 0x106 0xea4 0x109 0xe9f 0x10b 0xe99 0x10c 0xe93 0x110 0xe8d 0x111 0xe85 0x113 0xe7c 0x115 0xe72 0x116 0xe66 0x118 0xe59 0x118 0xe4a 0x118 0xe3a 0x115 0xe2a 0x115 0xe1b 0x113 0xe0b 0x113 0xdfb 0x118 0xdeb 0x11d 0xdd6 0x122 0xdb5 0x120 0xd7b 0x12e 0xd2e 0x142 0xcc1 0x189 0xc04 0x189 0xc04 0x189 0xc04>;
			r_profile_t2_500cycle_2 = <0x8a 0x105f 0x8a 0x1051 0x8b 0x1044 0x8c 0x1038 0x8c 0x102c 0x8c 0x1021 0x8d 0x1016 0x8d 0x100b 0x8d 0x1000 0x8e 0xff5 0x8f 0xfec 0x91 0xfe4 0x92 0xfdc 0x8f 0xfd0 0x8e 0xfc3 0x8d 0xfb5 0x8e 0xfa9 0x90 0xf9f 0x92 0xf98 0x94 0xf92 0x92 0xf8b 0x92 0xf84 0x94 0xf7d 0x94 0xf76 0x94 0xf6e 0x95 0xf67 0x96 0xf60 0x97 0xf59 0x98 0xf52 0x9a 0xf4b 0x9c 0xf44 0x9d 0xf3e 0xa0 0xf37 0xa2 0xf30 0xa4 0xf29 0xa4 0xf20 0xa1 0xf14 0x9d 0xf08 0x9a 0xefe 0x98 0xef6 0x98 0xeef 0x98 0xeea 0x98 0xee5 0x98 0xee0 0x98 0xedc 0x99 0xed8 0x99 0xed5 0x99 0xed2 0x9a 0xece 0x9b 0xecc 0x9c 0xec9 0x9d 0xec7 0x9d 0xec5 0x9f 0xec4 0xa0 0xec3 0xa1 0xec2 0xa3 0xec1 0xa4 0xec1 0xa5 0xec0 0xa6 0xec0 0xa8 0xebf 0xa9 0xebe 0xa9 0xebc 0xa8 0xeb8 0xa7 0xeb4 0xa6 0xeb0 0xa7 0xeab 0xa8 0xea7 0xa9 0xea2 0xaa 0xe9e 0xab 0xe99 0xad 0xe95 0xae 0xe90 0xaf 0xe89 0xb0 0xe80 0xb2 0xe76 0xb3 0xe6a 0xb4 0xe5c 0xb5 0xe4c 0xb2 0xe3a 0xae 0xe25 0xab 0xe0e 0xaa 0xdf9 0xab 0xde6 0xaf 0xdd2 0xb3 0xdb6 0xb0 0xd83 0xb2 0xd3b 0xbc 0xcd8 0xbc 0xcd8 0xbc 0xcd8>;
			r_profile_t3_500cycle_2 = <0x76 0x1062 0x76 0x1054 0x77 0x1046 0x77 0x103a 0x77 0x102e 0x77 0x1022 0x77 0x1016 0x78 0x100b 0x77 0x1000 0x78 0xff5 0x78 0xfea 0x78 0xfdf 0x78 0xfd5 0x79 0xfcb 0x79 0xfc1 0x79 0xfb7 0x79 0xfad 0x79 0xfa3 0x7a 0xf9b 0x79 0xf92 0x7a 0xf89 0x7a 0xf80 0x7b 0xf78 0x7b 0xf70 0x7c 0xf68 0x7c 0xf60 0x7d 0xf59 0x7d 0xf51 0x7e 0xf4a 0x80 0xf43 0x80 0xf3b 0x82 0xf34 0x83 0xf2d 0x85 0xf25 0x85 0xf1c 0x84 0xf12 0x82 0xf08 0x7f 0xefe 0x7e 0xef5 0x7d 0xeee 0x7d 0xee8 0x7d 0xee3 0x7d 0xede 0x7c 0xed9 0x7b 0xed4 0x7d 0xed2 0x7d 0xece 0x7d 0xecb 0x7e 0xec8 0x7e 0xec5 0x7e 0xec2 0x7f 0xec0 0x7f 0xebe 0x80 0xebc 0x81 0xeba 0x84 0xeba 0x82 0xeb8 0x83 0xeb7 0x85 0xeb5 0x86 0xeb4 0x85 0xeb0 0x82 0xeaa 0x81 0xea3 0x82 0xe9e 0x83 0xe9a 0x84 0xe95 0x84 0xe90 0x84 0xe8c 0x85 0xe89 0x86 0xe85 0x87 0xe80 0x88 0xe7a 0x88 0xe72 0x8a 0xe69 0x8b 0xe5e 0x90 0xe55 0x91 0xe4b 0x8c 0xe39 0x8b 0xe20 0x8b 0xe07 0x8c 0xdef 0x90 0xdd6 0x93 0xdb8 0x91 0xd87 0x91 0xd3f 0x99 0xcdd 0xb6 0xc45 0x138 0xbab 0x138 0xbab 0x138 0xbab 0x138 0xbab>;
		};

		BAT_NOTIFY {
			compatible = "mediatek,bat_notify";
		};

		bat_comm {
			compatible = "mediatek,battery";
			stop_charging_in_takling = <0x1>;
			talking_recharge_voltage = <0xed8>;
			talking_sync_time = <0x3c>;
			mtk_temperature_recharge_support = <0x1>;
			max_charge_temperature = <0x3c>;
			max_charge_temperature_minus_x_degree = <0x3c>;
			min_charge_temperature = <0x0>;
			min_charge_temperature_plus_x_degree = <0x6>;
			err_charge_temperature = <0xff>;
			v_pre2cc_thres = <0xd48>;
			v_cc2topoff_thres = <0xfd2>;
			recharging_voltage = <0x100e>;
			charging_full_current = <0x96>;
			config_usb_if = <0x0>;
			usb_charger_current_suspend = <0x0>;
			usb_charger_current_unconfigured = <0x1b58>;
			usb_charger_current_configured = <0xc350>;
			usb_charger_current = <0xc350>;
			ac_charger_current = <0x1d4c0>;
			non_std_ac_charger_current = <0x1d4c0>;
			charging_host_charger_current = <0x186a0>;
			apple_0_5a_charger_current = <0xc350>;
			apple_1_0a_charger_current = <0x186a0>;
			apple_2_1a_charger_current = <0x33450>;
			bat_low_temp_protect_enable = <0x0>;
			v_charger_enable = <0x0>;
			v_charger_max = <0x1964>;
			v_charger_min = <0x1130>;
			onehundred_percent_tracking_time = <0xa>;
			npercent_tracking_time = <0x14>;
			sync_to_real_tracking_time = <0x3c>;
			v_0percent_tracking = <0xd48>;
			system_off_voltage = <0xd48>;
			high_battery_voltage_support = <0x0>;
			ac_charger_input_current = <0x186a0>;
			non_std_ac_charger_input_current = <0x186a0>;
			aicl_enable;
			aicl_charging_current_max = <0x2bf20>;
			aicl_step_current = <0x2710>;
			aicl_step_interval = <0x64>;
			aicl_vbus_valid = <0x11f8>;
			aicl_vbus_state_phase = <0xa>;
			ap15_charger_input_current_max = <0x2bf20>;
			ap15_charger_input_current_min = <0x27100>;
			ap15_dock_input_current_max = <0x2bf20>;
			ap15_dock_input_current_min = <0x222e0>;
			max_charging_time = <0x11940>;
			mtk_jeita_standard_support = <0x1>;
			cust_soc_jeita_sync_time = <0x1e>;
			jeita_recharge_voltage = <0x100e>;
			jeita_temp_above_pos_60_cv_voltage = <0x3e8fa0>;
			jeita_temp_pos_45_to_pos_60_cv_voltage = <0x3e8fa0>;
			jeita_temp_pos_10_to_pos_45_cv_voltage = <0x401640>;
			jeita_temp_pos_0_to_pos_10_cv_voltage = <0x401640>;
			jeita_temp_neg_10_to_pos_0_cv_voltage = <0x401640>;
			jeita_temp_below_neg_10_cv_voltage = <0x401640>;
			jeita_neg_10_to_pos_0_full_current = <0x78>;
			jeita_temp_pos_45_to_pos_60_recharge_voltage = <0xfa0>;
			jeita_temp_pos_10_to_pos_45_recharge_voltage = <0x1004>;
			jeita_temp_pos_0_to_pos_10_recharge_voltage = <0x1004>;
			jeita_temp_neg_10_to_pos_0_recharge_voltage = <0x1004>;
			jeita_temp_pos_45_to_pos_60_cc2topoff_threshold = <0xfd2>;
			jeita_temp_pos_10_to_pos_45_cc2topoff_threshold = <0xfd2>;
			jeita_temp_pos_0_to_pos_10_cc2topoff_threshold = <0xfd2>;
			jeita_temp_neg_10_to_pos_0_cc2topoff_threshold = <0xfd2>;
		};

		flashlight@ {
			compatible = "mediatek,camera_flashlight";
		};

		isp_pipemgr {
			compatible = "mediatek,mt8163-isp_pipemgr";
		};

		isp_sysram {
			compatible = "mediatek,mt8163-isp_sysram";
		};

		mtee {
			compatible = "mediatek,mtee";
			clocks = <0x9 0x20>;
			clock-names = "GCPU";
		};
	};

	lcm {
		compatible = "mediatek,lcm";
		pinctrl-names = "default", "lcm_pwr_high", "lcm_pwr_low", "lcm_rst_high", "lcm_rst_low", "lcm_pwr_n_high", "lcm_pwr_n_low";
		pinctrl-0 = <0x63>;
		pinctrl-1 = <0x76>;
		pinctrl-2 = <0x77>;
		pinctrl-3 = <0x78>;
		pinctrl-4 = <0x79>;
		pinctrl-5 = <0x7a>;
		pinctrl-6 = <0x7b>;
		reg-lcm-supply = <0x7c>;
	};

	memory@00000000 {
		device_type = "memory";
		reg = <0x0 0x40000000 0x0 0x20000000>;
	};

	cust_gsensor@0 {
		compatible = "mediatek,mc3410";
		i2c_num = <0x2>;
		i2c_addr = <0x4c>;
		direction = <0x7>;
		power_id = <0xffff>;
		power_vol = <0x0>;
		firlen = <0x0>;
		is_batch_supported = <0x0>;
	};

	cust_gsensor@1 {
		compatible = "mediatek,bma253";
		i2c_num = <0x2>;
		i2c_addr = <0x18>;
		direction = <0x5>;
		power_id = <0xffff>;
		power_vol = <0x0>;
		firlen = <0x0>;
		is_batch_supported = <0x0>;
	};

	cust_gyroscope@0 {
		compatible = "mediatek,lsm6ds3gy";
		i2c_num = <0x2>;
		i2c_addr = <0x6a>;
		direction = <0x0>;
		power_id = <0xffff>;
		power_vol = <0x0>;
		firlen = <0x0>;
		is_batch_supported = <0x0>;
	};

	chosen {
		bootargs = "console=ttyS0,921600n1 root=/dev/ram initrd=0x44000200,0x200000";
	};

	mtcpufreq {
		compatible = "mediatek,mt8163-cpufreq";
		reg-ext-vproc-supply = <0x7d>;
	};

	keypanic {
		compatible = "amzn,keypanic";
		keys_down = "KEY_VOLUMEDOWN", "KEY_VOLUMEUP", "KEY_POWER";
		keys_down_delay = <0x1388>;
		status = "okay";
	};

	hall_sensors {
		compatible = "rohm,hall-ah9250";
		interrupt-parent = <0xd>;
		interrupts = <0x56 0x8>;
		int-gpio = <0xd 0x55 0x0>;
		sensor-name = "hall_sensor_1";
		sensor-num = <0x1>;
	};

	cust_alsps@0 {
		compatible = "mediatek,ltr559";
		i2c_num = <0x2>;
		i2c_addr = <0x23>;
		polling_mode_ps = <0x0>;
		polling_mode_als = <0x1>;
		power_id = <0xffff>;
		power_vol = <0x0>;
		als_level = <0x0 0x101 0x27d 0x403 0x8f9 0x15d4 0x1a4a 0x2c25 0x4fe1 0x64a8 0x7992 0xb1f0 0xe251 0xe251 0xe251>;
		als_value = <0x0 0x84 0x130 0x1f6 0x3ec 0x7d3 0xbbe 0x138e 0x1f44 0x2710 0x2ee0 0x3e80 0x4e20 0x4e20 0x4e20 0x4e20>;
		ps_threshold_high = <0x46>;
		ps_threshold_low = <0x28>;
		is_batch_supported_ps = <0x0>;
		is_batch_supported_als = <0x0>;
	};

	virtual_sensor@0 {
		compatible = "amazon,virtual_sensor-thermal";
		dev_id = <0x0>;
		num_trips = <0x7>;
		mode = <0x0>;
		polling_delay = <0x3e8>;
		governor_name = "virtual_sensor";
		num_tbps = <0x3>;
		temp = <0xadd4 0xaf21 0xb06f 0xb1bc 0xbf68 0xcb20 0xdac0 0xdac0 0xdac0 0xdac0 0xdac0 0xdac0>;
		type = <0x0 0x0 0x0 0x0 0x0 0x0 0x3 0x3 0x3 0x3 0x3 0x3>;
		hyst = <0x0 0x0 0x0 0x0 0x0 0x0 0x0 0x0 0x0 0x0 0x0 0x0>;
		num_cdevs = <0x2>;
		cdev_names = "thermal_budget0", "lcd-backlight0";
	};

	virtual_sensor@1 {
		compatible = "amazon,virtual_sensor-thermal";
		dev_id = <0x1>;
		num_trips = <0x7>;
		mode = <0x0>;
		polling_delay = <0x3e8>;
		governor_name = "virtual_sensor";
		num_tbps = <0x3>;
		temp = <0xc15c 0xc2a9 0xc3f7 0xc544 0xcf08 0xdac0 0xea60 0xea60 0xea60 0xea60 0xea60 0xea60>;
		type = <0x0 0x0 0x0 0x0 0x0 0x0 0x3 0x3 0x3 0x3 0x3 0x3>;
		hyst = <0x0 0x0 0x0 0x0 0x0 0x0 0x0 0x0 0x0 0x0 0x0 0x0>;
		num_cdevs = <0x2>;
		cdev_names = "thermal_budget1", "bcct1";
	};

	thermal_wmt@0 {
		compatible = "amazon,mtkswmt_sensor";
		thermal_wmt,offset = <0x2>;
		thermal_wmt,alpha = <0xd>;
		thermal_wmt,weight = <0x0>;
		select_device = <0x0>;
	};

	thermal_wmt@1 {
		compatible = "amazon,mtkswmt_sensor";
		thermal_wmt,offset = <0x2>;
		thermal_wmt,alpha = <0xd>;
		thermal_wmt,weight = <0x0>;
		select_device = <0x1>;
	};

	thermal_battery@0 {
		compatible = "amazon,mtksbattery_sensor";
		thermal_battery,offset = <0x0>;
		thermal_battery,offset_invert = <0x0>;
		thermal_battery,alpha = <0xa>;
		thermal_battery,weight = <0xc8>;
		select_device = <0x0>;
	};

	thermal_battery@1 {
		compatible = "amazon,mtksbattery_sensor";
		thermal_battery,offset = <0x0>;
		thermal_battery,offset_invert = <0x0>;
		thermal_battery,alpha = <0xa>;
		thermal_battery,weight = <0x64>;
		select_device = <0x1>;
	};

	thermal_gpu@0 {
		compatible = "amazon,mtksgpu_sensor";
		thermal_gpu,offset = <0x64>;
		thermal_gpu,alpha = <0x68>;
		thermal_gpu,weight = <0x0>;
		select_device = <0x0>;
	};

	thermal_gpu@1 {
		compatible = "amazon,mtksgpu_sensor";
		thermal_gpu,offset = <0x64>;
		thermal_gpu,alpha = <0x68>;
		thermal_gpu,weight = <0x0>;
		select_device = <0x1>;
	};

	thermal_pmic@0 {
		compatible = "amazon,mtkspmic_sensor";
		thermal_pmic,offset = <0x4844>;
		thermal_pmic,alpha = <0xa>;
		thermal_pmic,weight = <0xc8>;
		select_device = <0x0>;
	};

	thermal_pmic@1 {
		compatible = "amazon,mtkspmic_sensor";
		thermal_pmic,offset = <0x2ee0>;
		thermal_pmic,alpha = <0xa>;
		thermal_pmic,weight = <0x64>;
		select_device = <0x1>;
	};

	thermal_cpu@0 {
		compatible = "amazon,mtkscpu_sensor";
		thermal_cpu,offset = <0x64>;
		thermal_cpu,alpha = <0x67>;
		thermal_cpu,weight = <0x0>;
		select_device = <0x0>;
	};

	thermal_cpu@1 {
		compatible = "amazon,mtkscpu_sensor";
		thermal_cpu,offset = <0x64>;
		thermal_cpu,alpha = <0x67>;
		thermal_cpu,weight = <0x0>;
		select_device = <0x1>;
	};

	thermistor@00 {
		compatible = "amazon,virtual_sensor_thermistor";
		thermal_thermistor,offset = <0x1f40>;
		thermal_thermistor,offset_invert = <0x0>;
		thermal_thermistor,alpha = <0xa>;
		thermal_thermistor,weight = <0xc8>;
		aux_channel_num = <0x0>;
		select_device = <0x0>;
	};

	thermistor@01 {
		compatible = "amazon,virtual_sensor_thermistor";
		thermal_thermistor,offset = <0x3e8>;
		thermal_thermistor,offset_invert = <0x0>;
		thermal_thermistor,alpha = <0xa>;
		thermal_thermistor,weight = <0x12c>;
		aux_channel_num = <0x0>;
		select_device = <0x1>;
	};

	thermistor@10 {
		compatible = "amazon,virtual_sensor_thermistor";
		thermal_thermistor,offset = <0x32c8>;
		thermal_thermistor,offset_invert = <0x0>;
		thermal_thermistor,alpha = <0xa>;
		thermal_thermistor,weight = <0xc8>;
		aux_channel_num = <0x1>;
		select_device = <0x0>;
	};

	thermistor@11 {
		compatible = "amazon,virtual_sensor_thermistor";
		thermal_thermistor,offset = <0x1388>;
		thermal_thermistor,offset_invert = <0x0>;
		thermal_thermistor,alpha = <0xa>;
		thermal_thermistor,weight = <0x12c>;
		aux_channel_num = <0x1>;
		select_device = <0x1>;
	};

	thermistor@20 {
		compatible = "amazon,virtual_sensor_thermistor";
		thermal_thermistor,offset = <0x1194>;
		thermal_thermistor,offset_invert = <0x0>;
		thermal_thermistor,alpha = <0xa>;
		thermal_thermistor,weight = <0xc8>;
		aux_channel_num = <0x2>;
		select_device = <0x0>;
	};

	thermistor@21 {
		compatible = "amazon,virtual_sensor_thermistor";
		thermal_thermistor,offset = <0x3e8>;
		thermal_thermistor,offset_invert = <0x1>;
		thermal_thermistor,alpha = <0xa>;
		thermal_thermistor,weight = <0xc8>;
		aux_channel_num = <0x2>;
		select_device = <0x1>;
	};

	lcm@0 {
		compatible = "jd,jd936x";
		pinctrl-names = "default", "lcm_pwr_high", "lcm_pwr_low", "lcm_rst_high", "lcm_rst_low", "lcm_pwr_n_high", "lcm_pwr_n_low";
		pinctrl-0 = <0x63>;
		pinctrl-1 = <0x76>;
		pinctrl-2 = <0x77>;
		pinctrl-3 = <0x78>;
		pinctrl-4 = <0x79>;
		pinctrl-5 = <0x7a>;
		pinctrl-6 = <0x7b>;
		reg-lcm-supply = <0x7c>;
	};

	lcm@1 {
		compatible = "nt,nt35521";
		pinctrl-names = "default", "lcm_pwr_high", "lcm_pwr_low", "lcm_rst_high", "lcm_rst_low", "lcm_pwr_n_high", "lcm_pwr_n_low";
		pinctrl-0 = <0x63>;
		pinctrl-1 = <0x76>;
		pinctrl-2 = <0x77>;
		pinctrl-3 = <0x78>;
		pinctrl-4 = <0x79>;
		pinctrl-5 = <0x7a>;
		pinctrl-6 = <0x7b>;
		reg-lcm-supply = <0x7c>;
	};

	keysilent-ota {
		compatible = "amzn,silent-ota";
		keys_down = "KEY_POWER";
		keys_down_delay = <0x0>;
		status = "okay";
	};

	integrity-module {
		compatible = "amzn,integrity-module";
		status = "okay";
	};
};
